VERSION ""

NS_ :

BS_:

BU_: FR_CMR FR_RDR

BO_ 452 L_FR_RDR_StationaryTrack4_50ms: 64 FR_RDR
 SG_ FLR_ST4_CrcVal : 0|16@1+ (1,0) [0|65535] ""  FR_CMR
 SG_ FLR_ST4_AlvCntVal : 16|8@1+ (1,0) [0|255] ""  FR_CMR
 SG_ FLR_ST4_Elevation : 24|3@1+ (1,0) [0|5] ""  FR_CMR
 SG_ FLR_ST4_ElevationConfidence : 27|2@1+ (1,0) [0|3] ""  FR_CMR
 SG_ FLR_ST4_Lifetime : 29|8@1+ (1,0) [0|255] "Cycles"  FR_CMR
 SG_ FLR_ST4_ObjectId : 37|16@1+ (1,0) [0|65535] ""  FR_CMR
 SG_ FLR_ST4_PositionX : 53|12@1+ (0.05,-3) [-3|200] "m"  FR_CMR
 SG_ FLR_ST4_PositionY : 65|12@1- (0.05,0) [-100|100] "m"  FR_CMR
 SG_ FLR_ST4_PredictionCounter : 77|8@1+ (1,0) [0|255] "Cycles"  FR_CMR
 SG_ FLR_ST4_PropertyBits : 85|3@1+ (1,0) [0|7] ""  FR_CMR
 SG_ FLR_ST4_Quality : 88|2@1+ (1,0) [0|3] ""  FR_CMR
 SG_ FLR_ST4_X_Velocity : 90|13@1- (0.05,0) [-120|120] "m/s"  FR_CMR
 SG_ FLR_ST4_Y_Velocity : 103|13@1- (0.05,0) [-120|120] "m/s"  FR_CMR

BO_ 453 L_FR_RDR_StationaryTrack5_50ms: 64 FR_RDR
 SG_ FLR_ST5_CrcVal : 0|16@1+ (1,0) [0|65535] ""  FR_CMR
 SG_ FLR_ST5_AlvCntVal : 16|8@1+ (1,0) [0|255] ""  FR_CMR
 SG_ FLR_ST5_Elevation : 24|3@1+ (1,0) [0|5] ""  FR_CMR
 SG_ FLR_ST5_ElevationConfidence : 27|2@1+ (1,0) [0|3] ""  FR_CMR
 SG_ FLR_ST5_Lifetime : 29|8@1+ (1,0) [0|255] "Cycles"  FR_CMR
 SG_ FLR_ST5_ObjectId : 37|16@1+ (1,0) [0|65535] ""  FR_CMR
 SG_ FLR_ST5_PositionX : 53|12@1+ (0.05,-3) [-3|200] "m"  FR_CMR
 SG_ FLR_ST5_PositionY : 65|12@1- (0.05,0) [-100|100] "m"  FR_CMR
 SG_ FLR_ST5_PredictionCounter : 77|8@1+ (1,0) [0|255] "Cycles"  FR_CMR
 SG_ FLR_ST5_PropertyBits : 85|3@1+ (1,0) [0|7] ""  FR_CMR
 SG_ FLR_ST5_Quality : 88|2@1+ (1,0) [0|3] ""  FR_CMR
 SG_ FLR_ST5_X_Velocity : 90|13@1- (0.05,0) [-120|120] "m/s"  FR_CMR
 SG_ FLR_ST5_Y_Velocity : 103|13@1- (0.05,0) [-120|120] "m/s"  FR_CMR

BO_ 454 L_FR_RDR_StationaryTrack6_50ms: 64 FR_RDR
 SG_ FLR_ST6_CrcVal : 0|16@1+ (1,0) [0|65535] ""  FR_CMR
 SG_ FLR_ST6_AlvCntVal : 16|8@1+ (1,0) [0|255] ""  FR_CMR
 SG_ FLR_ST6_Elevation : 24|3@1+ (1,0) [0|5] ""  FR_CMR
 SG_ FLR_ST6_ElevationConfidence : 27|2@1+ (1,0) [0|3] ""  FR_CMR
 SG_ FLR_ST6_Lifetime : 29|8@1+ (1,0) [0|255] "Cycles"  FR_CMR
 SG_ FLR_ST6_ObjectId : 37|16@1+ (1,0) [0|65535] ""  FR_CMR
 SG_ FLR_ST6_PositionX : 53|12@1+ (0.05,-3) [-3|200] "m"  FR_CMR
 SG_ FLR_ST6_PositionY : 65|12@1- (0.05,0) [-100|100] "m"  FR_CMR
 SG_ FLR_ST6_PredictionCounter : 77|8@1+ (1,0) [0|255] "Cycles"  FR_CMR
 SG_ FLR_ST6_PropertyBits : 85|3@1+ (1,0) [0|7] ""  FR_CMR
 SG_ FLR_ST6_Quality : 88|2@1+ (1,0) [0|3] ""  FR_CMR
 SG_ FLR_ST6_X_Velocity : 90|13@1- (0.05,0) [-120|120] "m/s"  FR_CMR
 SG_ FLR_ST6_Y_Velocity : 103|13@1- (0.05,0) [-120|120] "m/s"  FR_CMR

BO_ 455 L_FR_RDR_StationaryTrack7_50ms: 64 FR_RDR
 SG_ FLR_ST7_CrcVal : 0|16@1+ (1,0) [0|65535] ""  FR_CMR
 SG_ FLR_ST7_AlvCntVal : 16|8@1+ (1,0) [0|255] ""  FR_CMR
 SG_ FLR_ST7_Elevation : 24|3@1+ (1,0) [0|5] ""  FR_CMR
 SG_ FLR_ST7_ElevationConfidence : 27|2@1+ (1,0) [0|3] ""  FR_CMR
 SG_ FLR_ST7_Lifetime : 29|8@1+ (1,0) [0|255] "Cycles"  FR_CMR
 SG_ FLR_ST7_ObjectId : 37|16@1+ (1,0) [0|65535] ""  FR_CMR
 SG_ FLR_ST7_PositionX : 53|12@1+ (0.05,-3) [-3|200] "m"  FR_CMR
 SG_ FLR_ST7_PositionY : 65|12@1- (0.05,0) [-100|100] "m"  FR_CMR
 SG_ FLR_ST7_PredictionCounter : 77|8@1+ (1,0) [0|255] "Cycles"  FR_CMR
 SG_ FLR_ST7_PropertyBits : 85|3@1+ (1,0) [0|7] ""  FR_CMR
 SG_ FLR_ST7_Quality : 88|2@1+ (1,0) [0|3] ""  FR_CMR
 SG_ FLR_ST7_X_Velocity : 90|13@1- (0.05,0) [-120|120] "m/s"  FR_CMR
 SG_ FLR_ST7_Y_Velocity : 103|13@1- (0.05,0) [-120|120] "m/s"  FR_CMR

BO_ 456 L_FR_RDR_StationaryTrack8_50ms: 64 FR_RDR
 SG_ FLR_ST8_CrcVal : 0|16@1+ (1,0) [0|65535] ""  FR_CMR
 SG_ FLR_ST8_AlvCntVal : 16|8@1+ (1,0) [0|255] ""  FR_CMR
 SG_ FLR_ST8_Elevation : 24|3@1+ (1,0) [0|5] ""  FR_CMR
 SG_ FLR_ST8_ElevationConfidence : 27|2@1+ (1,0) [0|3] ""  FR_CMR
 SG_ FLR_ST8_Lifetime : 29|8@1+ (1,0) [0|255] "Cycles"  FR_CMR
 SG_ FLR_ST8_ObjectId : 37|16@1+ (1,0) [0|65535] ""  FR_CMR
 SG_ FLR_ST8_PositionX : 53|12@1+ (0.05,-3) [-3|200] "m"  FR_CMR
 SG_ FLR_ST8_PositionY : 65|12@1- (0.05,0) [-100|100] "m"  FR_CMR
 SG_ FLR_ST8_PredictionCounter : 77|8@1+ (1,0) [0|255] "Cycles"  FR_CMR
 SG_ FLR_ST8_PropertyBits : 85|3@1+ (1,0) [0|7] ""  FR_CMR
 SG_ FLR_ST8_Quality : 88|2@1+ (1,0) [0|3] ""  FR_CMR
 SG_ FLR_ST8_X_Velocity : 90|13@1- (0.05,0) [-120|120] "m/s"  FR_CMR
 SG_ FLR_ST8_Y_Velocity : 103|13@1- (0.05,0) [-120|120] "m/s"  FR_CMR

BO_ 457 L_FR_RDR_StationaryTrack9_50ms: 64 FR_RDR
 SG_ FLR_ST9_CrcVal : 0|16@1+ (1,0) [0|65535] ""  FR_CMR
 SG_ FLR_ST9_AlvCntVal : 16|8@1+ (1,0) [0|255] ""  FR_CMR
 SG_ FLR_ST9_Elevation : 24|3@1+ (1,0) [0|5] ""  FR_CMR
 SG_ FLR_ST9_ElevationConfidence : 27|2@1+ (1,0) [0|3] ""  FR_CMR
 SG_ FLR_ST9_Lifetime : 29|8@1+ (1,0) [0|255] "Cycles"  FR_CMR
 SG_ FLR_ST9_ObjectId : 37|16@1+ (1,0) [0|65535] ""  FR_CMR
 SG_ FLR_ST9_PositionX : 53|12@1+ (0.05,-3) [-3|200] "m"  FR_CMR
 SG_ FLR_ST9_PositionY : 65|12@1- (0.05,0) [-100|100] "m"  FR_CMR
 SG_ FLR_ST9_PredictionCounter : 77|8@1+ (1,0) [0|255] "Cycles"  FR_CMR
 SG_ FLR_ST9_PropertyBits : 85|3@1+ (1,0) [0|7] ""  FR_CMR
 SG_ FLR_ST9_Quality : 88|2@1+ (1,0) [0|3] ""  FR_CMR
 SG_ FLR_ST9_X_Velocity : 90|13@1- (0.05,0) [-120|120] "m/s"  FR_CMR
 SG_ FLR_ST9_Y_Velocity : 103|13@1- (0.05,0) [-120|120] "m/s"  FR_CMR

BO_ 458 L_FR_RDR_StationaryTrack10_50ms: 64 FR_RDR
 SG_ FLR_ST10_CrcVal : 0|16@1+ (1,0) [0|65535] ""  FR_CMR
 SG_ FLR_ST10_AlvCntVal : 16|8@1+ (1,0) [0|255] ""  FR_CMR
 SG_ FLR_ST10_Elevation : 24|3@1+ (1,0) [0|5] ""  FR_CMR
 SG_ FLR_ST10_ElevationConfidence : 27|2@1+ (1,0) [0|3] ""  FR_CMR
 SG_ FLR_ST10_Lifetime : 29|8@1+ (1,0) [0|255] "Cycles"  FR_CMR
 SG_ FLR_ST10_ObjectId : 37|16@1+ (1,0) [0|65535] ""  FR_CMR
 SG_ FLR_ST10_PositionX : 53|12@1+ (0.05,-3) [-3|200] "m"  FR_CMR
 SG_ FLR_ST10_PositionY : 65|12@1- (0.05,0) [-100|100] "m"  FR_CMR
 SG_ FLR_ST10_PredictionCounter : 77|8@1+ (1,0) [0|255] "Cycles"  FR_CMR
 SG_ FLR_ST10_PropertyBits : 85|3@1+ (1,0) [0|7] ""  FR_CMR
 SG_ FLR_ST10_Quality : 88|2@1+ (1,0) [0|3] ""  FR_CMR
 SG_ FLR_ST10_X_Velocity : 90|13@1- (0.05,0) [-120|120] "m/s"  FR_CMR
 SG_ FLR_ST10_Y_Velocity : 103|13@1- (0.05,0) [-120|120] "m/s"  FR_CMR

BO_ 459 L_FR_RDR_StationaryTrack11_50ms: 64 FR_RDR
 SG_ FLR_ST11_CrcVal : 0|16@1+ (1,0) [0|65535] ""  FR_CMR
 SG_ FLR_ST11_AlvCntVal : 16|8@1+ (1,0) [0|255] ""  FR_CMR
 SG_ FLR_ST11_Elevation : 24|3@1+ (1,0) [0|5] ""  FR_CMR
 SG_ FLR_ST11_ElevationConfidence : 27|2@1+ (1,0) [0|3] ""  FR_CMR
 SG_ FLR_ST11_Lifetime : 29|8@1+ (1,0) [0|255] "Cycles"  FR_CMR
 SG_ FLR_ST11_ObjectId : 37|16@1+ (1,0) [0|65535] ""  FR_CMR
 SG_ FLR_ST11_PositionX : 53|12@1+ (0.05,-3) [-3|200] "m"  FR_CMR
 SG_ FLR_ST11_PositionY : 65|12@1- (0.05,0) [-100|100] "m"  FR_CMR
 SG_ FLR_ST11_PredictionCounter : 77|8@1+ (1,0) [0|255] "Cycles"  FR_CMR
 SG_ FLR_ST11_PropertyBits : 85|3@1+ (1,0) [0|7] ""  FR_CMR
 SG_ FLR_ST11_Quality : 88|2@1+ (1,0) [0|3] ""  FR_CMR
 SG_ FLR_ST11_X_Velocity : 90|13@1- (0.05,0) [-120|120] "m/s"  FR_CMR
 SG_ FLR_ST11_Y_Velocity : 103|13@1- (0.05,0) [-120|120] "m/s"  FR_CMR

BO_ 460 L_FR_RDR_StationaryTrack12_50ms: 64 FR_RDR
 SG_ FLR_ST12_CrcVal : 0|16@1+ (1,0) [0|65535] ""  FR_CMR
 SG_ FLR_ST12_AlvCntVal : 16|8@1+ (1,0) [0|255] ""  FR_CMR
 SG_ FLR_ST12_Elevation : 24|3@1+ (1,0) [0|5] ""  FR_CMR
 SG_ FLR_ST12_ElevationConfidence : 27|2@1+ (1,0) [0|3] ""  FR_CMR
 SG_ FLR_ST12_Lifetime : 29|8@1+ (1,0) [0|255] "Cycles"  FR_CMR
 SG_ FLR_ST12_ObjectId : 37|16@1+ (1,0) [0|65535] ""  FR_CMR
 SG_ FLR_ST12_PositionX : 53|12@1+ (0.05,-3) [-3|200] "m"  FR_CMR
 SG_ FLR_ST12_PositionY : 65|12@1- (0.05,0) [-100|100] "m"  FR_CMR
 SG_ FLR_ST12_PredictionCounter : 77|8@1+ (1,0) [0|255] "Cycles"  FR_CMR
 SG_ FLR_ST12_PropertyBits : 85|3@1+ (1,0) [0|7] ""  FR_CMR
 SG_ FLR_ST12_Quality : 88|2@1+ (1,0) [0|3] ""  FR_CMR
 SG_ FLR_ST12_X_Velocity : 90|13@1- (0.05,0) [-120|120] "m/s"  FR_CMR
 SG_ FLR_ST12_Y_Velocity : 103|13@1- (0.05,0) [-120|120] "m/s"  FR_CMR

BO_ 461 L_FR_RDR_StationaryTrack13_50ms: 64 FR_RDR
 SG_ FLR_ST13_CrcVal : 0|16@1+ (1,0) [0|65535] ""  FR_CMR
 SG_ FLR_ST13_AlvCntVal : 16|8@1+ (1,0) [0|255] ""  FR_CMR
 SG_ FLR_ST13_Elevation : 24|3@1+ (1,0) [0|5] ""  FR_CMR
 SG_ FLR_ST13_ElevationConfidence : 27|2@1+ (1,0) [0|3] ""  FR_CMR
 SG_ FLR_ST13_Lifetime : 29|8@1+ (1,0) [0|255] "Cycles"  FR_CMR
 SG_ FLR_ST13_ObjectId : 37|16@1+ (1,0) [0|65535] ""  FR_CMR
 SG_ FLR_ST13_PositionX : 53|12@1+ (0.05,-3) [-3|200] "m"  FR_CMR
 SG_ FLR_ST13_PositionY : 65|12@1- (0.05,0) [-100|100] "m"  FR_CMR
 SG_ FLR_ST13_PredictionCounter : 77|8@1+ (1,0) [0|255] "Cycles"  FR_CMR
 SG_ FLR_ST13_PropertyBits : 85|3@1+ (1,0) [0|7] ""  FR_CMR
 SG_ FLR_ST13_Quality : 88|2@1+ (1,0) [0|3] ""  FR_CMR
 SG_ FLR_ST13_X_Velocity : 90|13@1- (0.05,0) [-120|120] "m/s"  FR_CMR
 SG_ FLR_ST13_Y_Velocity : 103|13@1- (0.05,0) [-120|120] "m/s"  FR_CMR

BO_ 462 L_FR_RDR_StationaryTrack14_50ms: 64 FR_RDR
 SG_ FLR_ST14_CrcVal : 0|16@1+ (1,0) [0|65535] ""  FR_CMR
 SG_ FLR_ST14_AlvCntVal : 16|8@1+ (1,0) [0|255] ""  FR_CMR
 SG_ FLR_ST14_Elevation : 24|3@1+ (1,0) [0|5] ""  FR_CMR
 SG_ FLR_ST14_ElevationConfidence : 27|2@1+ (1,0) [0|3] ""  FR_CMR
 SG_ FLR_ST14_Lifetime : 29|8@1+ (1,0) [0|255] "Cycles"  FR_CMR
 SG_ FLR_ST14_ObjectId : 37|16@1+ (1,0) [0|65535] ""  FR_CMR
 SG_ FLR_ST14_PositionX : 53|12@1+ (0.05,-3) [-3|200] "m"  FR_CMR
 SG_ FLR_ST14_PositionY : 65|12@1- (0.05,0) [-100|100] "m"  FR_CMR
 SG_ FLR_ST14_PredictionCounter : 77|8@1+ (1,0) [0|255] "Cycles"  FR_CMR
 SG_ FLR_ST14_PropertyBits : 85|3@1+ (1,0) [0|7] ""  FR_CMR
 SG_ FLR_ST14_Quality : 88|2@1+ (1,0) [0|3] ""  FR_CMR
 SG_ FLR_ST14_X_Velocity : 90|13@1- (0.05,0) [-120|120] "m/s"  FR_CMR
 SG_ FLR_ST14_Y_Velocity : 103|13@1- (0.05,0) [-120|120] "m/s"  FR_CMR

BO_ 463 L_FR_RDR_StationaryTrack15_50ms: 64 FR_RDR
 SG_ FLR_ST15_CrcVal : 0|16@1+ (1,0) [0|65535] ""  FR_CMR
 SG_ FLR_ST15_AlvCntVal : 16|8@1+ (1,0) [0|255] ""  FR_CMR
 SG_ FLR_ST15_Elevation : 24|3@1+ (1,0) [0|5] ""  FR_CMR
 SG_ FLR_ST15_ElevationConfidence : 27|2@1+ (1,0) [0|3] ""  FR_CMR
 SG_ FLR_ST15_Lifetime : 29|8@1+ (1,0) [0|255] "Cycles"  FR_CMR
 SG_ FLR_ST15_ObjectId : 37|16@1+ (1,0) [0|65535] ""  FR_CMR
 SG_ FLR_ST15_PositionX : 53|12@1+ (0.05,-3) [-3|200] "m"  FR_CMR
 SG_ FLR_ST15_PositionY : 65|12@1- (0.05,0) [-100|100] "m"  FR_CMR
 SG_ FLR_ST15_PredictionCounter : 77|8@1+ (1,0) [0|255] "Cycles"  FR_CMR
 SG_ FLR_ST15_PropertyBits : 85|3@1+ (1,0) [0|7] ""  FR_CMR
 SG_ FLR_ST15_Quality : 88|2@1+ (1,0) [0|3] ""  FR_CMR
 SG_ FLR_ST15_X_Velocity : 90|13@1- (0.05,0) [-120|120] "m/s"  FR_CMR
 SG_ FLR_ST15_Y_Velocity : 103|13@1- (0.05,0) [-120|120] "m/s"  FR_CMR

BO_ 464 L_FR_RDR_StationaryTrack16_50ms: 64 FR_RDR
 SG_ FLR_ST16_CrcVal : 0|16@1+ (1,0) [0|65535] ""  FR_CMR
 SG_ FLR_ST16_AlvCntVal : 16|8@1+ (1,0) [0|255] ""  FR_CMR
 SG_ FLR_ST16_Elevation : 24|3@1+ (1,0) [0|5] ""  FR_CMR
 SG_ FLR_ST16_ElevationConfidence : 27|2@1+ (1,0) [0|3] ""  FR_CMR
 SG_ FLR_ST16_Lifetime : 29|8@1+ (1,0) [0|255] "Cycles"  FR_CMR
 SG_ FLR_ST16_ObjectId : 37|16@1+ (1,0) [0|65535] ""  FR_CMR
 SG_ FLR_ST16_PositionX : 53|12@1+ (0.05,-3) [-3|200] "m"  FR_CMR
 SG_ FLR_ST16_PositionY : 65|12@1- (0.05,0) [-100|100] "m"  FR_CMR
 SG_ FLR_ST16_PredictionCounter : 77|8@1+ (1,0) [0|255] "Cycles"  FR_CMR
 SG_ FLR_ST16_PropertyBits : 85|3@1+ (1,0) [0|7] ""  FR_CMR
 SG_ FLR_ST16_Quality : 88|2@1+ (1,0) [0|3] ""  FR_CMR
 SG_ FLR_ST16_X_Velocity : 90|13@1- (0.05,0) [-120|120] "m/s"  FR_CMR
 SG_ FLR_ST16_Y_Velocity : 103|13@1- (0.05,0) [-120|120] "m/s"  FR_CMR

BO_ 465 L_FR_RDR_StationaryTrack17_50ms: 64 FR_RDR
 SG_ FLR_ST17_CrcVal : 0|16@1+ (1,0) [0|65535] ""  FR_CMR
 SG_ FLR_ST17_AlvCntVal : 16|8@1+ (1,0) [0|255] ""  FR_CMR
 SG_ FLR_ST17_Elevation : 24|3@1+ (1,0) [0|5] ""  FR_CMR
 SG_ FLR_ST17_ElevationConfidence : 27|2@1+ (1,0) [0|3] ""  FR_CMR
 SG_ FLR_ST17_Lifetime : 29|8@1+ (1,0) [0|255] "Cycles"  FR_CMR
 SG_ FLR_ST17_ObjectId : 37|16@1+ (1,0) [0|65535] ""  FR_CMR
 SG_ FLR_ST17_PositionX : 53|12@1+ (0.05,-3) [-3|200] "m"  FR_CMR
 SG_ FLR_ST17_PositionY : 65|12@1- (0.05,0) [-100|100] "m"  FR_CMR
 SG_ FLR_ST17_PredictionCounter : 77|8@1+ (1,0) [0|255] "Cycles"  FR_CMR
 SG_ FLR_ST17_PropertyBits : 85|3@1+ (1,0) [0|7] ""  FR_CMR
 SG_ FLR_ST17_Quality : 88|2@1+ (1,0) [0|3] ""  FR_CMR
 SG_ FLR_ST17_X_Velocity : 90|13@1- (0.05,0) [-120|120] "m/s"  FR_CMR
 SG_ FLR_ST17_Y_Velocity : 103|13@1- (0.05,0) [-120|120] "m/s"  FR_CMR

BO_ 466 L_FR_RDR_StationaryTrack18_50ms: 64 FR_RDR
 SG_ FLR_ST18_CrcVal : 0|16@1+ (1,0) [0|65535] ""  FR_CMR
 SG_ FLR_ST18_AlvCntVal : 16|8@1+ (1,0) [0|255] ""  FR_CMR
 SG_ FLR_ST18_Elevation : 24|3@1+ (1,0) [0|5] ""  FR_CMR
 SG_ FLR_ST18_ElevationConfidence : 27|2@1+ (1,0) [0|3] ""  FR_CMR
 SG_ FLR_ST18_Lifetime : 29|8@1+ (1,0) [0|255] "Cycles"  FR_CMR
 SG_ FLR_ST18_ObjectId : 37|16@1+ (1,0) [0|65535] ""  FR_CMR
 SG_ FLR_ST18_PositionX : 53|12@1+ (0.05,-3) [-3|200] "m"  FR_CMR
 SG_ FLR_ST18_PositionY : 65|12@1- (0.05,0) [-100|100] "m"  FR_CMR
 SG_ FLR_ST18_PredictionCounter : 77|8@1+ (1,0) [0|255] "Cycles"  FR_CMR
 SG_ FLR_ST18_PropertyBits : 85|3@1+ (1,0) [0|7] ""  FR_CMR
 SG_ FLR_ST18_Quality : 88|2@1+ (1,0) [0|3] ""  FR_CMR
 SG_ FLR_ST18_X_Velocity : 90|13@1- (0.05,0) [-120|120] "m/s"  FR_CMR
 SG_ FLR_ST18_Y_Velocity : 103|13@1- (0.05,0) [-120|120] "m/s"  FR_CMR

BO_ 467 L_FR_RDR_StationaryTrack19_50ms: 64 FR_RDR
 SG_ FLR_ST19_CrcVal : 0|16@1+ (1,0) [0|65535] ""  FR_CMR
 SG_ FLR_ST19_AlvCntVal : 16|8@1+ (1,0) [0|255] ""  FR_CMR
 SG_ FLR_ST19_Elevation : 24|3@1+ (1,0) [0|5] ""  FR_CMR
 SG_ FLR_ST19_ElevationConfidence : 27|2@1+ (1,0) [0|3] ""  FR_CMR
 SG_ FLR_ST19_Lifetime : 29|8@1+ (1,0) [0|255] "Cycles"  FR_CMR
 SG_ FLR_ST19_ObjectId : 37|16@1+ (1,0) [0|65535] ""  FR_CMR
 SG_ FLR_ST19_PositionX : 53|12@1+ (0.05,-3) [-3|200] "m"  FR_CMR
 SG_ FLR_ST19_PositionY : 65|12@1- (0.05,0) [-100|100] "m"  FR_CMR
 SG_ FLR_ST19_PredictionCounter : 77|8@1+ (1,0) [0|255] "Cycles"  FR_CMR
 SG_ FLR_ST19_PropertyBits : 85|3@1+ (1,0) [0|7] ""  FR_CMR
 SG_ FLR_ST19_Quality : 88|2@1+ (1,0) [0|3] ""  FR_CMR
 SG_ FLR_ST19_X_Velocity : 90|13@1- (0.05,0) [-120|120] "m/s"  FR_CMR
 SG_ FLR_ST19_Y_Velocity : 103|13@1- (0.05,0) [-120|120] "m/s"  FR_CMR

BO_ 468 L_FR_RDR_StationaryTrack20_50ms: 64 FR_RDR
 SG_ FLR_ST20_CrcVal : 0|16@1+ (1,0) [0|65535] ""  FR_CMR
 SG_ FLR_ST20_AlvCntVal : 16|8@1+ (1,0) [0|255] ""  FR_CMR
 SG_ FLR_ST20_Elevation : 24|3@1+ (1,0) [0|5] ""  FR_CMR
 SG_ FLR_ST20_ElevationConfidence : 27|2@1+ (1,0) [0|3] ""  FR_CMR
 SG_ FLR_ST20_Lifetime : 29|8@1+ (1,0) [0|255] "Cycles"  FR_CMR
 SG_ FLR_ST20_ObjectId : 37|16@1+ (1,0) [0|65535] ""  FR_CMR
 SG_ FLR_ST20_PositionX : 53|12@1+ (0.05,-3) [-3|200] "m"  FR_CMR
 SG_ FLR_ST20_PositionY : 65|12@1- (0.05,0) [-100|100] "m"  FR_CMR
 SG_ FLR_ST20_PredictionCounter : 77|8@1+ (1,0) [0|255] "Cycles"  FR_CMR
 SG_ FLR_ST20_PropertyBits : 85|3@1+ (1,0) [0|7] ""  FR_CMR
 SG_ FLR_ST20_Quality : 88|2@1+ (1,0) [0|3] ""  FR_CMR
 SG_ FLR_ST20_X_Velocity : 90|13@1- (0.05,0) [-120|120] "m/s"  FR_CMR
 SG_ FLR_ST20_Y_Velocity : 103|13@1- (0.05,0) [-120|120] "m/s"  FR_CMR

BO_ 469 L_FR_RDR_StationaryTrack21_50ms: 64 FR_RDR
 SG_ FLR_ST21_CrcVal : 0|16@1+ (1,0) [0|65535] ""  FR_CMR
 SG_ FLR_ST21_AlvCntVal : 16|8@1+ (1,0) [0|255] ""  FR_CMR
 SG_ FLR_ST21_Elevation : 24|3@1+ (1,0) [0|5] ""  FR_CMR
 SG_ FLR_ST21_ElevationConfidence : 27|2@1+ (1,0) [0|3] ""  FR_CMR
 SG_ FLR_ST21_Lifetime : 29|8@1+ (1,0) [0|255] "Cycles"  FR_CMR
 SG_ FLR_ST21_ObjectId : 37|16@1+ (1,0) [0|65535] ""  FR_CMR
 SG_ FLR_ST21_PositionX : 53|12@1+ (0.05,-3) [-3|200] "m"  FR_CMR
 SG_ FLR_ST21_PositionY : 65|12@1- (0.05,0) [-100|100] "m"  FR_CMR
 SG_ FLR_ST21_PredictionCounter : 77|8@1+ (1,0) [0|255] "Cycles"  FR_CMR
 SG_ FLR_ST21_PropertyBits : 85|3@1+ (1,0) [0|7] ""  FR_CMR
 SG_ FLR_ST21_Quality : 88|2@1+ (1,0) [0|3] ""  FR_CMR
 SG_ FLR_ST21_X_Velocity : 90|13@1- (0.05,0) [-120|120] "m/s"  FR_CMR
 SG_ FLR_ST21_Y_Velocity : 103|13@1- (0.05,0) [-120|120] "m/s"  FR_CMR

BO_ 470 L_FR_RDR_StationaryTrack22_50ms: 64 FR_RDR
 SG_ FLR_ST22_CrcVal : 0|16@1+ (1,0) [0|65535] ""  FR_CMR
 SG_ FLR_ST22_AlvCntVal : 16|8@1+ (1,0) [0|255] ""  FR_CMR
 SG_ FLR_ST22_Elevation : 24|3@1+ (1,0) [0|5] ""  FR_CMR
 SG_ FLR_ST22_ElevationConfidence : 27|2@1+ (1,0) [0|3] ""  FR_CMR
 SG_ FLR_ST22_Lifetime : 29|8@1+ (1,0) [0|255] "Cycles"  FR_CMR
 SG_ FLR_ST22_ObjectId : 37|16@1+ (1,0) [0|65535] ""  FR_CMR
 SG_ FLR_ST22_PositionX : 53|12@1+ (0.05,-3) [-3|200] "m"  FR_CMR
 SG_ FLR_ST22_PositionY : 65|12@1- (0.05,0) [-100|100] "m"  FR_CMR
 SG_ FLR_ST22_PredictionCounter : 77|8@1+ (1,0) [0|255] "Cycles"  FR_CMR
 SG_ FLR_ST22_PropertyBits : 85|3@1+ (1,0) [0|7] ""  FR_CMR
 SG_ FLR_ST22_Quality : 88|2@1+ (1,0) [0|3] ""  FR_CMR
 SG_ FLR_ST22_X_Velocity : 90|13@1- (0.05,0) [-120|120] "m/s"  FR_CMR
 SG_ FLR_ST22_Y_Velocity : 103|13@1- (0.05,0) [-120|120] "m/s"  FR_CMR

BO_ 471 L_FR_RDR_StationaryTrack23_50ms: 64 FR_RDR
 SG_ FLR_ST23_CrcVal : 0|16@1+ (1,0) [0|65535] ""  FR_CMR
 SG_ FLR_ST23_AlvCntVal : 16|8@1+ (1,0) [0|255] ""  FR_CMR
 SG_ FLR_ST23_Elevation : 24|3@1+ (1,0) [0|5] ""  FR_CMR
 SG_ FLR_ST23_ElevationConfidence : 27|2@1+ (1,0) [0|3] ""  FR_CMR
 SG_ FLR_ST23_Lifetime : 29|8@1+ (1,0) [0|255] "Cycles"  FR_CMR
 SG_ FLR_ST23_ObjectId : 37|16@1+ (1,0) [0|65535] ""  FR_CMR
 SG_ FLR_ST23_PositionX : 53|12@1+ (0.05,-3) [-3|200] "m"  FR_CMR
 SG_ FLR_ST23_PositionY : 65|12@1- (0.05,0) [-100|100] "m"  FR_CMR
 SG_ FLR_ST23_PredictionCounter : 77|8@1+ (1,0) [0|255] "Cycles"  FR_CMR
 SG_ FLR_ST23_PropertyBits : 85|3@1+ (1,0) [0|7] ""  FR_CMR
 SG_ FLR_ST23_Quality : 88|2@1+ (1,0) [0|3] ""  FR_CMR
 SG_ FLR_ST23_X_Velocity : 90|13@1- (0.05,0) [-120|120] "m/s"  FR_CMR
 SG_ FLR_ST23_Y_Velocity : 103|13@1- (0.05,0) [-120|120] "m/s"  FR_CMR

BO_ 472 L_FR_RDR_StationaryTrack24_50ms: 64 FR_RDR
 SG_ FLR_ST24_CrcVal : 0|16@1+ (1,0) [0|65535] ""  FR_CMR
 SG_ FLR_ST24_AlvCntVal : 16|8@1+ (1,0) [0|255] ""  FR_CMR
 SG_ FLR_ST24_Elevation : 24|3@1+ (1,0) [0|5] ""  FR_CMR
 SG_ FLR_ST24_ElevationConfidence : 27|2@1+ (1,0) [0|3] ""  FR_CMR
 SG_ FLR_ST24_Lifetime : 29|8@1+ (1,0) [0|255] "Cycles"  FR_CMR
 SG_ FLR_ST24_ObjectId : 37|16@1+ (1,0) [0|65535] ""  FR_CMR
 SG_ FLR_ST24_PositionX : 53|12@1+ (0.05,-3) [-3|200] "m"  FR_CMR
 SG_ FLR_ST24_PositionY : 65|12@1- (0.05,0) [-100|100] "m"  FR_CMR
 SG_ FLR_ST24_PredictionCounter : 77|8@1+ (1,0) [0|255] "Cycles"  FR_CMR
 SG_ FLR_ST24_PropertyBits : 85|3@1+ (1,0) [0|7] ""  FR_CMR
 SG_ FLR_ST24_Quality : 88|2@1+ (1,0) [0|3] ""  FR_CMR
 SG_ FLR_ST24_X_Velocity : 90|13@1- (0.05,0) [-120|120] "m/s"  FR_CMR
 SG_ FLR_ST24_Y_Velocity : 103|13@1- (0.05,0) [-120|120] "m/s"  FR_CMR

BO_ 473 L_FR_RDR_StationaryTrack25_50ms: 64 FR_RDR
 SG_ FLR_ST25_CrcVal : 0|16@1+ (1,0) [0|65535] ""  FR_CMR
 SG_ FLR_ST25_AlvCntVal : 16|8@1+ (1,0) [0|255] ""  FR_CMR
 SG_ FLR_ST25_Elevation : 24|3@1+ (1,0) [0|5] ""  FR_CMR
 SG_ FLR_ST25_ElevationConfidence : 27|2@1+ (1,0) [0|3] ""  FR_CMR
 SG_ FLR_ST25_Lifetime : 29|8@1+ (1,0) [0|255] "Cycles"  FR_CMR
 SG_ FLR_ST25_ObjectId : 37|16@1+ (1,0) [0|65535] ""  FR_CMR
 SG_ FLR_ST25_PositionX : 53|12@1+ (0.05,-3) [-3|200] "m"  FR_CMR
 SG_ FLR_ST25_PositionY : 65|12@1- (0.05,0) [-100|100] "m"  FR_CMR
 SG_ FLR_ST25_PredictionCounter : 77|8@1+ (1,0) [0|255] "Cycles"  FR_CMR
 SG_ FLR_ST25_PropertyBits : 85|3@1+ (1,0) [0|7] ""  FR_CMR
 SG_ FLR_ST25_Quality : 88|2@1+ (1,0) [0|3] ""  FR_CMR
 SG_ FLR_ST25_X_Velocity : 90|13@1- (0.05,0) [-120|120] "m/s"  FR_CMR
 SG_ FLR_ST25_Y_Velocity : 103|13@1- (0.05,0) [-120|120] "m/s"  FR_CMR

BO_ 474 L_FR_RDR_StationaryTrack26_50ms: 64 FR_RDR
 SG_ FLR_ST26_CrcVal : 0|16@1+ (1,0) [0|65535] ""  FR_CMR
 SG_ FLR_ST26_AlvCntVal : 16|8@1+ (1,0) [0|255] ""  FR_CMR
 SG_ FLR_ST26_Elevation : 24|3@1+ (1,0) [0|5] ""  FR_CMR
 SG_ FLR_ST26_ElevationConfidence : 27|2@1+ (1,0) [0|3] ""  FR_CMR
 SG_ FLR_ST26_Lifetime : 29|8@1+ (1,0) [0|255] "Cycles"  FR_CMR
 SG_ FLR_ST26_ObjectId : 37|16@1+ (1,0) [0|65535] ""  FR_CMR
 SG_ FLR_ST26_PositionX : 53|12@1+ (0.05,-3) [-3|200] "m"  FR_CMR
 SG_ FLR_ST26_PositionY : 65|12@1- (0.05,0) [-100|100] "m"  FR_CMR
 SG_ FLR_ST26_PredictionCounter : 77|8@1+ (1,0) [0|255] "Cycles"  FR_CMR
 SG_ FLR_ST26_PropertyBits : 85|3@1+ (1,0) [0|7] ""  FR_CMR
 SG_ FLR_ST26_Quality : 88|2@1+ (1,0) [0|3] ""  FR_CMR
 SG_ FLR_ST26_X_Velocity : 90|13@1- (0.05,0) [-120|120] "m/s"  FR_CMR
 SG_ FLR_ST26_Y_Velocity : 103|13@1- (0.05,0) [-120|120] "m/s"  FR_CMR

BO_ 475 L_FR_RDR_StationaryTrack27_50ms: 64 FR_RDR
 SG_ FLR_ST27_CrcVal : 0|16@1+ (1,0) [0|65535] ""  FR_CMR
 SG_ FLR_ST27_AlvCntVal : 16|8@1+ (1,0) [0|255] ""  FR_CMR
 SG_ FLR_ST27_Elevation : 24|3@1+ (1,0) [0|5] ""  FR_CMR
 SG_ FLR_ST27_ElevationConfidence : 27|2@1+ (1,0) [0|3] ""  FR_CMR
 SG_ FLR_ST27_Lifetime : 29|8@1+ (1,0) [0|255] "Cycles"  FR_CMR
 SG_ FLR_ST27_ObjectId : 37|16@1+ (1,0) [0|65535] ""  FR_CMR
 SG_ FLR_ST27_PositionX : 53|12@1+ (0.05,-3) [-3|200] "m"  FR_CMR
 SG_ FLR_ST27_PositionY : 65|12@1- (0.05,0) [-100|100] "m"  FR_CMR
 SG_ FLR_ST27_PredictionCounter : 77|8@1+ (1,0) [0|255] "Cycles"  FR_CMR
 SG_ FLR_ST27_PropertyBits : 85|3@1+ (1,0) [0|7] ""  FR_CMR
 SG_ FLR_ST27_Quality : 88|2@1+ (1,0) [0|3] ""  FR_CMR
 SG_ FLR_ST27_X_Velocity : 90|13@1- (0.05,0) [-120|120] "m/s"  FR_CMR
 SG_ FLR_ST27_Y_Velocity : 103|13@1- (0.05,0) [-120|120] "m/s"  FR_CMR

BO_ 476 L_FR_RDR_StationaryTrack28_50ms: 64 FR_RDR
 SG_ FLR_ST28_CrcVal : 0|16@1+ (1,0) [0|65535] ""  FR_CMR
 SG_ FLR_ST28_AlvCntVal : 16|8@1+ (1,0) [0|255] ""  FR_CMR
 SG_ FLR_ST28_Elevation : 24|3@1+ (1,0) [0|5] ""  FR_CMR
 SG_ FLR_ST28_ElevationConfidence : 27|2@1+ (1,0) [0|3] ""  FR_CMR
 SG_ FLR_ST28_Lifetime : 29|8@1+ (1,0) [0|255] "Cycles"  FR_CMR
 SG_ FLR_ST28_ObjectId : 37|16@1+ (1,0) [0|65535] ""  FR_CMR
 SG_ FLR_ST28_PositionX : 53|12@1+ (0.05,-3) [-3|200] "m"  FR_CMR
 SG_ FLR_ST28_PositionY : 65|12@1- (0.05,0) [-100|100] "m"  FR_CMR
 SG_ FLR_ST28_PredictionCounter : 77|8@1+ (1,0) [0|255] "Cycles"  FR_CMR
 SG_ FLR_ST28_PropertyBits : 85|3@1+ (1,0) [0|7] ""  FR_CMR
 SG_ FLR_ST28_Quality : 88|2@1+ (1,0) [0|3] ""  FR_CMR
 SG_ FLR_ST28_X_Velocity : 90|13@1- (0.05,0) [-120|120] "m/s"  FR_CMR
 SG_ FLR_ST28_Y_Velocity : 103|13@1- (0.05,0) [-120|120] "m/s"  FR_CMR

BO_ 477 L_FR_RDR_StationaryTrack29_50ms: 64 FR_RDR
 SG_ FLR_ST29_CrcVal : 0|16@1+ (1,0) [0|65535] ""  FR_CMR
 SG_ FLR_ST29_AlvCntVal : 16|8@1+ (1,0) [0|255] ""  FR_CMR
 SG_ FLR_ST29_Elevation : 24|3@1+ (1,0) [0|5] ""  FR_CMR
 SG_ FLR_ST29_ElevationConfidence : 27|2@1+ (1,0) [0|3] ""  FR_CMR
 SG_ FLR_ST29_Lifetime : 29|8@1+ (1,0) [0|255] "Cycles"  FR_CMR
 SG_ FLR_ST29_ObjectId : 37|16@1+ (1,0) [0|65535] ""  FR_CMR
 SG_ FLR_ST29_PositionX : 53|12@1+ (0.05,-3) [-3|200] "m"  FR_CMR
 SG_ FLR_ST29_PositionY : 65|12@1- (0.05,0) [-100|100] "m"  FR_CMR
 SG_ FLR_ST29_PredictionCounter : 77|8@1+ (1,0) [0|255] "Cycles"  FR_CMR
 SG_ FLR_ST29_PropertyBits : 85|3@1+ (1,0) [0|7] ""  FR_CMR
 SG_ FLR_ST29_Quality : 88|2@1+ (1,0) [0|3] ""  FR_CMR
 SG_ FLR_ST29_X_Velocity : 90|13@1- (0.05,0) [-120|120] "m/s"  FR_CMR
 SG_ FLR_ST29_Y_Velocity : 103|13@1- (0.05,0) [-120|120] "m/s"  FR_CMR

BO_ 478 L_FR_RDR_StationaryTrack30_50ms: 64 FR_RDR
 SG_ FLR_ST30_CrcVal : 0|16@1+ (1,0) [0|65535] ""  FR_CMR
 SG_ FLR_ST30_AlvCntVal : 16|8@1+ (1,0) [0|255] ""  FR_CMR
 SG_ FLR_ST30_Elevation : 24|3@1+ (1,0) [0|5] ""  FR_CMR
 SG_ FLR_ST30_ElevationConfidence : 27|2@1+ (1,0) [0|3] ""  FR_CMR
 SG_ FLR_ST30_Lifetime : 29|8@1+ (1,0) [0|255] "Cycles"  FR_CMR
 SG_ FLR_ST30_ObjectId : 37|16@1+ (1,0) [0|65535] ""  FR_CMR
 SG_ FLR_ST30_PositionX : 53|12@1+ (0.05,-3) [-3|200] "m"  FR_CMR
 SG_ FLR_ST30_PositionY : 65|12@1- (0.05,0) [-100|100] "m"  FR_CMR
 SG_ FLR_ST30_PredictionCounter : 77|8@1+ (1,0) [0|255] "Cycles"  FR_CMR
 SG_ FLR_ST30_PropertyBits : 85|3@1+ (1,0) [0|7] ""  FR_CMR
 SG_ FLR_ST30_Quality : 88|2@1+ (1,0) [0|3] ""  FR_CMR
 SG_ FLR_ST30_X_Velocity : 90|13@1- (0.05,0) [-120|120] "m/s"  FR_CMR
 SG_ FLR_ST30_Y_Velocity : 103|13@1- (0.05,0) [-120|120] "m/s"  FR_CMR

BO_ 479 L_FR_RDR_StationaryTrack31_50ms: 64 FR_RDR
 SG_ FLR_ST31_CrcVal : 0|16@1+ (1,0) [0|65535] ""  FR_CMR
 SG_ FLR_ST31_AlvCntVal : 16|8@1+ (1,0) [0|255] ""  FR_CMR
 SG_ FLR_ST31_Elevation : 24|3@1+ (1,0) [0|5] ""  FR_CMR
 SG_ FLR_ST31_ElevationConfidence : 27|2@1+ (1,0) [0|3] ""  FR_CMR
 SG_ FLR_ST31_Lifetime : 29|8@1+ (1,0) [0|255] "Cycles"  FR_CMR
 SG_ FLR_ST31_ObjectId : 37|16@1+ (1,0) [0|65535] ""  FR_CMR
 SG_ FLR_ST31_PositionX : 53|12@1+ (0.05,-3) [-3|200] "m"  FR_CMR
 SG_ FLR_ST31_PositionY : 65|12@1- (0.05,0) [-100|100] "m"  FR_CMR
 SG_ FLR_ST31_PredictionCounter : 77|8@1+ (1,0) [0|255] "Cycles"  FR_CMR
 SG_ FLR_ST31_PropertyBits : 85|3@1+ (1,0) [0|7] ""  FR_CMR
 SG_ FLR_ST31_Quality : 88|2@1+ (1,0) [0|3] ""  FR_CMR
 SG_ FLR_ST31_X_Velocity : 90|13@1- (0.05,0) [-120|120] "m/s"  FR_CMR
 SG_ FLR_ST31_Y_Velocity : 103|13@1- (0.05,0) [-120|120] "m/s"  FR_CMR

BO_ 480 L_FR_RDR_StationaryTrack32_50ms: 64 FR_RDR
 SG_ FLR_ST32_CrcVal : 0|16@1+ (1,0) [0|65535] ""  FR_CMR
 SG_ FLR_ST32_AlvCntVal : 16|8@1+ (1,0) [0|255] ""  FR_CMR
 SG_ FLR_ST32_Elevation : 24|3@1+ (1,0) [0|5] ""  FR_CMR
 SG_ FLR_ST32_ElevationConfidence : 27|2@1+ (1,0) [0|3] ""  FR_CMR
 SG_ FLR_ST32_Lifetime : 29|8@1+ (1,0) [0|255] "Cycles"  FR_CMR
 SG_ FLR_ST32_ObjectId : 37|16@1+ (1,0) [0|65535] ""  FR_CMR
 SG_ FLR_ST32_PositionX : 53|12@1+ (0.05,-3) [-3|200] "m"  FR_CMR
 SG_ FLR_ST32_PositionY : 65|12@1- (0.05,0) [-100|100] "m"  FR_CMR
 SG_ FLR_ST32_PredictionCounter : 77|8@1+ (1,0) [0|255] "Cycles"  FR_CMR
 SG_ FLR_ST32_PropertyBits : 85|3@1+ (1,0) [0|7] ""  FR_CMR
 SG_ FLR_ST32_Quality : 88|2@1+ (1,0) [0|3] ""  FR_CMR
 SG_ FLR_ST32_X_Velocity : 90|13@1- (0.05,0) [-120|120] "m/s"  FR_CMR
 SG_ FLR_ST32_Y_Velocity : 103|13@1- (0.05,0) [-120|120] "m/s"  FR_CMR

BO_ 481 L_FR_RDR_StationaryTrack33_50ms: 64 FR_RDR
 SG_ FLR_ST33_CrcVal : 0|16@1+ (1,0) [0|65535] ""  FR_CMR
 SG_ FLR_ST33_AlvCntVal : 16|8@1+ (1,0) [0|255] ""  FR_CMR
 SG_ FLR_ST33_Elevation : 24|3@1+ (1,0) [0|5] ""  FR_CMR
 SG_ FLR_ST33_ElevationConfidence : 27|2@1+ (1,0) [0|3] ""  FR_CMR
 SG_ FLR_ST33_Lifetime : 29|8@1+ (1,0) [0|255] "Cycles"  FR_CMR
 SG_ FLR_ST33_ObjectId : 37|16@1+ (1,0) [0|65535] ""  FR_CMR
 SG_ FLR_ST33_PositionX : 53|12@1+ (0.05,-3) [-3|200] "m"  FR_CMR
 SG_ FLR_ST33_PositionY : 65|12@1- (0.05,0) [-100|100] "m"  FR_CMR
 SG_ FLR_ST33_PredictionCounter : 77|8@1+ (1,0) [0|255] "Cycles"  FR_CMR
 SG_ FLR_ST33_PropertyBits : 85|3@1+ (1,0) [0|7] ""  FR_CMR
 SG_ FLR_ST33_Quality : 88|2@1+ (1,0) [0|3] ""  FR_CMR
 SG_ FLR_ST33_X_Velocity : 90|13@1- (0.05,0) [-120|120] "m/s"  FR_CMR
 SG_ FLR_ST33_Y_Velocity : 103|13@1- (0.05,0) [-120|120] "m/s"  FR_CMR

BO_ 482 L_FR_RDR_StationaryTrack34_50ms: 64 FR_RDR
 SG_ FLR_ST34_CrcVal : 0|16@1+ (1,0) [0|65535] ""  FR_CMR
 SG_ FLR_ST34_AlvCntVal : 16|8@1+ (1,0) [0|255] ""  FR_CMR
 SG_ FLR_ST34_Elevation : 24|3@1+ (1,0) [0|5] ""  FR_CMR
 SG_ FLR_ST34_ElevationConfidence : 27|2@1+ (1,0) [0|3] ""  FR_CMR
 SG_ FLR_ST34_Lifetime : 29|8@1+ (1,0) [0|255] "Cycles"  FR_CMR
 SG_ FLR_ST34_ObjectId : 37|16@1+ (1,0) [0|65535] ""  FR_CMR
 SG_ FLR_ST34_PositionX : 53|12@1+ (0.05,-3) [-3|200] "m"  FR_CMR
 SG_ FLR_ST34_PositionY : 65|12@1- (0.05,0) [-100|100] "m"  FR_CMR
 SG_ FLR_ST34_PredictionCounter : 77|8@1+ (1,0) [0|255] "Cycles"  FR_CMR
 SG_ FLR_ST34_PropertyBits : 85|3@1+ (1,0) [0|7] ""  FR_CMR
 SG_ FLR_ST34_Quality : 88|2@1+ (1,0) [0|3] ""  FR_CMR
 SG_ FLR_ST34_X_Velocity : 90|13@1- (0.05,0) [-120|120] "m/s"  FR_CMR
 SG_ FLR_ST34_Y_Velocity : 103|13@1- (0.05,0) [-120|120] "m/s"  FR_CMR

BO_ 483 L_FR_RDR_StationaryTrack35_50ms: 64 FR_RDR
 SG_ FLR_ST35_CrcVal : 0|16@1+ (1,0) [0|65535] ""  FR_CMR
 SG_ FLR_ST35_AlvCntVal : 16|8@1+ (1,0) [0|255] ""  FR_CMR
 SG_ FLR_ST35_Elevation : 24|3@1+ (1,0) [0|5] ""  FR_CMR
 SG_ FLR_ST35_ElevationConfidence : 27|2@1+ (1,0) [0|3] ""  FR_CMR
 SG_ FLR_ST35_Lifetime : 29|8@1+ (1,0) [0|255] "Cycles"  FR_CMR
 SG_ FLR_ST35_ObjectId : 37|16@1+ (1,0) [0|65535] ""  FR_CMR
 SG_ FLR_ST35_PositionX : 53|12@1+ (0.05,-3) [-3|200] "m"  FR_CMR
 SG_ FLR_ST35_PositionY : 65|12@1- (0.05,0) [-100|100] "m"  FR_CMR
 SG_ FLR_ST35_PredictionCounter : 77|8@1+ (1,0) [0|255] "Cycles"  FR_CMR
 SG_ FLR_ST35_PropertyBits : 85|3@1+ (1,0) [0|7] ""  FR_CMR
 SG_ FLR_ST35_Quality : 88|2@1+ (1,0) [0|3] ""  FR_CMR
 SG_ FLR_ST35_X_Velocity : 90|13@1- (0.05,0) [-120|120] "m/s"  FR_CMR
 SG_ FLR_ST35_Y_Velocity : 103|13@1- (0.05,0) [-120|120] "m/s"  FR_CMR

BO_ 484 L_FR_RDR_StationaryTrack36_50ms: 64 FR_RDR
 SG_ FLR_ST36_CrcVal : 0|16@1+ (1,0) [0|65535] ""  FR_CMR
 SG_ FLR_ST36_AlvCntVal : 16|8@1+ (1,0) [0|255] ""  FR_CMR
 SG_ FLR_ST36_Elevation : 24|3@1+ (1,0) [0|5] ""  FR_CMR
 SG_ FLR_ST36_ElevationConfidence : 27|2@1+ (1,0) [0|3] ""  FR_CMR
 SG_ FLR_ST36_Lifetime : 29|8@1+ (1,0) [0|255] "Cycles"  FR_CMR
 SG_ FLR_ST36_ObjectId : 37|16@1+ (1,0) [0|65535] ""  FR_CMR
 SG_ FLR_ST36_PositionX : 53|12@1+ (0.05,-3) [-3|200] "m"  FR_CMR
 SG_ FLR_ST36_PositionY : 65|12@1- (0.05,0) [-100|100] "m"  FR_CMR
 SG_ FLR_ST36_PredictionCounter : 77|8@1+ (1,0) [0|255] "Cycles"  FR_CMR
 SG_ FLR_ST36_PropertyBits : 85|3@1+ (1,0) [0|7] ""  FR_CMR
 SG_ FLR_ST36_Quality : 88|2@1+ (1,0) [0|3] ""  FR_CMR
 SG_ FLR_ST36_X_Velocity : 90|13@1- (0.05,0) [-120|120] "m/s"  FR_CMR
 SG_ FLR_ST36_Y_Velocity : 103|13@1- (0.05,0) [-120|120] "m/s"  FR_CMR

BO_ 485 L_FR_RDR_StationaryTrack37_50ms: 64 FR_RDR
 SG_ FLR_ST37_CrcVal : 0|16@1+ (1,0) [0|65535] ""  FR_CMR
 SG_ FLR_ST37_AlvCntVal : 16|8@1+ (1,0) [0|255] ""  FR_CMR
 SG_ FLR_ST37_Elevation : 24|3@1+ (1,0) [0|5] ""  FR_CMR
 SG_ FLR_ST37_ElevationConfidence : 27|2@1+ (1,0) [0|3] ""  FR_CMR
 SG_ FLR_ST37_Lifetime : 29|8@1+ (1,0) [0|255] "Cycles"  FR_CMR
 SG_ FLR_ST37_ObjectId : 37|16@1+ (1,0) [0|65535] ""  FR_CMR
 SG_ FLR_ST37_PositionX : 53|12@1+ (0.05,-3) [-3|200] "m"  FR_CMR
 SG_ FLR_ST37_PositionY : 65|12@1- (0.05,0) [-100|100] "m"  FR_CMR
 SG_ FLR_ST37_PredictionCounter : 77|8@1+ (1,0) [0|255] "Cycles"  FR_CMR
 SG_ FLR_ST37_PropertyBits : 85|3@1+ (1,0) [0|7] ""  FR_CMR
 SG_ FLR_ST37_Quality : 88|2@1+ (1,0) [0|3] ""  FR_CMR
 SG_ FLR_ST37_X_Velocity : 90|13@1- (0.05,0) [-120|120] "m/s"  FR_CMR
 SG_ FLR_ST37_Y_Velocity : 103|13@1- (0.05,0) [-120|120] "m/s"  FR_CMR

BO_ 486 L_FR_RDR_StationaryTrack38_50ms: 64 FR_RDR
 SG_ FLR_ST38_CrcVal : 0|16@1+ (1,0) [0|65535] ""  FR_CMR
 SG_ FLR_ST38_AlvCntVal : 16|8@1+ (1,0) [0|255] ""  FR_CMR
 SG_ FLR_ST38_Elevation : 24|3@1+ (1,0) [0|5] ""  FR_CMR
 SG_ FLR_ST38_ElevationConfidence : 27|2@1+ (1,0) [0|3] ""  FR_CMR
 SG_ FLR_ST38_Lifetime : 29|8@1+ (1,0) [0|255] "Cycles"  FR_CMR
 SG_ FLR_ST38_ObjectId : 37|16@1+ (1,0) [0|65535] ""  FR_CMR
 SG_ FLR_ST38_PositionX : 53|12@1+ (0.05,-3) [-3|200] "m"  FR_CMR
 SG_ FLR_ST38_PositionY : 65|12@1- (0.05,0) [-100|100] "m"  FR_CMR
 SG_ FLR_ST38_PredictionCounter : 77|8@1+ (1,0) [0|255] "Cycles"  FR_CMR
 SG_ FLR_ST38_PropertyBits : 85|3@1+ (1,0) [0|7] ""  FR_CMR
 SG_ FLR_ST38_Quality : 88|2@1+ (1,0) [0|3] ""  FR_CMR
 SG_ FLR_ST38_X_Velocity : 90|13@1- (0.05,0) [-120|120] "m/s"  FR_CMR
 SG_ FLR_ST38_Y_Velocity : 103|13@1- (0.05,0) [-120|120] "m/s"  FR_CMR

BO_ 487 L_FR_RDR_StationaryTrack39_50ms: 64 FR_RDR
 SG_ FLR_ST39_CrcVal : 0|16@1+ (1,0) [0|65535] ""  FR_CMR
 SG_ FLR_ST39_AlvCntVal : 16|8@1+ (1,0) [0|255] ""  FR_CMR
 SG_ FLR_ST39_Elevation : 24|3@1+ (1,0) [0|5] ""  FR_CMR
 SG_ FLR_ST39_ElevationConfidence : 27|2@1+ (1,0) [0|3] ""  FR_CMR
 SG_ FLR_ST39_Lifetime : 29|8@1+ (1,0) [0|255] "Cycles"  FR_CMR
 SG_ FLR_ST39_ObjectId : 37|16@1+ (1,0) [0|65535] ""  FR_CMR
 SG_ FLR_ST39_PositionX : 53|12@1+ (0.05,-3) [-3|200] "m"  FR_CMR
 SG_ FLR_ST39_PositionY : 65|12@1- (0.05,0) [-100|100] "m"  FR_CMR
 SG_ FLR_ST39_PredictionCounter : 77|8@1+ (1,0) [0|255] "Cycles"  FR_CMR
 SG_ FLR_ST39_PropertyBits : 85|3@1+ (1,0) [0|7] ""  FR_CMR
 SG_ FLR_ST39_Quality : 88|2@1+ (1,0) [0|3] ""  FR_CMR
 SG_ FLR_ST39_X_Velocity : 90|13@1- (0.05,0) [-120|120] "m/s"  FR_CMR
 SG_ FLR_ST39_Y_Velocity : 103|13@1- (0.05,0) [-120|120] "m/s"  FR_CMR

BO_ 1752 XCP_Tester_to_FLR: 8 FR_CMR
 SG_ XCP_Tester_to_FLR_Sig : 0|64@1+ (1,0) [0|1.84467440737096E+019] ""  FR_RDR

BO_ 1753 XCP_FLR_to_Tester: 8 FR_RDR
 SG_ XCP_FLR_to_Tester_Sig : 0|64@1+ (1,0) [0|1.84467440737096E+019] ""  FR_CMR

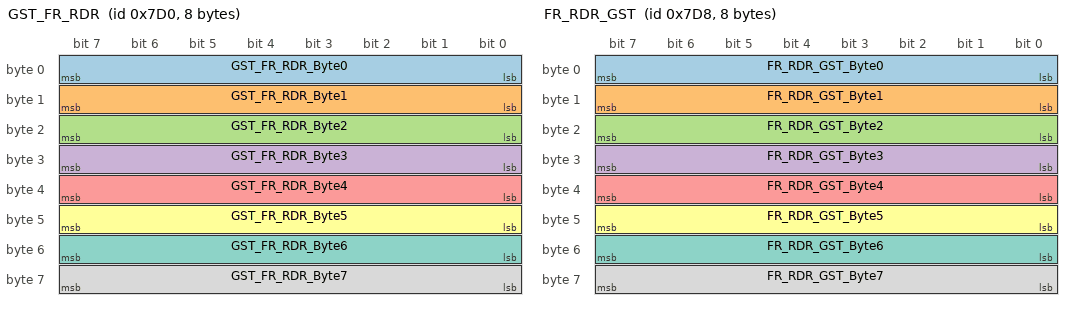
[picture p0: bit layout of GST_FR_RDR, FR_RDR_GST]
BO_ 2000 GST_FR_RDR: 8 FR_CMR
 SG_ GST_FR_RDR_Byte0 : 0|8@1+ (1,0) [0|255] ""  FR_RDR
 SG_ GST_FR_RDR_Byte1 : 8|8@1+ (1,0) [0|255] ""  FR_RDR
 SG_ GST_FR_RDR_Byte2 : 16|8@1+ (1,0) [0|255] ""  FR_RDR
 SG_ GST_FR_RDR_Byte3 : 24|8@1+ (1,0) [0|255] ""  FR_RDR
 SG_ GST_FR_RDR_Byte4 : 32|8@1+ (1,0) [0|255] ""  FR_RDR
 SG_ GST_FR_RDR_Byte5 : 40|8@1+ (1,0) [0|255] ""  FR_RDR
 SG_ GST_FR_RDR_Byte6 : 48|8@1+ (1,0) [0|255] ""  FR_RDR
 SG_ GST_FR_RDR_Byte7 : 56|8@1+ (1,0) [0|255] ""  FR_RDR

BO_ 2008 FR_RDR_GST: 8 FR_RDR
 SG_ FR_RDR_GST_Byte0 : 0|8@1+ (1,0) [0|255] ""  FR_CMR
 SG_ FR_RDR_GST_Byte1 : 8|8@1+ (1,0) [0|255] ""  FR_CMR
 SG_ FR_RDR_GST_Byte2 : 16|8@1+ (1,0) [0|255] ""  FR_CMR
 SG_ FR_RDR_GST_Byte3 : 24|8@1+ (1,0) [0|255] ""  FR_CMR
 SG_ FR_RDR_GST_Byte4 : 32|8@1+ (1,0) [0|255] ""  FR_CMR
 SG_ FR_RDR_GST_Byte5 : 40|8@1+ (1,0) [0|255] ""  FR_CMR
 SG_ FR_RDR_GST_Byte6 : 48|8@1+ (1,0) [0|255] ""  FR_CMR
 SG_ FR_RDR_GST_Byte7 : 56|8@1+ (1,0) [0|255] ""  FR_CMR

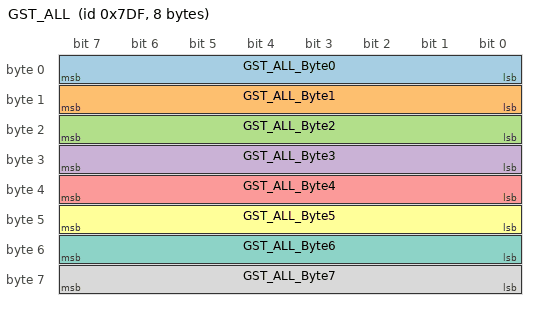
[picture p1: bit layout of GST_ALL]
BO_ 2015 GST_ALL: 8 FR_CMR
 SG_ GST_ALL_Byte0 : 0|8@1+ (1,0) [0|255] ""  FR_RDR
 SG_ GST_ALL_Byte1 : 8|8@1+ (1,0) [0|255] ""  FR_RDR
 SG_ GST_ALL_Byte2 : 16|8@1+ (1,0) [0|255] ""  FR_RDR
 SG_ GST_ALL_Byte3 : 24|8@1+ (1,0) [0|255] ""  FR_RDR
 SG_ GST_ALL_Byte4 : 32|8@1+ (1,0) [0|255] ""  FR_RDR
 SG_ GST_ALL_Byte5 : 40|8@1+ (1,0) [0|255] ""  FR_RDR
 SG_ GST_ALL_Byte6 : 48|8@1+ (1,0) [0|255] ""  FR_RDR
 SG_ GST_ALL_Byte7 : 56|8@1+ (1,0) [0|255] ""  FR_RDR

CM_ BO_ 452 "[P] Periodic";
CM_ SG_ 452 FLR_ST4_CrcVal "CyclicRedundancyCheckValue";
CM_ SG_ 452 FLR_ST4_AlvCntVal "AliveCounter";
CM_ SG_ 452 FLR_ST4_Elevation "Elevation";
CM_ SG_ 452 FLR_ST4_ElevationConfidence "ElevationConfidence";
CM_ SG_ 452 FLR_ST4_Lifetime "Lifetime";
CM_ SG_ 452 FLR_ST4_ObjectId "ObjectId";
CM_ SG_ 452 FLR_ST4_PositionX "PositionX";
CM_ SG_ 452 FLR_ST4_PositionY "PositionY";
CM_ SG_ 452 FLR_ST4_PredictionCounter "PredictionCounter";
CM_ SG_ 452 FLR_ST4_PropertyBits "PropertyBits";
CM_ SG_ 452 FLR_ST4_Quality "Quality";
CM_ SG_ 452 FLR_ST4_X_Velocity "X_Velocity";
CM_ SG_ 452 FLR_ST4_Y_Velocity "Y_Velocity";
CM_ BO_ 453 "[P] Periodic";
CM_ SG_ 453 FLR_ST5_CrcVal "CyclicRedundancyCheckValue";
CM_ SG_ 453 FLR_ST5_AlvCntVal "AliveCounter";
CM_ SG_ 453 FLR_ST5_Elevation "Elevation";
CM_ SG_ 453 FLR_ST5_ElevationConfidence "ElevationConfidence";
CM_ SG_ 453 FLR_ST5_Lifetime "Lifetime";
CM_ SG_ 453 FLR_ST5_ObjectId "ObjectId";
CM_ SG_ 453 FLR_ST5_PositionX "PositionX";
CM_ SG_ 453 FLR_ST5_PositionY "PositionY";
CM_ SG_ 453 FLR_ST5_PredictionCounter "PredictionCounter";
CM_ SG_ 453 FLR_ST5_PropertyBits "PropertyBits";
CM_ SG_ 453 FLR_ST5_Quality "Quality";
CM_ SG_ 453 FLR_ST5_X_Velocity "X_Velocity";
CM_ SG_ 453 FLR_ST5_Y_Velocity "Y_Velocity";
CM_ BO_ 454 "[P] Periodic";
CM_ SG_ 454 FLR_ST6_CrcVal "CyclicRedundancyCheckValue";
CM_ SG_ 454 FLR_ST6_AlvCntVal "AliveCounter";
CM_ SG_ 454 FLR_ST6_Elevation "Elevation";
CM_ SG_ 454 FLR_ST6_ElevationConfidence "ElevationConfidence";
CM_ SG_ 454 FLR_ST6_Lifetime "Lifetime";
CM_ SG_ 454 FLR_ST6_ObjectId "ObjectId";
CM_ SG_ 454 FLR_ST6_PositionX "PositionX";
CM_ SG_ 454 FLR_ST6_PositionY "PositionY";
CM_ SG_ 454 FLR_ST6_PredictionCounter "PredictionCounter";
CM_ SG_ 454 FLR_ST6_PropertyBits "PropertyBits";
CM_ SG_ 454 FLR_ST6_Quality "Quality";
CM_ SG_ 454 FLR_ST6_X_Velocity "X_Velocity";
CM_ SG_ 454 FLR_ST6_Y_Velocity "Y_Velocity";
CM_ BO_ 455 "[P] Periodic";
CM_ SG_ 455 FLR_ST7_CrcVal "CyclicRedundancyCheckValue";
CM_ SG_ 455 FLR_ST7_AlvCntVal "AliveCounter";
CM_ SG_ 455 FLR_ST7_Elevation "Elevation";
CM_ SG_ 455 FLR_ST7_ElevationConfidence "ElevationConfidence";
CM_ SG_ 455 FLR_ST7_Lifetime "Lifetime";
CM_ SG_ 455 FLR_ST7_ObjectId "ObjectId";
CM_ SG_ 455 FLR_ST7_PositionX "PositionX";
CM_ SG_ 455 FLR_ST7_PositionY "PositionY";
CM_ SG_ 455 FLR_ST7_PredictionCounter "PredictionCounter";
CM_ SG_ 455 FLR_ST7_PropertyBits "PropertyBits";
CM_ SG_ 455 FLR_ST7_Quality "Quality";
CM_ SG_ 455 FLR_ST7_X_Velocity "X_Velocity";
CM_ SG_ 455 FLR_ST7_Y_Velocity "Y_Velocity";
CM_ BO_ 456 "[P] Periodic";
CM_ SG_ 456 FLR_ST8_CrcVal "CyclicRedundancyCheckValue";
CM_ SG_ 456 FLR_ST8_AlvCntVal "AliveCounter";
CM_ SG_ 456 FLR_ST8_Elevation "Elevation";
CM_ SG_ 456 FLR_ST8_ElevationConfidence "ElevationConfidence";
CM_ SG_ 456 FLR_ST8_Lifetime "Lifetime";
CM_ SG_ 456 FLR_ST8_ObjectId "ObjectId";
CM_ SG_ 456 FLR_ST8_PositionX "PositionX";
CM_ SG_ 456 FLR_ST8_PositionY "PositionY";
CM_ SG_ 456 FLR_ST8_PredictionCounter "PredictionCounter";
CM_ SG_ 456 FLR_ST8_PropertyBits "PropertyBits";
CM_ SG_ 456 FLR_ST8_Quality "Quality";
CM_ SG_ 456 FLR_ST8_X_Velocity "X_Velocity";
CM_ SG_ 456 FLR_ST8_Y_Velocity "Y_Velocity";
CM_ BO_ 457 "[P] Periodic";
CM_ SG_ 457 FLR_ST9_CrcVal "CyclicRedundancyCheckValue";
CM_ SG_ 457 FLR_ST9_AlvCntVal "AliveCounter";
CM_ SG_ 457 FLR_ST9_Elevation "Elevation";
CM_ SG_ 457 FLR_ST9_ElevationConfidence "ElevationConfidence";
CM_ SG_ 457 FLR_ST9_Lifetime "Lifetime";
CM_ SG_ 457 FLR_ST9_ObjectId "ObjectId";
CM_ SG_ 457 FLR_ST9_PositionX "PositionX";
CM_ SG_ 457 FLR_ST9_PositionY "PositionY";
CM_ SG_ 457 FLR_ST9_PredictionCounter "PredictionCounter";
CM_ SG_ 457 FLR_ST9_PropertyBits "PropertyBits";
CM_ SG_ 457 FLR_ST9_Quality "Quality";
CM_ SG_ 457 FLR_ST9_X_Velocity "X_Velocity";
CM_ SG_ 457 FLR_ST9_Y_Velocity "Y_Velocity";
CM_ BO_ 458 "[P] Periodic";
CM_ SG_ 458 FLR_ST10_CrcVal "CyclicRedundancyCheckValue";
CM_ SG_ 458 FLR_ST10_AlvCntVal "AliveCounter";
CM_ SG_ 458 FLR_ST10_Elevation "Elevation";
CM_ SG_ 458 FLR_ST10_ElevationConfidence "ElevationConfidence";
CM_ SG_ 458 FLR_ST10_Lifetime "Lifetime";
CM_ SG_ 458 FLR_ST10_ObjectId "ObjectId";
CM_ SG_ 458 FLR_ST10_PositionX "PositionX";
CM_ SG_ 458 FLR_ST10_PositionY "PositionY";
CM_ SG_ 458 FLR_ST10_PredictionCounter "PredictionCounter";
CM_ SG_ 458 FLR_ST10_PropertyBits "PropertyBits";
CM_ SG_ 458 FLR_ST10_Quality "Quality";
CM_ SG_ 458 FLR_ST10_X_Velocity "X_Velocity";
CM_ SG_ 458 FLR_ST10_Y_Velocity "Y_Velocity";
CM_ BO_ 459 "[P] Periodic";
CM_ SG_ 459 FLR_ST11_CrcVal "CyclicRedundancyCheckValue";
CM_ SG_ 459 FLR_ST11_AlvCntVal "AliveCounter";
CM_ SG_ 459 FLR_ST11_Elevation "Elevation";
CM_ SG_ 459 FLR_ST11_ElevationConfidence "ElevationConfidence";
CM_ SG_ 459 FLR_ST11_Lifetime "Lifetime";
CM_ SG_ 459 FLR_ST11_ObjectId "ObjectId";
CM_ SG_ 459 FLR_ST11_PositionX "PositionX";
CM_ SG_ 459 FLR_ST11_PositionY "PositionY";
CM_ SG_ 459 FLR_ST11_PredictionCounter "PredictionCounter";
CM_ SG_ 459 FLR_ST11_PropertyBits "PropertyBits";
CM_ SG_ 459 FLR_ST11_Quality "Quality";
CM_ SG_ 459 FLR_ST11_X_Velocity "X_Velocity";
CM_ SG_ 459 FLR_ST11_Y_Velocity "Y_Velocity";
CM_ BO_ 460 "[P] Periodic";
CM_ SG_ 460 FLR_ST12_CrcVal "CyclicRedundancyCheckValue";
CM_ SG_ 460 FLR_ST12_AlvCntVal "AliveCounter";
CM_ SG_ 460 FLR_ST12_Elevation "Elevation";
CM_ SG_ 460 FLR_ST12_ElevationConfidence "ElevationConfidence";
CM_ SG_ 460 FLR_ST12_Lifetime "Lifetime";
CM_ SG_ 460 FLR_ST12_ObjectId "ObjectId";
CM_ SG_ 460 FLR_ST12_PositionX "PositionX";
CM_ SG_ 460 FLR_ST12_PositionY "PositionY";
CM_ SG_ 460 FLR_ST12_PredictionCounter "PredictionCounter";
CM_ SG_ 460 FLR_ST12_PropertyBits "PropertyBits";
CM_ SG_ 460 FLR_ST12_Quality "Quality";
CM_ SG_ 460 FLR_ST12_X_Velocity "X_Velocity";
CM_ SG_ 460 FLR_ST12_Y_Velocity "Y_Velocity";
CM_ BO_ 461 "[P] Periodic";
CM_ SG_ 461 FLR_ST13_CrcVal "CyclicRedundancyCheckValue";
CM_ SG_ 461 FLR_ST13_AlvCntVal "AliveCounter";
CM_ SG_ 461 FLR_ST13_Elevation "Elevation";
CM_ SG_ 461 FLR_ST13_ElevationConfidence "ElevationConfidence";
CM_ SG_ 461 FLR_ST13_Lifetime "Lifetime";
CM_ SG_ 461 FLR_ST13_ObjectId "ObjectId";
CM_ SG_ 461 FLR_ST13_PositionX "PositionX";
CM_ SG_ 461 FLR_ST13_PositionY "PositionY";
CM_ SG_ 461 FLR_ST13_PredictionCounter "PredictionCounter";
CM_ SG_ 461 FLR_ST13_PropertyBits "PropertyBits";
CM_ SG_ 461 FLR_ST13_Quality "Quality";
CM_ SG_ 461 FLR_ST13_X_Velocity "X_Velocity";
CM_ SG_ 461 FLR_ST13_Y_Velocity "Y_Velocity";
CM_ BO_ 462 "[P] Periodic";
CM_ SG_ 462 FLR_ST14_CrcVal "CyclicRedundancyCheckValue";
CM_ SG_ 462 FLR_ST14_AlvCntVal "AliveCounter";
CM_ SG_ 462 FLR_ST14_Elevation "Elevation";
CM_ SG_ 462 FLR_ST14_ElevationConfidence "ElevationConfidence";
CM_ SG_ 462 FLR_ST14_Lifetime "Lifetime";
CM_ SG_ 462 FLR_ST14_ObjectId "ObjectId";
CM_ SG_ 462 FLR_ST14_PositionX "PositionX";
CM_ SG_ 462 FLR_ST14_PositionY "PositionY";
CM_ SG_ 462 FLR_ST14_PredictionCounter "PredictionCounter";
CM_ SG_ 462 FLR_ST14_PropertyBits "PropertyBits";
CM_ SG_ 462 FLR_ST14_Quality "Quality";
CM_ SG_ 462 FLR_ST14_X_Velocity "X_Velocity";
CM_ SG_ 462 FLR_ST14_Y_Velocity "Y_Velocity";
CM_ BO_ 463 "[P] Periodic";
CM_ SG_ 463 FLR_ST15_CrcVal "CyclicRedundancyCheckValue";
CM_ SG_ 463 FLR_ST15_AlvCntVal "AliveCounter";
CM_ SG_ 463 FLR_ST15_Elevation "Elevation";
CM_ SG_ 463 FLR_ST15_ElevationConfidence "ElevationConfidence";
CM_ SG_ 463 FLR_ST15_Lifetime "Lifetime";
CM_ SG_ 463 FLR_ST15_ObjectId "ObjectId";
CM_ SG_ 463 FLR_ST15_PositionX "PositionX";
CM_ SG_ 463 FLR_ST15_PositionY "PositionY";
CM_ SG_ 463 FLR_ST15_PredictionCounter "PredictionCounter";
CM_ SG_ 463 FLR_ST15_PropertyBits "PropertyBits";
CM_ SG_ 463 FLR_ST15_Quality "Quality";
CM_ SG_ 463 FLR_ST15_X_Velocity "X_Velocity";
CM_ SG_ 463 FLR_ST15_Y_Velocity "Y_Velocity";
CM_ BO_ 464 "[P] Periodic";
CM_ SG_ 464 FLR_ST16_CrcVal "CyclicRedundancyCheckValue";
CM_ SG_ 464 FLR_ST16_AlvCntVal "AliveCounter";
CM_ SG_ 464 FLR_ST16_Elevation "Elevation";
CM_ SG_ 464 FLR_ST16_ElevationConfidence "ElevationConfidence";
CM_ SG_ 464 FLR_ST16_Lifetime "Lifetime";
CM_ SG_ 464 FLR_ST16_ObjectId "ObjectId";
CM_ SG_ 464 FLR_ST16_PositionX "PositionX";
CM_ SG_ 464 FLR_ST16_PositionY "PositionY";
CM_ SG_ 464 FLR_ST16_PredictionCounter "PredictionCounter";
CM_ SG_ 464 FLR_ST16_PropertyBits "PropertyBits";
CM_ SG_ 464 FLR_ST16_Quality "Quality";
CM_ SG_ 464 FLR_ST16_X_Velocity "X_Velocity";
CM_ SG_ 464 FLR_ST16_Y_Velocity "Y_Velocity";
CM_ BO_ 465 "[P] Periodic";
CM_ SG_ 465 FLR_ST17_CrcVal "CyclicRedundancyCheckValue";
CM_ SG_ 465 FLR_ST17_AlvCntVal "AliveCounter";
CM_ SG_ 465 FLR_ST17_Elevation "Elevation";
CM_ SG_ 465 FLR_ST17_ElevationConfidence "ElevationConfidence";
CM_ SG_ 465 FLR_ST17_Lifetime "Lifetime";
CM_ SG_ 465 FLR_ST17_ObjectId "ObjectId";
CM_ SG_ 465 FLR_ST17_PositionX "PositionX";
CM_ SG_ 465 FLR_ST17_PositionY "PositionY";
CM_ SG_ 465 FLR_ST17_PredictionCounter "PredictionCounter";
CM_ SG_ 465 FLR_ST17_PropertyBits "PropertyBits";
CM_ SG_ 465 FLR_ST17_Quality "Quality";
CM_ SG_ 465 FLR_ST17_X_Velocity "X_Velocity";
CM_ SG_ 465 FLR_ST17_Y_Velocity "Y_Velocity";
CM_ BO_ 466 "[P] Periodic";
CM_ SG_ 466 FLR_ST18_CrcVal "CyclicRedundancyCheckValue";
CM_ SG_ 466 FLR_ST18_AlvCntVal "AliveCounter";
CM_ SG_ 466 FLR_ST18_Elevation "Elevation";
CM_ SG_ 466 FLR_ST18_ElevationConfidence "ElevationConfidence";
CM_ SG_ 466 FLR_ST18_Lifetime "Lifetime";
CM_ SG_ 466 FLR_ST18_ObjectId "ObjectId";
CM_ SG_ 466 FLR_ST18_PositionX "PositionX";
CM_ SG_ 466 FLR_ST18_PositionY "PositionY";
CM_ SG_ 466 FLR_ST18_PredictionCounter "PredictionCounter";
CM_ SG_ 466 FLR_ST18_PropertyBits "PropertyBits";
CM_ SG_ 466 FLR_ST18_Quality "Quality";
CM_ SG_ 466 FLR_ST18_X_Velocity "X_Velocity";
CM_ SG_ 466 FLR_ST18_Y_Velocity "Y_Velocity";
CM_ BO_ 467 "[P] Periodic";
CM_ SG_ 467 FLR_ST19_CrcVal "CyclicRedundancyCheckValue";
CM_ SG_ 467 FLR_ST19_AlvCntVal "AliveCounter";
CM_ SG_ 467 FLR_ST19_Elevation "Elevation";
CM_ SG_ 467 FLR_ST19_ElevationConfidence "ElevationConfidence";
CM_ SG_ 467 FLR_ST19_Lifetime "Lifetime";
CM_ SG_ 467 FLR_ST19_ObjectId "ObjectId";
CM_ SG_ 467 FLR_ST19_PositionX "PositionX";
CM_ SG_ 467 FLR_ST19_PositionY "PositionY";
CM_ SG_ 467 FLR_ST19_PredictionCounter "PredictionCounter";
CM_ SG_ 467 FLR_ST19_PropertyBits "PropertyBits";
CM_ SG_ 467 FLR_ST19_Quality "Quality";
CM_ SG_ 467 FLR_ST19_X_Velocity "X_Velocity";
CM_ SG_ 467 FLR_ST19_Y_Velocity "Y_Velocity";
CM_ BO_ 468 "[P] Periodic";
CM_ SG_ 468 FLR_ST20_CrcVal "CyclicRedundancyCheckValue";
CM_ SG_ 468 FLR_ST20_AlvCntVal "AliveCounter";
CM_ SG_ 468 FLR_ST20_Elevation "Elevation";
CM_ SG_ 468 FLR_ST20_ElevationConfidence "ElevationConfidence";
CM_ SG_ 468 FLR_ST20_Lifetime "Lifetime";
CM_ SG_ 468 FLR_ST20_ObjectId "ObjectId";
CM_ SG_ 468 FLR_ST20_PositionX "PositionX";
CM_ SG_ 468 FLR_ST20_PositionY "PositionY";
CM_ SG_ 468 FLR_ST20_PredictionCounter "PredictionCounter";
CM_ SG_ 468 FLR_ST20_PropertyBits "PropertyBits";
CM_ SG_ 468 FLR_ST20_Quality "Quality";
CM_ SG_ 468 FLR_ST20_X_Velocity "X_Velocity";
CM_ SG_ 468 FLR_ST20_Y_Velocity "Y_Velocity";
CM_ BO_ 469 "[P] Periodic";
CM_ SG_ 469 FLR_ST21_CrcVal "CyclicRedundancyCheckValue";
CM_ SG_ 469 FLR_ST21_AlvCntVal "AliveCounter";
CM_ SG_ 469 FLR_ST21_Elevation "Elevation";
CM_ SG_ 469 FLR_ST21_ElevationConfidence "ElevationConfidence";
CM_ SG_ 469 FLR_ST21_Lifetime "Lifetime";
CM_ SG_ 469 FLR_ST21_ObjectId "ObjectId";
CM_ SG_ 469 FLR_ST21_PositionX "PositionX";
CM_ SG_ 469 FLR_ST21_PositionY "PositionY";
CM_ SG_ 469 FLR_ST21_PredictionCounter "PredictionCounter";
CM_ SG_ 469 FLR_ST21_PropertyBits "PropertyBits";
CM_ SG_ 469 FLR_ST21_Quality "Quality";
CM_ SG_ 469 FLR_ST21_X_Velocity "X_Velocity";
CM_ SG_ 469 FLR_ST21_Y_Velocity "Y_Velocity";
CM_ BO_ 470 "[P] Periodic";
CM_ SG_ 470 FLR_ST22_CrcVal "CyclicRedundancyCheckValue";
CM_ SG_ 470 FLR_ST22_AlvCntVal "AliveCounter";
CM_ SG_ 470 FLR_ST22_Elevation "Elevation";
CM_ SG_ 470 FLR_ST22_ElevationConfidence "ElevationConfidence";
CM_ SG_ 470 FLR_ST22_Lifetime "Lifetime";
CM_ SG_ 470 FLR_ST22_ObjectId "ObjectId";
CM_ SG_ 470 FLR_ST22_PositionX "PositionX";
CM_ SG_ 470 FLR_ST22_PositionY "PositionY";
CM_ SG_ 470 FLR_ST22_PredictionCounter "PredictionCounter";
CM_ SG_ 470 FLR_ST22_PropertyBits "PropertyBits";
CM_ SG_ 470 FLR_ST22_Quality "Quality";
CM_ SG_ 470 FLR_ST22_X_Velocity "X_Velocity";
CM_ SG_ 470 FLR_ST22_Y_Velocity "Y_Velocity";
CM_ BO_ 471 "[P] Periodic";
CM_ SG_ 471 FLR_ST23_CrcVal "CyclicRedundancyCheckValue";
CM_ SG_ 471 FLR_ST23_AlvCntVal "AliveCounter";
CM_ SG_ 471 FLR_ST23_Elevation "Elevation";
CM_ SG_ 471 FLR_ST23_ElevationConfidence "ElevationConfidence";
CM_ SG_ 471 FLR_ST23_Lifetime "Lifetime";
CM_ SG_ 471 FLR_ST23_ObjectId "ObjectId";
CM_ SG_ 471 FLR_ST23_PositionX "PositionX";
CM_ SG_ 471 FLR_ST23_PositionY "PositionY";
CM_ SG_ 471 FLR_ST23_PredictionCounter "PredictionCounter";
CM_ SG_ 471 FLR_ST23_PropertyBits "PropertyBits";
CM_ SG_ 471 FLR_ST23_Quality "Quality";
CM_ SG_ 471 FLR_ST23_X_Velocity "X_Velocity";
CM_ SG_ 471 FLR_ST23_Y_Velocity "Y_Velocity";
CM_ BO_ 472 "[P] Periodic";
CM_ SG_ 472 FLR_ST24_CrcVal "CyclicRedundancyCheckValue";
CM_ SG_ 472 FLR_ST24_AlvCntVal "AliveCounter";
CM_ SG_ 472 FLR_ST24_Elevation "Elevation";
CM_ SG_ 472 FLR_ST24_ElevationConfidence "ElevationConfidence";
CM_ SG_ 472 FLR_ST24_Lifetime "Lifetime";
CM_ SG_ 472 FLR_ST24_ObjectId "ObjectId";
CM_ SG_ 472 FLR_ST24_PositionX "PositionX";
CM_ SG_ 472 FLR_ST24_PositionY "PositionY";
CM_ SG_ 472 FLR_ST24_PredictionCounter "PredictionCounter";
CM_ SG_ 472 FLR_ST24_PropertyBits "PropertyBits";
CM_ SG_ 472 FLR_ST24_Quality "Quality";
CM_ SG_ 472 FLR_ST24_X_Velocity "X_Velocity";
CM_ SG_ 472 FLR_ST24_Y_Velocity "Y_Velocity";
CM_ BO_ 473 "[P] Periodic";
CM_ SG_ 473 FLR_ST25_CrcVal "CyclicRedundancyCheckValue";
CM_ SG_ 473 FLR_ST25_AlvCntVal "AliveCounter";
CM_ SG_ 473 FLR_ST25_Elevation "Elevation";
CM_ SG_ 473 FLR_ST25_ElevationConfidence "ElevationConfidence";
CM_ SG_ 473 FLR_ST25_Lifetime "Lifetime";
CM_ SG_ 473 FLR_ST25_ObjectId "ObjectId";
CM_ SG_ 473 FLR_ST25_PositionX "PositionX";
CM_ SG_ 473 FLR_ST25_PositionY "PositionY";
CM_ SG_ 473 FLR_ST25_PredictionCounter "PredictionCounter";
CM_ SG_ 473 FLR_ST25_PropertyBits "PropertyBits";
CM_ SG_ 473 FLR_ST25_Quality "Quality";
CM_ SG_ 473 FLR_ST25_X_Velocity "X_Velocity";
CM_ SG_ 473 FLR_ST25_Y_Velocity "Y_Velocity";
CM_ BO_ 474 "[P] Periodic";
CM_ SG_ 474 FLR_ST26_CrcVal "CyclicRedundancyCheckValue";
CM_ SG_ 474 FLR_ST26_AlvCntVal "AliveCounter";
CM_ SG_ 474 FLR_ST26_Elevation "Elevation";
CM_ SG_ 474 FLR_ST26_ElevationConfidence "ElevationConfidence";
CM_ SG_ 474 FLR_ST26_Lifetime "Lifetime";
CM_ SG_ 474 FLR_ST26_ObjectId "ObjectId";
CM_ SG_ 474 FLR_ST26_PositionX "PositionX";
CM_ SG_ 474 FLR_ST26_PositionY "PositionY";
CM_ SG_ 474 FLR_ST26_PredictionCounter "PredictionCounter";
CM_ SG_ 474 FLR_ST26_PropertyBits "PropertyBits";
CM_ SG_ 474 FLR_ST26_Quality "Quality";
CM_ SG_ 474 FLR_ST26_X_Velocity "X_Velocity";
CM_ SG_ 474 FLR_ST26_Y_Velocity "Y_Velocity";
CM_ BO_ 475 "[P] Periodic";
CM_ SG_ 475 FLR_ST27_CrcVal "CyclicRedundancyCheckValue";
CM_ SG_ 475 FLR_ST27_AlvCntVal "AliveCounter";
CM_ SG_ 475 FLR_ST27_Elevation "Elevation";
CM_ SG_ 475 FLR_ST27_ElevationConfidence "ElevationConfidence";
CM_ SG_ 475 FLR_ST27_Lifetime "Lifetime";
CM_ SG_ 475 FLR_ST27_ObjectId "ObjectId";
CM_ SG_ 475 FLR_ST27_PositionX "PositionX";
CM_ SG_ 475 FLR_ST27_PositionY "PositionY";
CM_ SG_ 475 FLR_ST27_PredictionCounter "PredictionCounter";
CM_ SG_ 475 FLR_ST27_PropertyBits "PropertyBits";
CM_ SG_ 475 FLR_ST27_Quality "Quality";
CM_ SG_ 475 FLR_ST27_X_Velocity "X_Velocity";
CM_ SG_ 475 FLR_ST27_Y_Velocity "Y_Velocity";
CM_ BO_ 476 "[P] Periodic";
CM_ SG_ 476 FLR_ST28_CrcVal "CyclicRedundancyCheckValue";
CM_ SG_ 476 FLR_ST28_AlvCntVal "AliveCounter";
CM_ SG_ 476 FLR_ST28_Elevation "Elevation";
CM_ SG_ 476 FLR_ST28_ElevationConfidence "ElevationConfidence";
CM_ SG_ 476 FLR_ST28_Lifetime "Lifetime";
CM_ SG_ 476 FLR_ST28_ObjectId "ObjectId";
CM_ SG_ 476 FLR_ST28_PositionX "PositionX";
CM_ SG_ 476 FLR_ST28_PositionY "PositionY";
CM_ SG_ 476 FLR_ST28_PredictionCounter "PredictionCounter";
CM_ SG_ 476 FLR_ST28_PropertyBits "PropertyBits";
CM_ SG_ 476 FLR_ST28_Quality "Quality";
CM_ SG_ 476 FLR_ST28_X_Velocity "X_Velocity";
CM_ SG_ 476 FLR_ST28_Y_Velocity "Y_Velocity";
CM_ BO_ 477 "[P] Periodic";
CM_ SG_ 477 FLR_ST29_CrcVal "CyclicRedundancyCheckValue";
CM_ SG_ 477 FLR_ST29_AlvCntVal "AliveCounter";
CM_ SG_ 477 FLR_ST29_Elevation "Elevation";
CM_ SG_ 477 FLR_ST29_ElevationConfidence "ElevationConfidence";
CM_ SG_ 477 FLR_ST29_Lifetime "Lifetime";
CM_ SG_ 477 FLR_ST29_ObjectId "ObjectId";
CM_ SG_ 477 FLR_ST29_PositionX "PositionX";
CM_ SG_ 477 FLR_ST29_PositionY "PositionY";
CM_ SG_ 477 FLR_ST29_PredictionCounter "PredictionCounter";
CM_ SG_ 477 FLR_ST29_PropertyBits "PropertyBits";
CM_ SG_ 477 FLR_ST29_Quality "Quality";
CM_ SG_ 477 FLR_ST29_X_Velocity "X_Velocity";
CM_ SG_ 477 FLR_ST29_Y_Velocity "Y_Velocity";
CM_ BO_ 478 "[P] Periodic";
CM_ SG_ 478 FLR_ST30_CrcVal "CyclicRedundancyCheckValue";
CM_ SG_ 478 FLR_ST30_AlvCntVal "AliveCounter";
CM_ SG_ 478 FLR_ST30_Elevation "Elevation";
CM_ SG_ 478 FLR_ST30_ElevationConfidence "ElevationConfidence";
CM_ SG_ 478 FLR_ST30_Lifetime "Lifetime";
CM_ SG_ 478 FLR_ST30_ObjectId "ObjectId";
CM_ SG_ 478 FLR_ST30_PositionX "PositionX";
CM_ SG_ 478 FLR_ST30_PositionY "PositionY";
CM_ SG_ 478 FLR_ST30_PredictionCounter "PredictionCounter";
CM_ SG_ 478 FLR_ST30_PropertyBits "PropertyBits";
CM_ SG_ 478 FLR_ST30_Quality "Quality";
CM_ SG_ 478 FLR_ST30_X_Velocity "X_Velocity";
CM_ SG_ 478 FLR_ST30_Y_Velocity "Y_Velocity";
CM_ BO_ 479 "[P] Periodic";
CM_ SG_ 479 FLR_ST31_CrcVal "CyclicRedundancyCheckValue";
CM_ SG_ 479 FLR_ST31_AlvCntVal "AliveCounter";
CM_ SG_ 479 FLR_ST31_Elevation "Elevation";
CM_ SG_ 479 FLR_ST31_ElevationConfidence "ElevationConfidence";
CM_ SG_ 479 FLR_ST31_Lifetime "Lifetime";
CM_ SG_ 479 FLR_ST31_ObjectId "ObjectId";
CM_ SG_ 479 FLR_ST31_PositionX "PositionX";
CM_ SG_ 479 FLR_ST31_PositionY "PositionY";
CM_ SG_ 479 FLR_ST31_PredictionCounter "PredictionCounter";
CM_ SG_ 479 FLR_ST31_PropertyBits "PropertyBits";
CM_ SG_ 479 FLR_ST31_Quality "Quality";
CM_ SG_ 479 FLR_ST31_X_Velocity "X_Velocity";
CM_ SG_ 479 FLR_ST31_Y_Velocity "Y_Velocity";
CM_ BO_ 480 "[P] Periodic";
CM_ SG_ 480 FLR_ST32_CrcVal "CyclicRedundancyCheckValue";
CM_ SG_ 480 FLR_ST32_AlvCntVal "AliveCounter";
CM_ SG_ 480 FLR_ST32_Elevation "Elevation";
CM_ SG_ 480 FLR_ST32_ElevationConfidence "ElevationConfidence";
CM_ SG_ 480 FLR_ST32_Lifetime "Lifetime";
CM_ SG_ 480 FLR_ST32_ObjectId "ObjectId";
CM_ SG_ 480 FLR_ST32_PositionX "PositionX";
CM_ SG_ 480 FLR_ST32_PositionY "PositionY";
CM_ SG_ 480 FLR_ST32_PredictionCounter "PredictionCounter";
CM_ SG_ 480 FLR_ST32_PropertyBits "PropertyBits";
CM_ SG_ 480 FLR_ST32_Quality "Quality";
CM_ SG_ 480 FLR_ST32_X_Velocity "X_Velocity";
CM_ SG_ 480 FLR_ST32_Y_Velocity "Y_Velocity";
CM_ BO_ 481 "[P] Periodic";
CM_ SG_ 481 FLR_ST33_CrcVal "CyclicRedundancyCheckValue";
CM_ SG_ 481 FLR_ST33_AlvCntVal "AliveCounter";
CM_ SG_ 481 FLR_ST33_Elevation "Elevation";
CM_ SG_ 481 FLR_ST33_ElevationConfidence "ElevationConfidence";
CM_ SG_ 481 FLR_ST33_Lifetime "Lifetime";
CM_ SG_ 481 FLR_ST33_ObjectId "ObjectId";
CM_ SG_ 481 FLR_ST33_PositionX "PositionX";
CM_ SG_ 481 FLR_ST33_PositionY "PositionY";
CM_ SG_ 481 FLR_ST33_PredictionCounter "PredictionCounter";
CM_ SG_ 481 FLR_ST33_PropertyBits "PropertyBits";
CM_ SG_ 481 FLR_ST33_Quality "Quality";
CM_ SG_ 481 FLR_ST33_X_Velocity "X_Velocity";
CM_ SG_ 481 FLR_ST33_Y_Velocity "Y_Velocity";
CM_ BO_ 482 "[P] Periodic";
CM_ SG_ 482 FLR_ST34_CrcVal "CyclicRedundancyCheckValue";
CM_ SG_ 482 FLR_ST34_AlvCntVal "AliveCounter";
CM_ SG_ 482 FLR_ST34_Elevation "Elevation";
CM_ SG_ 482 FLR_ST34_ElevationConfidence "ElevationConfidence";
CM_ SG_ 482 FLR_ST34_Lifetime "Lifetime";
CM_ SG_ 482 FLR_ST34_ObjectId "ObjectId";
CM_ SG_ 482 FLR_ST34_PositionX "PositionX";
CM_ SG_ 482 FLR_ST34_PositionY "PositionY";
CM_ SG_ 482 FLR_ST34_PredictionCounter "PredictionCounter";
CM_ SG_ 482 FLR_ST34_PropertyBits "PropertyBits";
CM_ SG_ 482 FLR_ST34_Quality "Quality";
CM_ SG_ 482 FLR_ST34_X_Velocity "X_Velocity";
CM_ SG_ 482 FLR_ST34_Y_Velocity "Y_Velocity";
CM_ BO_ 483 "[P] Periodic";
CM_ SG_ 483 FLR_ST35_CrcVal "CyclicRedundancyCheckValue";
CM_ SG_ 483 FLR_ST35_AlvCntVal "AliveCounter";
CM_ SG_ 483 FLR_ST35_Elevation "Elevation";
CM_ SG_ 483 FLR_ST35_ElevationConfidence "ElevationConfidence";
CM_ SG_ 483 FLR_ST35_Lifetime "Lifetime";
CM_ SG_ 483 FLR_ST35_ObjectId "ObjectId";
CM_ SG_ 483 FLR_ST35_PositionX "PositionX";
CM_ SG_ 483 FLR_ST35_PositionY "PositionY";
CM_ SG_ 483 FLR_ST35_PredictionCounter "PredictionCounter";
CM_ SG_ 483 FLR_ST35_PropertyBits "PropertyBits";
CM_ SG_ 483 FLR_ST35_Quality "Quality";
CM_ SG_ 483 FLR_ST35_X_Velocity "X_Velocity";
CM_ SG_ 483 FLR_ST35_Y_Velocity "Y_Velocity";
CM_ BO_ 484 "[P] Periodic";
CM_ SG_ 484 FLR_ST36_CrcVal "CyclicRedundancyCheckValue";
CM_ SG_ 484 FLR_ST36_AlvCntVal "AliveCounter";
CM_ SG_ 484 FLR_ST36_Elevation "Elevation";
CM_ SG_ 484 FLR_ST36_ElevationConfidence "ElevationConfidence";
CM_ SG_ 484 FLR_ST36_Lifetime "Lifetime";
CM_ SG_ 484 FLR_ST36_ObjectId "ObjectId";
CM_ SG_ 484 FLR_ST36_PositionX "PositionX";
CM_ SG_ 484 FLR_ST36_PositionY "PositionY";
CM_ SG_ 484 FLR_ST36_PredictionCounter "PredictionCounter";
CM_ SG_ 484 FLR_ST36_PropertyBits "PropertyBits";
CM_ SG_ 484 FLR_ST36_Quality "Quality";
CM_ SG_ 484 FLR_ST36_X_Velocity "X_Velocity";
CM_ SG_ 484 FLR_ST36_Y_Velocity "Y_Velocity";
CM_ BO_ 485 "[P] Periodic";
CM_ SG_ 485 FLR_ST37_CrcVal "CyclicRedundancyCheckValue";
CM_ SG_ 485 FLR_ST37_AlvCntVal "AliveCounter";
CM_ SG_ 485 FLR_ST37_Elevation "Elevation";
CM_ SG_ 485 FLR_ST37_ElevationConfidence "ElevationConfidence";
CM_ SG_ 485 FLR_ST37_Lifetime "Lifetime";
CM_ SG_ 485 FLR_ST37_ObjectId "ObjectId";
CM_ SG_ 485 FLR_ST37_PositionX "PositionX";
CM_ SG_ 485 FLR_ST37_PositionY "PositionY";
CM_ SG_ 485 FLR_ST37_PredictionCounter "PredictionCounter";
CM_ SG_ 485 FLR_ST37_PropertyBits "PropertyBits";
CM_ SG_ 485 FLR_ST37_Quality "Quality";
CM_ SG_ 485 FLR_ST37_X_Velocity "X_Velocity";
CM_ SG_ 485 FLR_ST37_Y_Velocity "Y_Velocity";
CM_ BO_ 486 "[P] Periodic";
CM_ SG_ 486 FLR_ST38_CrcVal "CyclicRedundancyCheckValue";
CM_ SG_ 486 FLR_ST38_AlvCntVal "AliveCounter";
CM_ SG_ 486 FLR_ST38_Elevation "Elevation";
CM_ SG_ 486 FLR_ST38_ElevationConfidence "ElevationConfidence";
CM_ SG_ 486 FLR_ST38_Lifetime "Lifetime";
CM_ SG_ 486 FLR_ST38_ObjectId "ObjectId";
CM_ SG_ 486 FLR_ST38_PositionX "PositionX";
CM_ SG_ 486 FLR_ST38_PositionY "PositionY";
CM_ SG_ 486 FLR_ST38_PredictionCounter "PredictionCounter";
CM_ SG_ 486 FLR_ST38_PropertyBits "PropertyBits";
CM_ SG_ 486 FLR_ST38_Quality "Quality";
CM_ SG_ 486 FLR_ST38_X_Velocity "X_Velocity";
CM_ SG_ 486 FLR_ST38_Y_Velocity "Y_Velocity";
CM_ BO_ 487 "[P] Periodic";
CM_ SG_ 487 FLR_ST39_CrcVal "CyclicRedundancyCheckValue";
CM_ SG_ 487 FLR_ST39_AlvCntVal "AliveCounter";
CM_ SG_ 487 FLR_ST39_Elevation "Elevation";
CM_ SG_ 487 FLR_ST39_ElevationConfidence "ElevationConfidence";
CM_ SG_ 487 FLR_ST39_Lifetime "Lifetime";
CM_ SG_ 487 FLR_ST39_ObjectId "ObjectId";
CM_ SG_ 487 FLR_ST39_PositionX "PositionX";
CM_ SG_ 487 FLR_ST39_PositionY "PositionY";
CM_ SG_ 487 FLR_ST39_PredictionCounter "PredictionCounter";
CM_ SG_ 487 FLR_ST39_PropertyBits "PropertyBits";
CM_ SG_ 487 FLR_ST39_Quality "Quality";
CM_ SG_ 487 FLR_ST39_X_Velocity "X_Velocity";
CM_ SG_ 487 FLR_ST39_Y_Velocity "Y_Velocity";
CM_ BO_ 1752 "[EW] On Event and On Write";
CM_ BO_ 1753 "[EW] On Event and On Write";
CM_ BO_ 2000 "[EW] On Event and On Write";
CM_ BO_ 2008 "[EW] On Event and On Write";
CM_ BO_ 2015 "[EW] On Event and On Write";
BA_DEF_ BO_  "GenMsgILSupport" ENUM  "No","Yes","vector_leerstring";
BA_DEF_ BO_  "DiagState" ENUM  "No","Yes","vector_leerstring";
BA_DEF_ BO_  "DiagRequest" ENUM  "No","Yes","vector_leerstring";
BA_DEF_ BO_  "VFrameFormat" ENUM  "StandardCAN","ExtendedCAN","reserved","reserved","reserved","reserved","reserved","reserved","reserved","reserved","reserved","reserved","reserved","reserved","StandardCAN_FD","ExtendedCAN_FD";
BA_DEF_ BO_  "GenMsgSendType" ENUM  "Cyclic","NoMsgSendType";
BA_DEF_ SG_  "UserSigValidity" ENUM  "B+","ACC","IG","IG1","IG2","IG3","IG1 or IG2","IG1 or IG3","Undef";
BA_DEF_ SG_  "RoutingFactor" INT 1 1215752192;
BA_DEF_ SG_  "Description" STRING ;
BA_DEF_ SG_  "Version" STRING ;
BA_DEF_ BO_  "GenMsgCycleTime" INT 0 2000;
BA_DEF_ BO_  "GenMsgStartDelayTime" INT 0 2000;
BA_DEF_ SG_  "UsrSigPurpose" ENUM  "Undef","FN","DIAG","DEV","NM";
BA_DEF_ SG_  "GenSigStartValue" INT 0 0;
BA_DEF_DEF_  "GenMsgILSupport" "Yes";
BA_DEF_DEF_  "DiagState" "No";
BA_DEF_DEF_  "DiagRequest" "No";
BA_DEF_DEF_  "VFrameFormat" "";
BA_DEF_DEF_  "GenMsgSendType" "NoMsgSendType";
BA_DEF_DEF_  "UserSigValidity" "IG";
BA_DEF_DEF_  "RoutingFactor" 1;
BA_DEF_DEF_  "Description" "";
BA_DEF_DEF_  "Version" "";
BA_DEF_DEF_  "GenMsgCycleTime" 0;
BA_DEF_DEF_  "GenMsgStartDelayTime" 0;
BA_DEF_DEF_  "UsrSigPurpose" "FN";
BA_DEF_DEF_  "GenSigStartValue" 0;
BA_ "GenMsgSendType" BO_ 452 0;
BA_ "GenMsgCycleTime" BO_ 452 50;
BA_ "VFrameFormat" BO_ 452 14;
BA_ "GenMsgSendType" BO_ 453 0;
BA_ "GenMsgCycleTime" BO_ 453 50;
BA_ "VFrameFormat" BO_ 453 14;
BA_ "GenMsgSendType" BO_ 454 0;
BA_ "GenMsgCycleTime" BO_ 454 50;
BA_ "VFrameFormat" BO_ 454 14;
BA_ "GenMsgSendType" BO_ 455 0;
BA_ "GenMsgCycleTime" BO_ 455 50;
BA_ "VFrameFormat" BO_ 455 14;
BA_ "GenMsgSendType" BO_ 456 0;
BA_ "GenMsgCycleTime" BO_ 456 50;
BA_ "VFrameFormat" BO_ 456 14;
BA_ "GenMsgSendType" BO_ 457 0;
BA_ "GenMsgCycleTime" BO_ 457 50;
BA_ "VFrameFormat" BO_ 457 14;
BA_ "GenMsgSendType" BO_ 458 0;
BA_ "GenMsgCycleTime" BO_ 458 50;
BA_ "VFrameFormat" BO_ 458 14;
BA_ "GenMsgSendType" BO_ 459 0;
BA_ "GenMsgCycleTime" BO_ 459 50;
BA_ "VFrameFormat" BO_ 459 14;
BA_ "GenMsgSendType" BO_ 460 0;
BA_ "GenMsgCycleTime" BO_ 460 50;
BA_ "VFrameFormat" BO_ 460 14;
BA_ "GenMsgSendType" BO_ 461 0;
BA_ "GenMsgCycleTime" BO_ 461 50;
BA_ "VFrameFormat" BO_ 461 14;
BA_ "GenMsgSendType" BO_ 462 0;
BA_ "GenMsgCycleTime" BO_ 462 50;
BA_ "VFrameFormat" BO_ 462 14;
BA_ "GenMsgSendType" BO_ 463 0;
BA_ "GenMsgCycleTime" BO_ 463 50;
BA_ "VFrameFormat" BO_ 463 14;
BA_ "GenMsgSendType" BO_ 464 0;
BA_ "GenMsgCycleTime" BO_ 464 50;
BA_ "VFrameFormat" BO_ 464 14;
BA_ "GenMsgSendType" BO_ 465 0;
BA_ "GenMsgCycleTime" BO_ 465 50;
BA_ "VFrameFormat" BO_ 465 14;
BA_ "GenMsgSendType" BO_ 466 0;
BA_ "GenMsgCycleTime" BO_ 466 50;
BA_ "VFrameFormat" BO_ 466 14;
BA_ "GenMsgSendType" BO_ 467 0;
BA_ "GenMsgCycleTime" BO_ 467 50;
BA_ "VFrameFormat" BO_ 467 14;
BA_ "GenMsgSendType" BO_ 468 0;
BA_ "GenMsgCycleTime" BO_ 468 50;
BA_ "VFrameFormat" BO_ 468 14;
BA_ "GenMsgSendType" BO_ 469 0;
BA_ "GenMsgCycleTime" BO_ 469 50;
BA_ "VFrameFormat" BO_ 469 14;
BA_ "GenMsgSendType" BO_ 470 0;
BA_ "GenMsgCycleTime" BO_ 470 50;
BA_ "VFrameFormat" BO_ 470 14;
BA_ "GenMsgSendType" BO_ 471 0;
BA_ "GenMsgCycleTime" BO_ 471 50;
BA_ "VFrameFormat" BO_ 471 14;
BA_ "GenMsgSendType" BO_ 472 0;
BA_ "GenMsgCycleTime" BO_ 472 50;
BA_ "VFrameFormat" BO_ 472 14;
BA_ "GenMsgSendType" BO_ 473 0;
BA_ "GenMsgCycleTime" BO_ 473 50;
BA_ "VFrameFormat" BO_ 473 14;
BA_ "GenMsgSendType" BO_ 474 0;
BA_ "GenMsgCycleTime" BO_ 474 50;
BA_ "VFrameFormat" BO_ 474 14;
BA_ "GenMsgSendType" BO_ 475 0;
BA_ "GenMsgCycleTime" BO_ 475 50;
BA_ "VFrameFormat" BO_ 475 14;
BA_ "GenMsgSendType" BO_ 476 0;
BA_ "GenMsgCycleTime" BO_ 476 50;
BA_ "VFrameFormat" BO_ 476 14;
BA_ "GenMsgSendType" BO_ 477 0;
BA_ "GenMsgCycleTime" BO_ 477 50;
BA_ "VFrameFormat" BO_ 477 14;
BA_ "GenMsgSendType" BO_ 478 0;
BA_ "GenMsgCycleTime" BO_ 478 50;
BA_ "VFrameFormat" BO_ 478 14;
BA_ "GenMsgSendType" BO_ 479 0;
BA_ "GenMsgCycleTime" BO_ 479 50;
BA_ "VFrameFormat" BO_ 479 14;
BA_ "GenMsgSendType" BO_ 480 0;
BA_ "GenMsgCycleTime" BO_ 480 50;
BA_ "VFrameFormat" BO_ 480 14;
BA_ "GenMsgSendType" BO_ 481 0;
BA_ "GenMsgCycleTime" BO_ 481 50;
BA_ "VFrameFormat" BO_ 481 14;
BA_ "GenMsgSendType" BO_ 482 0;
BA_ "GenMsgCycleTime" BO_ 482 50;
BA_ "VFrameFormat" BO_ 482 14;
BA_ "GenMsgSendType" BO_ 483 0;
BA_ "GenMsgCycleTime" BO_ 483 50;
BA_ "VFrameFormat" BO_ 483 14;
BA_ "GenMsgSendType" BO_ 484 0;
BA_ "GenMsgCycleTime" BO_ 484 50;
BA_ "VFrameFormat" BO_ 484 14;
BA_ "GenMsgSendType" BO_ 485 0;
BA_ "GenMsgCycleTime" BO_ 485 50;
BA_ "VFrameFormat" BO_ 485 14;
BA_ "GenMsgSendType" BO_ 486 0;
BA_ "GenMsgCycleTime" BO_ 486 50;
BA_ "VFrameFormat" BO_ 486 14;
BA_ "GenMsgSendType" BO_ 487 0;
BA_ "GenMsgCycleTime" BO_ 487 50;
BA_ "VFrameFormat" BO_ 487 14;
BA_ "VFrameFormat" BO_ 1752 14;
BA_ "VFrameFormat" BO_ 1753 14;
BA_ "GenMsgILSupport" BO_ 2000 0;
BA_ "VFrameFormat" BO_ 2000 14;
BA_ "GenMsgILSupport" BO_ 2008 0;
BA_ "VFrameFormat" BO_ 2008 14;
BA_ "GenMsgILSupport" BO_ 2015 0;
BA_ "DiagState" BO_ 2015 1;
BA_ "DiagRequest" BO_ 2015 1;
BA_ "VFrameFormat" BO_ 2015 14;
BA_ "Description" SG_ 452 FLR_ST4_CrcVal "The CRC checking process calculates the CRC over the entire data block, including the CRC result.

- CRC Polynomial (0x1021) , Initial Value : 0xFFFF, XOR value : 0x0000

- The mathematical expression to 16 bit CRC polynomial is given here. G(x) = x16 + ";
BA_ "GenSigStartValue" SG_ 452 FLR_ST4_CrcVal 65535;
BA_ "UserSigValidity" SG_ 452 FLR_ST4_CrcVal 3;
BA_ "Description" SG_ 452 FLR_ST4_AlvCntVal "[Alive counter] For the first transmission request for a data element the counter shall be initialized with 0 and shall be incremented by 1

for every subsequent send request. When the counter reaches the maximum value(0xFF), then it shall restart with â";
BA_ "UserSigValidity" SG_ 452 FLR_ST4_AlvCntVal 3;
BA_ "Description" SG_ 452 FLR_ST4_Elevation "Elevation Classification from Core Elevation Library";
BA_ "UserSigValidity" SG_ 452 FLR_ST4_Elevation 3;
BA_ "Description" SG_ 452 FLR_ST4_ElevationConfidence "	Elevation Classification Confidence Level from Core Elevation Library";
BA_ "UserSigValidity" SG_ 452 FLR_ST4_ElevationConfidence 3;
BA_ "Description" SG_ 452 FLR_ST4_Lifetime "Number of cycles the target has been alive. Unknown 0";
BA_ "UserSigValidity" SG_ 452 FLR_ST4_Lifetime 3;
BA_ "Description" SG_ 452 FLR_ST4_ObjectId "A global ID, which is constant as long as the object is tracked. Note! A value of 0 indicates 'no object'";
BA_ "UserSigValidity" SG_ 452 FLR_ST4_ObjectId 3;
BA_ "Description" SG_ 452 FLR_ST4_PositionX "Filtered X position";
BA_ "UserSigValidity" SG_ 452 FLR_ST4_PositionX 3;
BA_ "Description" SG_ 452 FLR_ST4_PositionY "Filtered Y position";
BA_ "UserSigValidity" SG_ 452 FLR_ST4_PositionY 3;
BA_ "Description" SG_ 452 FLR_ST4_PredictionCounter "Number of cycles the target has been predicted";
BA_ "UserSigValidity" SG_ 452 FLR_ST4_PredictionCounter 3;
BA_ "Description" SG_ 452 FLR_ST4_PropertyBits "Bitmask for property values described by StationaryTrackPropertyBits";
BA_ "UserSigValidity" SG_ 452 FLR_ST4_PropertyBits 3;
BA_ "Description" SG_ 452 FLR_ST4_Quality "Track quality";
BA_ "UserSigValidity" SG_ 452 FLR_ST4_Quality 3;
BA_ "Description" SG_ 452 FLR_ST4_X_Velocity "Filtered absolute longitudinal velocity";
BA_ "UserSigValidity" SG_ 452 FLR_ST4_X_Velocity 3;
BA_ "Description" SG_ 452 FLR_ST4_Y_Velocity "Filtered absolute lateral velocity";
BA_ "UserSigValidity" SG_ 452 FLR_ST4_Y_Velocity 3;
BA_ "Description" SG_ 453 FLR_ST5_CrcVal "The CRC checking process calculates the CRC over the entire data block, including the CRC result.

- CRC Polynomial (0x1021) , Initial Value : 0xFFFF, XOR value : 0x0000

- The mathematical expression to 16 bit CRC polynomial is given here. G(x) = x16 + ";
BA_ "GenSigStartValue" SG_ 453 FLR_ST5_CrcVal 65535;
BA_ "UserSigValidity" SG_ 453 FLR_ST5_CrcVal 3;
BA_ "Description" SG_ 453 FLR_ST5_AlvCntVal "[Alive counter] For the first transmission request for a data element the counter shall be initialized with 0 and shall be incremented by 1

for every subsequent send request. When the counter reaches the maximum value(0xFF), then it shall restart with â";
BA_ "UserSigValidity" SG_ 453 FLR_ST5_AlvCntVal 3;
BA_ "Description" SG_ 453 FLR_ST5_Elevation "Elevation Classification from Core Elevation Library";
BA_ "UserSigValidity" SG_ 453 FLR_ST5_Elevation 3;
BA_ "Description" SG_ 453 FLR_ST5_ElevationConfidence "	Elevation Classification Confidence Level from Core Elevation Library";
BA_ "UserSigValidity" SG_ 453 FLR_ST5_ElevationConfidence 3;
BA_ "Description" SG_ 453 FLR_ST5_Lifetime "Number of cycles the target has been alive. Unknown 0";
BA_ "UserSigValidity" SG_ 453 FLR_ST5_Lifetime 3;
BA_ "Description" SG_ 453 FLR_ST5_ObjectId "A global ID, which is constant as long as the object is tracked. Note! A value of 0 indicates 'no object'";
BA_ "UserSigValidity" SG_ 453 FLR_ST5_ObjectId 3;
BA_ "Description" SG_ 453 FLR_ST5_PositionX "Filtered X position";
BA_ "UserSigValidity" SG_ 453 FLR_ST5_PositionX 3;
BA_ "Description" SG_ 453 FLR_ST5_PositionY "Filtered Y position";
BA_ "UserSigValidity" SG_ 453 FLR_ST5_PositionY 3;
BA_ "Description" SG_ 453 FLR_ST5_PredictionCounter "Number of cycles the target has been predicted";
BA_ "UserSigValidity" SG_ 453 FLR_ST5_PredictionCounter 3;
BA_ "Description" SG_ 453 FLR_ST5_PropertyBits "Bitmask for property values described by StationaryTrackPropertyBits";
BA_ "UserSigValidity" SG_ 453 FLR_ST5_PropertyBits 3;
BA_ "Description" SG_ 453 FLR_ST5_Quality "Track quality";
BA_ "UserSigValidity" SG_ 453 FLR_ST5_Quality 3;
BA_ "Description" SG_ 453 FLR_ST5_X_Velocity "Filtered absolute longitudinal velocity";
BA_ "UserSigValidity" SG_ 453 FLR_ST5_X_Velocity 3;
BA_ "Description" SG_ 453 FLR_ST5_Y_Velocity "Filtered absolute lateral velocity";
BA_ "UserSigValidity" SG_ 453 FLR_ST5_Y_Velocity 3;
BA_ "Description" SG_ 454 FLR_ST6_CrcVal "The CRC checking process calculates the CRC over the entire data block, including the CRC result.

- CRC Polynomial (0x1021) , Initial Value : 0xFFFF, XOR value : 0x0000

- The mathematical expression to 16 bit CRC polynomial is given here. G(x) = x16 + ";
BA_ "GenSigStartValue" SG_ 454 FLR_ST6_CrcVal 65535;
BA_ "UserSigValidity" SG_ 454 FLR_ST6_CrcVal 3;
BA_ "Description" SG_ 454 FLR_ST6_AlvCntVal "[Alive counter] For the first transmission request for a data element the counter shall be initialized with 0 and shall be incremented by 1

for every subsequent send request. When the counter reaches the maximum value(0xFF), then it shall restart with â";
BA_ "UserSigValidity" SG_ 454 FLR_ST6_AlvCntVal 3;
BA_ "Description" SG_ 454 FLR_ST6_Elevation "Elevation Classification from Core Elevation Library";
BA_ "UserSigValidity" SG_ 454 FLR_ST6_Elevation 3;
BA_ "Description" SG_ 454 FLR_ST6_ElevationConfidence "	Elevation Classification Confidence Level from Core Elevation Library";
BA_ "UserSigValidity" SG_ 454 FLR_ST6_ElevationConfidence 3;
BA_ "Description" SG_ 454 FLR_ST6_Lifetime "Number of cycles the target has been alive. Unknown 0";
BA_ "UserSigValidity" SG_ 454 FLR_ST6_Lifetime 3;
BA_ "Description" SG_ 454 FLR_ST6_ObjectId "A global ID, which is constant as long as the object is tracked. Note! A value of 0 indicates 'no object'";
BA_ "UserSigValidity" SG_ 454 FLR_ST6_ObjectId 3;
BA_ "Description" SG_ 454 FLR_ST6_PositionX "Filtered X position";
BA_ "UserSigValidity" SG_ 454 FLR_ST6_PositionX 3;
BA_ "Description" SG_ 454 FLR_ST6_PositionY "Filtered Y position";
BA_ "UserSigValidity" SG_ 454 FLR_ST6_PositionY 3;
BA_ "Description" SG_ 454 FLR_ST6_PredictionCounter "Number of cycles the target has been predicted";
BA_ "UserSigValidity" SG_ 454 FLR_ST6_PredictionCounter 3;
BA_ "Description" SG_ 454 FLR_ST6_PropertyBits "Bitmask for property values described by StationaryTrackPropertyBits";
BA_ "UserSigValidity" SG_ 454 FLR_ST6_PropertyBits 3;
BA_ "Description" SG_ 454 FLR_ST6_Quality "Track quality";
BA_ "UserSigValidity" SG_ 454 FLR_ST6_Quality 3;
BA_ "Description" SG_ 454 FLR_ST6_X_Velocity "Filtered absolute longitudinal velocity";
BA_ "UserSigValidity" SG_ 454 FLR_ST6_X_Velocity 3;
BA_ "Description" SG_ 454 FLR_ST6_Y_Velocity "Filtered absolute lateral velocity";
BA_ "UserSigValidity" SG_ 454 FLR_ST6_Y_Velocity 3;
BA_ "Description" SG_ 455 FLR_ST7_CrcVal "The CRC checking process calculates the CRC over the entire data block, including the CRC result.

- CRC Polynomial (0x1021) , Initial Value : 0xFFFF, XOR value : 0x0000

- The mathematical expression to 16 bit CRC polynomial is given here. G(x) = x16 + ";
BA_ "GenSigStartValue" SG_ 455 FLR_ST7_CrcVal 65535;
BA_ "UserSigValidity" SG_ 455 FLR_ST7_CrcVal 3;
BA_ "Description" SG_ 455 FLR_ST7_AlvCntVal "[Alive counter] For the first transmission request for a data element the counter shall be initialized with 0 and shall be incremented by 1

for every subsequent send request. When the counter reaches the maximum value(0xFF), then it shall restart with â";
BA_ "UserSigValidity" SG_ 455 FLR_ST7_AlvCntVal 3;
BA_ "Description" SG_ 455 FLR_ST7_Elevation "Elevation Classification from Core Elevation Library";
BA_ "UserSigValidity" SG_ 455 FLR_ST7_Elevation 3;
BA_ "Description" SG_ 455 FLR_ST7_ElevationConfidence "	Elevation Classification Confidence Level from Core Elevation Library";
BA_ "UserSigValidity" SG_ 455 FLR_ST7_ElevationConfidence 3;
BA_ "Description" SG_ 455 FLR_ST7_Lifetime "Number of cycles the target has been alive. Unknown 0";
BA_ "UserSigValidity" SG_ 455 FLR_ST7_Lifetime 3;
BA_ "Description" SG_ 455 FLR_ST7_ObjectId "A global ID, which is constant as long as the object is tracked. Note! A value of 0 indicates 'no object'";
BA_ "UserSigValidity" SG_ 455 FLR_ST7_ObjectId 3;
BA_ "Description" SG_ 455 FLR_ST7_PositionX "Filtered X position";
BA_ "UserSigValidity" SG_ 455 FLR_ST7_PositionX 3;
BA_ "Description" SG_ 455 FLR_ST7_PositionY "Filtered Y position";
BA_ "UserSigValidity" SG_ 455 FLR_ST7_PositionY 3;
BA_ "Description" SG_ 455 FLR_ST7_PredictionCounter "Number of cycles the target has been predicted";
BA_ "UserSigValidity" SG_ 455 FLR_ST7_PredictionCounter 3;
BA_ "Description" SG_ 455 FLR_ST7_PropertyBits "Bitmask for property values described by StationaryTrackPropertyBits";
BA_ "UserSigValidity" SG_ 455 FLR_ST7_PropertyBits 3;
BA_ "Description" SG_ 455 FLR_ST7_Quality "Track quality";
BA_ "UserSigValidity" SG_ 455 FLR_ST7_Quality 3;
BA_ "Description" SG_ 455 FLR_ST7_X_Velocity "Filtered absolute longitudinal velocity";
BA_ "UserSigValidity" SG_ 455 FLR_ST7_X_Velocity 3;
BA_ "Description" SG_ 455 FLR_ST7_Y_Velocity "Filtered absolute lateral velocity";
BA_ "UserSigValidity" SG_ 455 FLR_ST7_Y_Velocity 3;
BA_ "Description" SG_ 456 FLR_ST8_CrcVal "The CRC checking process calculates the CRC over the entire data block, including the CRC result.

- CRC Polynomial (0x1021) , Initial Value : 0xFFFF, XOR value : 0x0000

- The mathematical expression to 16 bit CRC polynomial is given here. G(x) = x16 + ";
BA_ "GenSigStartValue" SG_ 456 FLR_ST8_CrcVal 65535;
BA_ "UserSigValidity" SG_ 456 FLR_ST8_CrcVal 3;
BA_ "Description" SG_ 456 FLR_ST8_AlvCntVal "[Alive counter] For the first transmission request for a data element the counter shall be initialized with 0 and shall be incremented by 1

for every subsequent send request. When the counter reaches the maximum value(0xFF), then it shall restart with â";
BA_ "UserSigValidity" SG_ 456 FLR_ST8_AlvCntVal 3;
BA_ "Description" SG_ 456 FLR_ST8_Elevation "Elevation Classification from Core Elevation Library";
BA_ "UserSigValidity" SG_ 456 FLR_ST8_Elevation 3;
BA_ "Description" SG_ 456 FLR_ST8_ElevationConfidence "	Elevation Classification Confidence Level from Core Elevation Library";
BA_ "UserSigValidity" SG_ 456 FLR_ST8_ElevationConfidence 3;
BA_ "Description" SG_ 456 FLR_ST8_Lifetime "Number of cycles the target has been alive. Unknown 0";
BA_ "UserSigValidity" SG_ 456 FLR_ST8_Lifetime 3;
BA_ "Description" SG_ 456 FLR_ST8_ObjectId "A global ID, which is constant as long as the object is tracked. Note! A value of 0 indicates 'no object'";
BA_ "UserSigValidity" SG_ 456 FLR_ST8_ObjectId 3;
BA_ "Description" SG_ 456 FLR_ST8_PositionX "Filtered X position";
BA_ "UserSigValidity" SG_ 456 FLR_ST8_PositionX 3;
BA_ "Description" SG_ 456 FLR_ST8_PositionY "Filtered Y position";
BA_ "UserSigValidity" SG_ 456 FLR_ST8_PositionY 3;
BA_ "Description" SG_ 456 FLR_ST8_PredictionCounter "Number of cycles the target has been predicted";
BA_ "UserSigValidity" SG_ 456 FLR_ST8_PredictionCounter 3;
BA_ "Description" SG_ 456 FLR_ST8_PropertyBits "Bitmask for property values described by StationaryTrackPropertyBits";
BA_ "UserSigValidity" SG_ 456 FLR_ST8_PropertyBits 3;
BA_ "Description" SG_ 456 FLR_ST8_Quality "Track quality";
BA_ "UserSigValidity" SG_ 456 FLR_ST8_Quality 3;
BA_ "Description" SG_ 456 FLR_ST8_X_Velocity "Filtered absolute longitudinal velocity";
BA_ "UserSigValidity" SG_ 456 FLR_ST8_X_Velocity 3;
BA_ "Description" SG_ 456 FLR_ST8_Y_Velocity "Filtered absolute lateral velocity";
BA_ "UserSigValidity" SG_ 456 FLR_ST8_Y_Velocity 3;
BA_ "Description" SG_ 457 FLR_ST9_CrcVal "The CRC checking process calculates the CRC over the entire data block, including the CRC result.

- CRC Polynomial (0x1021) , Initial Value : 0xFFFF, XOR value : 0x0000

- The mathematical expression to 16 bit CRC polynomial is given here. G(x) = x16 + ";
BA_ "GenSigStartValue" SG_ 457 FLR_ST9_CrcVal 65535;
BA_ "UserSigValidity" SG_ 457 FLR_ST9_CrcVal 3;
BA_ "Description" SG_ 457 FLR_ST9_AlvCntVal "[Alive counter] For the first transmission request for a data element the counter shall be initialized with 0 and shall be incremented by 1

for every subsequent send request. When the counter reaches the maximum value(0xFF), then it shall restart with â";
BA_ "UserSigValidity" SG_ 457 FLR_ST9_AlvCntVal 3;
BA_ "Description" SG_ 457 FLR_ST9_Elevation "Elevation Classification from Core Elevation Library";
BA_ "UserSigValidity" SG_ 457 FLR_ST9_Elevation 3;
BA_ "Description" SG_ 457 FLR_ST9_ElevationConfidence "	Elevation Classification Confidence Level from Core Elevation Library";
BA_ "UserSigValidity" SG_ 457 FLR_ST9_ElevationConfidence 3;
BA_ "Description" SG_ 457 FLR_ST9_Lifetime "Number of cycles the target has been alive. Unknown 0";
BA_ "UserSigValidity" SG_ 457 FLR_ST9_Lifetime 3;
BA_ "Description" SG_ 457 FLR_ST9_ObjectId "A global ID, which is constant as long as the object is tracked. Note! A value of 0 indicates 'no object'";
BA_ "UserSigValidity" SG_ 457 FLR_ST9_ObjectId 3;
BA_ "Description" SG_ 457 FLR_ST9_PositionX "Filtered X position";
BA_ "UserSigValidity" SG_ 457 FLR_ST9_PositionX 3;
BA_ "Description" SG_ 457 FLR_ST9_PositionY "Filtered Y position";
BA_ "UserSigValidity" SG_ 457 FLR_ST9_PositionY 3;
BA_ "Description" SG_ 457 FLR_ST9_PredictionCounter "Number of cycles the target has been predicted";
BA_ "UserSigValidity" SG_ 457 FLR_ST9_PredictionCounter 3;
BA_ "Description" SG_ 457 FLR_ST9_PropertyBits "Bitmask for property values described by StationaryTrackPropertyBits";
BA_ "UserSigValidity" SG_ 457 FLR_ST9_PropertyBits 3;
BA_ "Description" SG_ 457 FLR_ST9_Quality "Track quality";
BA_ "UserSigValidity" SG_ 457 FLR_ST9_Quality 3;
BA_ "Description" SG_ 457 FLR_ST9_X_Velocity "Filtered absolute longitudinal velocity";
BA_ "UserSigValidity" SG_ 457 FLR_ST9_X_Velocity 3;
BA_ "Description" SG_ 457 FLR_ST9_Y_Velocity "Filtered absolute lateral velocity";
BA_ "UserSigValidity" SG_ 457 FLR_ST9_Y_Velocity 3;
BA_ "Description" SG_ 458 FLR_ST10_CrcVal "The CRC checking process calculates the CRC over the entire data block, including the CRC result.

- CRC Polynomial (0x1021) , Initial Value : 0xFFFF, XOR value : 0x0000

- The mathematical expression to 16 bit CRC polynomial is given here. G(x) = x16 + ";
BA_ "GenSigStartValue" SG_ 458 FLR_ST10_CrcVal 65535;
BA_ "UserSigValidity" SG_ 458 FLR_ST10_CrcVal 3;
BA_ "Description" SG_ 458 FLR_ST10_AlvCntVal "[Alive counter] For the first transmission request for a data element the counter shall be initialized with 0 and shall be incremented by 1

for every subsequent send request. When the counter reaches the maximum value(0xFF), then it shall restart with â";
BA_ "UserSigValidity" SG_ 458 FLR_ST10_AlvCntVal 3;
BA_ "Description" SG_ 458 FLR_ST10_Elevation "Elevation Classification from Core Elevation Library";
BA_ "UserSigValidity" SG_ 458 FLR_ST10_Elevation 3;
BA_ "Description" SG_ 458 FLR_ST10_ElevationConfidence "	Elevation Classification Confidence Level from Core Elevation Library";
BA_ "UserSigValidity" SG_ 458 FLR_ST10_ElevationConfidence 3;
BA_ "Description" SG_ 458 FLR_ST10_Lifetime "Number of cycles the target has been alive. Unknown 0";
BA_ "UserSigValidity" SG_ 458 FLR_ST10_Lifetime 3;
BA_ "Description" SG_ 458 FLR_ST10_ObjectId "A global ID, which is constant as long as the object is tracked. Note! A value of 0 indicates 'no object'";
BA_ "UserSigValidity" SG_ 458 FLR_ST10_ObjectId 3;
BA_ "Description" SG_ 458 FLR_ST10_PositionX "Filtered X position";
BA_ "UserSigValidity" SG_ 458 FLR_ST10_PositionX 3;
BA_ "Description" SG_ 458 FLR_ST10_PositionY "Filtered Y position";
BA_ "UserSigValidity" SG_ 458 FLR_ST10_PositionY 3;
BA_ "Description" SG_ 458 FLR_ST10_PredictionCounter "Number of cycles the target has been predicted";
BA_ "UserSigValidity" SG_ 458 FLR_ST10_PredictionCounter 3;
BA_ "Description" SG_ 458 FLR_ST10_PropertyBits "Bitmask for property values described by StationaryTrackPropertyBits";
BA_ "UserSigValidity" SG_ 458 FLR_ST10_PropertyBits 3;
BA_ "Description" SG_ 458 FLR_ST10_Quality "Track quality";
BA_ "UserSigValidity" SG_ 458 FLR_ST10_Quality 3;
BA_ "Description" SG_ 458 FLR_ST10_X_Velocity "Filtered absolute longitudinal velocity";
BA_ "UserSigValidity" SG_ 458 FLR_ST10_X_Velocity 3;
BA_ "Description" SG_ 458 FLR_ST10_Y_Velocity "Filtered absolute lateral velocity";
BA_ "UserSigValidity" SG_ 458 FLR_ST10_Y_Velocity 3;
BA_ "Description" SG_ 459 FLR_ST11_CrcVal "The CRC checking process calculates the CRC over the entire data block, including the CRC result.

- CRC Polynomial (0x1021) , Initial Value : 0xFFFF, XOR value : 0x0000

- The mathematical expression to 16 bit CRC polynomial is given here. G(x) = x16 + ";
BA_ "GenSigStartValue" SG_ 459 FLR_ST11_CrcVal 65535;
BA_ "UserSigValidity" SG_ 459 FLR_ST11_CrcVal 3;
BA_ "Description" SG_ 459 FLR_ST11_AlvCntVal "[Alive counter] For the first transmission request for a data element the counter shall be initialized with 0 and shall be incremented by 1

for every subsequent send request. When the counter reaches the maximum value(0xFF), then it shall restart with â";
BA_ "UserSigValidity" SG_ 459 FLR_ST11_AlvCntVal 3;
BA_ "Description" SG_ 459 FLR_ST11_Elevation "Elevation Classification from Core Elevation Library";
BA_ "UserSigValidity" SG_ 459 FLR_ST11_Elevation 3;
BA_ "Description" SG_ 459 FLR_ST11_ElevationConfidence "	Elevation Classification Confidence Level from Core Elevation Library";
BA_ "UserSigValidity" SG_ 459 FLR_ST11_ElevationConfidence 3;
BA_ "Description" SG_ 459 FLR_ST11_Lifetime "Number of cycles the target has been alive. Unknown 0";
BA_ "UserSigValidity" SG_ 459 FLR_ST11_Lifetime 3;
BA_ "Description" SG_ 459 FLR_ST11_ObjectId "A global ID, which is constant as long as the object is tracked. Note! A value of 0 indicates 'no object'";
BA_ "UserSigValidity" SG_ 459 FLR_ST11_ObjectId 3;
BA_ "Description" SG_ 459 FLR_ST11_PositionX "Filtered X position";
BA_ "UserSigValidity" SG_ 459 FLR_ST11_PositionX 3;
BA_ "Description" SG_ 459 FLR_ST11_PositionY "Filtered Y position";
BA_ "UserSigValidity" SG_ 459 FLR_ST11_PositionY 3;
BA_ "Description" SG_ 459 FLR_ST11_PredictionCounter "Number of cycles the target has been predicted";
BA_ "UserSigValidity" SG_ 459 FLR_ST11_PredictionCounter 3;
BA_ "Description" SG_ 459 FLR_ST11_PropertyBits "Bitmask for property values described by StationaryTrackPropertyBits";
BA_ "UserSigValidity" SG_ 459 FLR_ST11_PropertyBits 3;
BA_ "Description" SG_ 459 FLR_ST11_Quality "Track quality";
BA_ "UserSigValidity" SG_ 459 FLR_ST11_Quality 3;
BA_ "Description" SG_ 459 FLR_ST11_X_Velocity "Filtered absolute longitudinal velocity";
BA_ "UserSigValidity" SG_ 459 FLR_ST11_X_Velocity 3;
BA_ "Description" SG_ 459 FLR_ST11_Y_Velocity "Filtered absolute lateral velocity";
BA_ "UserSigValidity" SG_ 459 FLR_ST11_Y_Velocity 3;
BA_ "Description" SG_ 460 FLR_ST12_CrcVal "The CRC checking process calculates the CRC over the entire data block, including the CRC result.

- CRC Polynomial (0x1021) , Initial Value : 0xFFFF, XOR value : 0x0000

- The mathematical expression to 16 bit CRC polynomial is given here. G(x) = x16 + ";
BA_ "GenSigStartValue" SG_ 460 FLR_ST12_CrcVal 65535;
BA_ "UserSigValidity" SG_ 460 FLR_ST12_CrcVal 3;
BA_ "Description" SG_ 460 FLR_ST12_AlvCntVal "[Alive counter] For the first transmission request for a data element the counter shall be initialized with 0 and shall be incremented by 1

for every subsequent send request. When the counter reaches the maximum value(0xFF), then it shall restart with â";
BA_ "UserSigValidity" SG_ 460 FLR_ST12_AlvCntVal 3;
BA_ "Description" SG_ 460 FLR_ST12_Elevation "Elevation Classification from Core Elevation Library";
BA_ "UserSigValidity" SG_ 460 FLR_ST12_Elevation 3;
BA_ "Description" SG_ 460 FLR_ST12_ElevationConfidence "	Elevation Classification Confidence Level from Core Elevation Library";
BA_ "UserSigValidity" SG_ 460 FLR_ST12_ElevationConfidence 3;
BA_ "Description" SG_ 460 FLR_ST12_Lifetime "Number of cycles the target has been alive. Unknown 0";
BA_ "UserSigValidity" SG_ 460 FLR_ST12_Lifetime 3;
BA_ "Description" SG_ 460 FLR_ST12_ObjectId "A global ID, which is constant as long as the object is tracked. Note! A value of 0 indicates 'no object'";
BA_ "UserSigValidity" SG_ 460 FLR_ST12_ObjectId 3;
BA_ "Description" SG_ 460 FLR_ST12_PositionX "Filtered X position";
BA_ "UserSigValidity" SG_ 460 FLR_ST12_PositionX 3;
BA_ "Description" SG_ 460 FLR_ST12_PositionY "Filtered Y position";
BA_ "UserSigValidity" SG_ 460 FLR_ST12_PositionY 3;
BA_ "Description" SG_ 460 FLR_ST12_PredictionCounter "Number of cycles the target has been predicted";
BA_ "UserSigValidity" SG_ 460 FLR_ST12_PredictionCounter 3;
BA_ "Description" SG_ 460 FLR_ST12_PropertyBits "Bitmask for property values described by StationaryTrackPropertyBits";
BA_ "UserSigValidity" SG_ 460 FLR_ST12_PropertyBits 3;
BA_ "Description" SG_ 460 FLR_ST12_Quality "Track quality";
BA_ "UserSigValidity" SG_ 460 FLR_ST12_Quality 3;
BA_ "Description" SG_ 460 FLR_ST12_X_Velocity "Filtered absolute longitudinal velocity";
BA_ "UserSigValidity" SG_ 460 FLR_ST12_X_Velocity 3;
BA_ "Description" SG_ 460 FLR_ST12_Y_Velocity "Filtered absolute lateral velocity";
BA_ "UserSigValidity" SG_ 460 FLR_ST12_Y_Velocity 3;
BA_ "Description" SG_ 461 FLR_ST13_CrcVal "The CRC checking process calculates the CRC over the entire data block, including the CRC result.

- CRC Polynomial (0x1021) , Initial Value : 0xFFFF, XOR value : 0x0000

- The mathematical expression to 16 bit CRC polynomial is given here. G(x) = x16 + ";
BA_ "GenSigStartValue" SG_ 461 FLR_ST13_CrcVal 65535;
BA_ "UserSigValidity" SG_ 461 FLR_ST13_CrcVal 3;
BA_ "Description" SG_ 461 FLR_ST13_AlvCntVal "[Alive counter] For the first transmission request for a data element the counter shall be initialized with 0 and shall be incremented by 1

for every subsequent send request. When the counter reaches the maximum value(0xFF), then it shall restart with â";
BA_ "UserSigValidity" SG_ 461 FLR_ST13_AlvCntVal 3;
BA_ "Description" SG_ 461 FLR_ST13_Elevation "Elevation Classification from Core Elevation Library";
BA_ "UserSigValidity" SG_ 461 FLR_ST13_Elevation 3;
BA_ "Description" SG_ 461 FLR_ST13_ElevationConfidence "	Elevation Classification Confidence Level from Core Elevation Library";
BA_ "UserSigValidity" SG_ 461 FLR_ST13_ElevationConfidence 3;
BA_ "Description" SG_ 461 FLR_ST13_Lifetime "Number of cycles the target has been alive. Unknown 0";
BA_ "UserSigValidity" SG_ 461 FLR_ST13_Lifetime 3;
BA_ "Description" SG_ 461 FLR_ST13_ObjectId "A global ID, which is constant as long as the object is tracked. Note! A value of 0 indicates 'no object'";
BA_ "UserSigValidity" SG_ 461 FLR_ST13_ObjectId 3;
BA_ "Description" SG_ 461 FLR_ST13_PositionX "Filtered X position";
BA_ "UserSigValidity" SG_ 461 FLR_ST13_PositionX 3;
BA_ "Description" SG_ 461 FLR_ST13_PositionY "Filtered Y position";
BA_ "UserSigValidity" SG_ 461 FLR_ST13_PositionY 3;
BA_ "Description" SG_ 461 FLR_ST13_PredictionCounter "Number of cycles the target has been predicted";
BA_ "UserSigValidity" SG_ 461 FLR_ST13_PredictionCounter 3;
BA_ "Description" SG_ 461 FLR_ST13_PropertyBits "Bitmask for property values described by StationaryTrackPropertyBits";
BA_ "UserSigValidity" SG_ 461 FLR_ST13_PropertyBits 3;
BA_ "Description" SG_ 461 FLR_ST13_Quality "Track quality";
BA_ "UserSigValidity" SG_ 461 FLR_ST13_Quality 3;
BA_ "Description" SG_ 461 FLR_ST13_X_Velocity "Filtered absolute longitudinal velocity";
BA_ "UserSigValidity" SG_ 461 FLR_ST13_X_Velocity 3;
BA_ "Description" SG_ 461 FLR_ST13_Y_Velocity "Filtered absolute lateral velocity";
BA_ "UserSigValidity" SG_ 461 FLR_ST13_Y_Velocity 3;
BA_ "Description" SG_ 462 FLR_ST14_CrcVal "The CRC checking process calculates the CRC over the entire data block, including the CRC result.

- CRC Polynomial (0x1021) , Initial Value : 0xFFFF, XOR value : 0x0000

- The mathematical expression to 16 bit CRC polynomial is given here. G(x) = x16 + ";
BA_ "GenSigStartValue" SG_ 462 FLR_ST14_CrcVal 65535;
BA_ "UserSigValidity" SG_ 462 FLR_ST14_CrcVal 3;
BA_ "Description" SG_ 462 FLR_ST14_AlvCntVal "[Alive counter] For the first transmission request for a data element the counter shall be initialized with 0 and shall be incremented by 1

for every subsequent send request. When the counter reaches the maximum value(0xFF), then it shall restart with â";
BA_ "UserSigValidity" SG_ 462 FLR_ST14_AlvCntVal 3;
BA_ "Description" SG_ 462 FLR_ST14_Elevation "Elevation Classification from Core Elevation Library";
BA_ "UserSigValidity" SG_ 462 FLR_ST14_Elevation 3;
BA_ "Description" SG_ 462 FLR_ST14_ElevationConfidence "	Elevation Classification Confidence Level from Core Elevation Library";
BA_ "UserSigValidity" SG_ 462 FLR_ST14_ElevationConfidence 3;
BA_ "Description" SG_ 462 FLR_ST14_Lifetime "Number of cycles the target has been alive. Unknown 0";
BA_ "UserSigValidity" SG_ 462 FLR_ST14_Lifetime 3;
BA_ "Description" SG_ 462 FLR_ST14_ObjectId "A global ID, which is constant as long as the object is tracked. Note! A value of 0 indicates 'no object'";
BA_ "UserSigValidity" SG_ 462 FLR_ST14_ObjectId 3;
BA_ "Description" SG_ 462 FLR_ST14_PositionX "Filtered X position";
BA_ "UserSigValidity" SG_ 462 FLR_ST14_PositionX 3;
BA_ "Description" SG_ 462 FLR_ST14_PositionY "Filtered Y position";
BA_ "UserSigValidity" SG_ 462 FLR_ST14_PositionY 3;
BA_ "Description" SG_ 462 FLR_ST14_PredictionCounter "Number of cycles the target has been predicted";
BA_ "UserSigValidity" SG_ 462 FLR_ST14_PredictionCounter 3;
BA_ "Description" SG_ 462 FLR_ST14_PropertyBits "Bitmask for property values described by StationaryTrackPropertyBits";
BA_ "UserSigValidity" SG_ 462 FLR_ST14_PropertyBits 3;
BA_ "Description" SG_ 462 FLR_ST14_Quality "Track quality";
BA_ "UserSigValidity" SG_ 462 FLR_ST14_Quality 3;
BA_ "Description" SG_ 462 FLR_ST14_X_Velocity "Filtered absolute longitudinal velocity";
BA_ "UserSigValidity" SG_ 462 FLR_ST14_X_Velocity 3;
BA_ "Description" SG_ 462 FLR_ST14_Y_Velocity "Filtered absolute lateral velocity";
BA_ "UserSigValidity" SG_ 462 FLR_ST14_Y_Velocity 3;
BA_ "Description" SG_ 463 FLR_ST15_CrcVal "The CRC checking process calculates the CRC over the entire data block, including the CRC result.

- CRC Polynomial (0x1021) , Initial Value : 0xFFFF, XOR value : 0x0000

- The mathematical expression to 16 bit CRC polynomial is given here. G(x) = x16 + ";
BA_ "GenSigStartValue" SG_ 463 FLR_ST15_CrcVal 65535;
BA_ "UserSigValidity" SG_ 463 FLR_ST15_CrcVal 3;
BA_ "Description" SG_ 463 FLR_ST15_AlvCntVal "[Alive counter] For the first transmission request for a data element the counter shall be initialized with 0 and shall be incremented by 1

for every subsequent send request. When the counter reaches the maximum value(0xFF), then it shall restart with â";
BA_ "UserSigValidity" SG_ 463 FLR_ST15_AlvCntVal 3;
BA_ "Description" SG_ 463 FLR_ST15_Elevation "Elevation Classification from Core Elevation Library";
BA_ "UserSigValidity" SG_ 463 FLR_ST15_Elevation 3;
BA_ "Description" SG_ 463 FLR_ST15_ElevationConfidence "	Elevation Classification Confidence Level from Core Elevation Library";
BA_ "UserSigValidity" SG_ 463 FLR_ST15_ElevationConfidence 3;
BA_ "Description" SG_ 463 FLR_ST15_Lifetime "Number of cycles the target has been alive. Unknown 0";
BA_ "UserSigValidity" SG_ 463 FLR_ST15_Lifetime 3;
BA_ "Description" SG_ 463 FLR_ST15_ObjectId "A global ID, which is constant as long as the object is tracked. Note! A value of 0 indicates 'no object'";
BA_ "UserSigValidity" SG_ 463 FLR_ST15_ObjectId 3;
BA_ "Description" SG_ 463 FLR_ST15_PositionX "Filtered X position";
BA_ "UserSigValidity" SG_ 463 FLR_ST15_PositionX 3;
BA_ "Description" SG_ 463 FLR_ST15_PositionY "Filtered Y position";
BA_ "UserSigValidity" SG_ 463 FLR_ST15_PositionY 3;
BA_ "Description" SG_ 463 FLR_ST15_PredictionCounter "Number of cycles the target has been predicted";
BA_ "UserSigValidity" SG_ 463 FLR_ST15_PredictionCounter 3;
BA_ "Description" SG_ 463 FLR_ST15_PropertyBits "Bitmask for property values described by StationaryTrackPropertyBits";
BA_ "UserSigValidity" SG_ 463 FLR_ST15_PropertyBits 3;
BA_ "Description" SG_ 463 FLR_ST15_Quality "Track quality";
BA_ "UserSigValidity" SG_ 463 FLR_ST15_Quality 3;
BA_ "Description" SG_ 463 FLR_ST15_X_Velocity "Filtered absolute longitudinal velocity";
BA_ "UserSigValidity" SG_ 463 FLR_ST15_X_Velocity 3;
BA_ "Description" SG_ 463 FLR_ST15_Y_Velocity "Filtered absolute lateral velocity";
BA_ "UserSigValidity" SG_ 463 FLR_ST15_Y_Velocity 3;
BA_ "Description" SG_ 464 FLR_ST16_CrcVal "The CRC checking process calculates the CRC over the entire data block, including the CRC result.

- CRC Polynomial (0x1021) , Initial Value : 0xFFFF, XOR value : 0x0000

- The mathematical expression to 16 bit CRC polynomial is given here. G(x) = x16 + ";
BA_ "GenSigStartValue" SG_ 464 FLR_ST16_CrcVal 65535;
BA_ "UserSigValidity" SG_ 464 FLR_ST16_CrcVal 3;
BA_ "Description" SG_ 464 FLR_ST16_AlvCntVal "[Alive counter] For the first transmission request for a data element the counter shall be initialized with 0 and shall be incremented by 1

for every subsequent send request. When the counter reaches the maximum value(0xFF), then it shall restart with â";
BA_ "UserSigValidity" SG_ 464 FLR_ST16_AlvCntVal 3;
BA_ "Description" SG_ 464 FLR_ST16_Elevation "Elevation Classification from Core Elevation Library";
BA_ "UserSigValidity" SG_ 464 FLR_ST16_Elevation 3;
BA_ "Description" SG_ 464 FLR_ST16_ElevationConfidence "	Elevation Classification Confidence Level from Core Elevation Library";
BA_ "UserSigValidity" SG_ 464 FLR_ST16_ElevationConfidence 3;
BA_ "Description" SG_ 464 FLR_ST16_Lifetime "Number of cycles the target has been alive. Unknown 0";
BA_ "UserSigValidity" SG_ 464 FLR_ST16_Lifetime 3;
BA_ "Description" SG_ 464 FLR_ST16_ObjectId "A global ID, which is constant as long as the object is tracked. Note! A value of 0 indicates 'no object'";
BA_ "UserSigValidity" SG_ 464 FLR_ST16_ObjectId 3;
BA_ "Description" SG_ 464 FLR_ST16_PositionX "Filtered X position";
BA_ "UserSigValidity" SG_ 464 FLR_ST16_PositionX 3;
BA_ "Description" SG_ 464 FLR_ST16_PositionY "Filtered Y position";
BA_ "UserSigValidity" SG_ 464 FLR_ST16_PositionY 3;
BA_ "Description" SG_ 464 FLR_ST16_PredictionCounter "Number of cycles the target has been predicted";
BA_ "UserSigValidity" SG_ 464 FLR_ST16_PredictionCounter 3;
BA_ "Description" SG_ 464 FLR_ST16_PropertyBits "Bitmask for property values described by StationaryTrackPropertyBits";
BA_ "UserSigValidity" SG_ 464 FLR_ST16_PropertyBits 3;
BA_ "Description" SG_ 464 FLR_ST16_Quality "Track quality";
BA_ "UserSigValidity" SG_ 464 FLR_ST16_Quality 3;
BA_ "Description" SG_ 464 FLR_ST16_X_Velocity "Filtered absolute longitudinal velocity";
BA_ "UserSigValidity" SG_ 464 FLR_ST16_X_Velocity 3;
BA_ "Description" SG_ 464 FLR_ST16_Y_Velocity "Filtered absolute lateral velocity";
BA_ "UserSigValidity" SG_ 464 FLR_ST16_Y_Velocity 3;
BA_ "Description" SG_ 465 FLR_ST17_CrcVal "The CRC checking process calculates the CRC over the entire data block, including the CRC result.

- CRC Polynomial (0x1021) , Initial Value : 0xFFFF, XOR value : 0x0000

- The mathematical expression to 16 bit CRC polynomial is given here. G(x) = x16 + ";
BA_ "GenSigStartValue" SG_ 465 FLR_ST17_CrcVal 65535;
BA_ "UserSigValidity" SG_ 465 FLR_ST17_CrcVal 3;
BA_ "Description" SG_ 465 FLR_ST17_AlvCntVal "[Alive counter] For the first transmission request for a data element the counter shall be initialized with 0 and shall be incremented by 1

for every subsequent send request. When the counter reaches the maximum value(0xFF), then it shall restart with â";
BA_ "UserSigValidity" SG_ 465 FLR_ST17_AlvCntVal 3;
BA_ "Description" SG_ 465 FLR_ST17_Elevation "Elevation Classification from Core Elevation Library";
BA_ "UserSigValidity" SG_ 465 FLR_ST17_Elevation 3;
BA_ "Description" SG_ 465 FLR_ST17_ElevationConfidence "	Elevation Classification Confidence Level from Core Elevation Library";
BA_ "UserSigValidity" SG_ 465 FLR_ST17_ElevationConfidence 3;
BA_ "Description" SG_ 465 FLR_ST17_Lifetime "Number of cycles the target has been alive. Unknown 0";
BA_ "UserSigValidity" SG_ 465 FLR_ST17_Lifetime 3;
BA_ "Description" SG_ 465 FLR_ST17_ObjectId "A global ID, which is constant as long as the object is tracked. Note! A value of 0 indicates 'no object'";
BA_ "UserSigValidity" SG_ 465 FLR_ST17_ObjectId 3;
BA_ "Description" SG_ 465 FLR_ST17_PositionX "Filtered X position";
BA_ "UserSigValidity" SG_ 465 FLR_ST17_PositionX 3;
BA_ "Description" SG_ 465 FLR_ST17_PositionY "Filtered Y position";
BA_ "UserSigValidity" SG_ 465 FLR_ST17_PositionY 3;
BA_ "Description" SG_ 465 FLR_ST17_PredictionCounter "Number of cycles the target has been predicted";
BA_ "UserSigValidity" SG_ 465 FLR_ST17_PredictionCounter 3;
BA_ "Description" SG_ 465 FLR_ST17_PropertyBits "Bitmask for property values described by StationaryTrackPropertyBits";
BA_ "UserSigValidity" SG_ 465 FLR_ST17_PropertyBits 3;
BA_ "Description" SG_ 465 FLR_ST17_Quality "Track quality";
BA_ "UserSigValidity" SG_ 465 FLR_ST17_Quality 3;
BA_ "Description" SG_ 465 FLR_ST17_X_Velocity "Filtered absolute longitudinal velocity";
BA_ "UserSigValidity" SG_ 465 FLR_ST17_X_Velocity 3;
BA_ "Description" SG_ 465 FLR_ST17_Y_Velocity "Filtered absolute lateral velocity";
BA_ "UserSigValidity" SG_ 465 FLR_ST17_Y_Velocity 3;
BA_ "Description" SG_ 466 FLR_ST18_CrcVal "The CRC checking process calculates the CRC over the entire data block, including the CRC result.

- CRC Polynomial (0x1021) , Initial Value : 0xFFFF, XOR value : 0x0000

- The mathematical expression to 16 bit CRC polynomial is given here. G(x) = x16 + ";
BA_ "GenSigStartValue" SG_ 466 FLR_ST18_CrcVal 65535;
BA_ "UserSigValidity" SG_ 466 FLR_ST18_CrcVal 3;
BA_ "Description" SG_ 466 FLR_ST18_AlvCntVal "[Alive counter] For the first transmission request for a data element the counter shall be initialized with 0 and shall be incremented by 1

for every subsequent send request. When the counter reaches the maximum value(0xFF), then it shall restart with â";
BA_ "UserSigValidity" SG_ 466 FLR_ST18_AlvCntVal 3;
BA_ "Description" SG_ 466 FLR_ST18_Elevation "Elevation Classification from Core Elevation Library";
BA_ "UserSigValidity" SG_ 466 FLR_ST18_Elevation 3;
BA_ "Description" SG_ 466 FLR_ST18_ElevationConfidence "	Elevation Classification Confidence Level from Core Elevation Library";
BA_ "UserSigValidity" SG_ 466 FLR_ST18_ElevationConfidence 3;
BA_ "Description" SG_ 466 FLR_ST18_Lifetime "Number of cycles the target has been alive. Unknown 0";
BA_ "UserSigValidity" SG_ 466 FLR_ST18_Lifetime 3;
BA_ "Description" SG_ 466 FLR_ST18_ObjectId "A global ID, which is constant as long as the object is tracked. Note! A value of 0 indicates 'no object'";
BA_ "UserSigValidity" SG_ 466 FLR_ST18_ObjectId 3;
BA_ "Description" SG_ 466 FLR_ST18_PositionX "Filtered X position";
BA_ "UserSigValidity" SG_ 466 FLR_ST18_PositionX 3;
BA_ "Description" SG_ 466 FLR_ST18_PositionY "Filtered Y position";
BA_ "UserSigValidity" SG_ 466 FLR_ST18_PositionY 3;
BA_ "Description" SG_ 466 FLR_ST18_PredictionCounter "Number of cycles the target has been predicted";
BA_ "UserSigValidity" SG_ 466 FLR_ST18_PredictionCounter 3;
BA_ "Description" SG_ 466 FLR_ST18_PropertyBits "Bitmask for property values described by StationaryTrackPropertyBits";
BA_ "UserSigValidity" SG_ 466 FLR_ST18_PropertyBits 3;
BA_ "Description" SG_ 466 FLR_ST18_Quality "Track quality";
BA_ "UserSigValidity" SG_ 466 FLR_ST18_Quality 3;
BA_ "Description" SG_ 466 FLR_ST18_X_Velocity "Filtered absolute longitudinal velocity";
BA_ "UserSigValidity" SG_ 466 FLR_ST18_X_Velocity 3;
BA_ "Description" SG_ 466 FLR_ST18_Y_Velocity "Filtered absolute lateral velocity";
BA_ "UserSigValidity" SG_ 466 FLR_ST18_Y_Velocity 3;
BA_ "Description" SG_ 467 FLR_ST19_CrcVal "The CRC checking process calculates the CRC over the entire data block, including the CRC result.

- CRC Polynomial (0x1021) , Initial Value : 0xFFFF, XOR value : 0x0000

- The mathematical expression to 16 bit CRC polynomial is given here. G(x) = x16 + ";
BA_ "GenSigStartValue" SG_ 467 FLR_ST19_CrcVal 65535;
BA_ "UserSigValidity" SG_ 467 FLR_ST19_CrcVal 3;
BA_ "Description" SG_ 467 FLR_ST19_AlvCntVal "[Alive counter] For the first transmission request for a data element the counter shall be initialized with 0 and shall be incremented by 1

for every subsequent send request. When the counter reaches the maximum value(0xFF), then it shall restart with â";
BA_ "UserSigValidity" SG_ 467 FLR_ST19_AlvCntVal 3;
BA_ "Description" SG_ 467 FLR_ST19_Elevation "Elevation Classification from Core Elevation Library";
BA_ "UserSigValidity" SG_ 467 FLR_ST19_Elevation 3;
BA_ "Description" SG_ 467 FLR_ST19_ElevationConfidence "	Elevation Classification Confidence Level from Core Elevation Library";
BA_ "UserSigValidity" SG_ 467 FLR_ST19_ElevationConfidence 3;
BA_ "Description" SG_ 467 FLR_ST19_Lifetime "Number of cycles the target has been alive. Unknown 0";
BA_ "UserSigValidity" SG_ 467 FLR_ST19_Lifetime 3;
BA_ "Description" SG_ 467 FLR_ST19_ObjectId "A global ID, which is constant as long as the object is tracked. Note! A value of 0 indicates 'no object'";
BA_ "UserSigValidity" SG_ 467 FLR_ST19_ObjectId 3;
BA_ "Description" SG_ 467 FLR_ST19_PositionX "Filtered X position";
BA_ "UserSigValidity" SG_ 467 FLR_ST19_PositionX 3;
BA_ "Description" SG_ 467 FLR_ST19_PositionY "Filtered Y position";
BA_ "UserSigValidity" SG_ 467 FLR_ST19_PositionY 3;
BA_ "Description" SG_ 467 FLR_ST19_PredictionCounter "Number of cycles the target has been predicted";
BA_ "UserSigValidity" SG_ 467 FLR_ST19_PredictionCounter 3;
BA_ "Description" SG_ 467 FLR_ST19_PropertyBits "Bitmask for property values described by StationaryTrackPropertyBits";
BA_ "UserSigValidity" SG_ 467 FLR_ST19_PropertyBits 3;
BA_ "Description" SG_ 467 FLR_ST19_Quality "Track quality";
BA_ "UserSigValidity" SG_ 467 FLR_ST19_Quality 3;
BA_ "Description" SG_ 467 FLR_ST19_X_Velocity "Filtered absolute longitudinal velocity";
BA_ "UserSigValidity" SG_ 467 FLR_ST19_X_Velocity 3;
BA_ "Description" SG_ 467 FLR_ST19_Y_Velocity "Filtered absolute lateral velocity";
BA_ "UserSigValidity" SG_ 467 FLR_ST19_Y_Velocity 3;
BA_ "Description" SG_ 468 FLR_ST20_CrcVal "The CRC checking process calculates the CRC over the entire data block, including the CRC result.

- CRC Polynomial (0x1021) , Initial Value : 0xFFFF, XOR value : 0x0000

- The mathematical expression to 16 bit CRC polynomial is given here. G(x) = x16 + ";
BA_ "GenSigStartValue" SG_ 468 FLR_ST20_CrcVal 65535;
BA_ "UserSigValidity" SG_ 468 FLR_ST20_CrcVal 3;
BA_ "Description" SG_ 468 FLR_ST20_AlvCntVal "[Alive counter] For the first transmission request for a data element the counter shall be initialized with 0 and shall be incremented by 1

for every subsequent send request. When the counter reaches the maximum value(0xFF), then it shall restart with â";
BA_ "UserSigValidity" SG_ 468 FLR_ST20_AlvCntVal 3;
BA_ "Description" SG_ 468 FLR_ST20_Elevation "Elevation Classification from Core Elevation Library";
BA_ "UserSigValidity" SG_ 468 FLR_ST20_Elevation 3;
BA_ "Description" SG_ 468 FLR_ST20_ElevationConfidence "	Elevation Classification Confidence Level from Core Elevation Library";
BA_ "UserSigValidity" SG_ 468 FLR_ST20_ElevationConfidence 3;
BA_ "Description" SG_ 468 FLR_ST20_Lifetime "Number of cycles the target has been alive. Unknown 0";
BA_ "UserSigValidity" SG_ 468 FLR_ST20_Lifetime 3;
BA_ "Description" SG_ 468 FLR_ST20_ObjectId "A global ID, which is constant as long as the object is tracked. Note! A value of 0 indicates 'no object'";
BA_ "UserSigValidity" SG_ 468 FLR_ST20_ObjectId 3;
BA_ "Description" SG_ 468 FLR_ST20_PositionX "Filtered X position";
BA_ "UserSigValidity" SG_ 468 FLR_ST20_PositionX 3;
BA_ "Description" SG_ 468 FLR_ST20_PositionY "Filtered Y position";
BA_ "UserSigValidity" SG_ 468 FLR_ST20_PositionY 3;
BA_ "Description" SG_ 468 FLR_ST20_PredictionCounter "Number of cycles the target has been predicted";
BA_ "UserSigValidity" SG_ 468 FLR_ST20_PredictionCounter 3;
BA_ "Description" SG_ 468 FLR_ST20_PropertyBits "Bitmask for property values described by StationaryTrackPropertyBits";
BA_ "UserSigValidity" SG_ 468 FLR_ST20_PropertyBits 3;
BA_ "Description" SG_ 468 FLR_ST20_Quality "Track quality";
BA_ "UserSigValidity" SG_ 468 FLR_ST20_Quality 3;
BA_ "Description" SG_ 468 FLR_ST20_X_Velocity "Filtered absolute longitudinal velocity";
BA_ "UserSigValidity" SG_ 468 FLR_ST20_X_Velocity 3;
BA_ "Description" SG_ 468 FLR_ST20_Y_Velocity "Filtered absolute lateral velocity";
BA_ "UserSigValidity" SG_ 468 FLR_ST20_Y_Velocity 3;
BA_ "Description" SG_ 469 FLR_ST21_CrcVal "The CRC checking process calculates the CRC over the entire data block, including the CRC result.

- CRC Polynomial (0x1021) , Initial Value : 0xFFFF, XOR value : 0x0000

- The mathematical expression to 16 bit CRC polynomial is given here. G(x) = x16 + ";
BA_ "GenSigStartValue" SG_ 469 FLR_ST21_CrcVal 65535;
BA_ "UserSigValidity" SG_ 469 FLR_ST21_CrcVal 3;
BA_ "Description" SG_ 469 FLR_ST21_AlvCntVal "[Alive counter] For the first transmission request for a data element the counter shall be initialized with 0 and shall be incremented by 1

for every subsequent send request. When the counter reaches the maximum value(0xFF), then it shall restart with â";
BA_ "UserSigValidity" SG_ 469 FLR_ST21_AlvCntVal 3;
BA_ "Description" SG_ 469 FLR_ST21_Elevation "Elevation Classification from Core Elevation Library";
BA_ "UserSigValidity" SG_ 469 FLR_ST21_Elevation 3;
BA_ "Description" SG_ 469 FLR_ST21_ElevationConfidence "	Elevation Classification Confidence Level from Core Elevation Library";
BA_ "UserSigValidity" SG_ 469 FLR_ST21_ElevationConfidence 3;
BA_ "Description" SG_ 469 FLR_ST21_Lifetime "Number of cycles the target has been alive. Unknown 0";
BA_ "UserSigValidity" SG_ 469 FLR_ST21_Lifetime 3;
BA_ "Description" SG_ 469 FLR_ST21_ObjectId "A global ID, which is constant as long as the object is tracked. Note! A value of 0 indicates 'no object'";
BA_ "UserSigValidity" SG_ 469 FLR_ST21_ObjectId 3;
BA_ "Description" SG_ 469 FLR_ST21_PositionX "Filtered X position";
BA_ "UserSigValidity" SG_ 469 FLR_ST21_PositionX 3;
BA_ "Description" SG_ 469 FLR_ST21_PositionY "Filtered Y position";
BA_ "UserSigValidity" SG_ 469 FLR_ST21_PositionY 3;
BA_ "Description" SG_ 469 FLR_ST21_PredictionCounter "Number of cycles the target has been predicted";
BA_ "UserSigValidity" SG_ 469 FLR_ST21_PredictionCounter 3;
BA_ "Description" SG_ 469 FLR_ST21_PropertyBits "Bitmask for property values described by StationaryTrackPropertyBits";
BA_ "UserSigValidity" SG_ 469 FLR_ST21_PropertyBits 3;
BA_ "Description" SG_ 469 FLR_ST21_Quality "Track quality";
BA_ "UserSigValidity" SG_ 469 FLR_ST21_Quality 3;
BA_ "Description" SG_ 469 FLR_ST21_X_Velocity "Filtered absolute longitudinal velocity";
BA_ "UserSigValidity" SG_ 469 FLR_ST21_X_Velocity 3;
BA_ "Description" SG_ 469 FLR_ST21_Y_Velocity "Filtered absolute lateral velocity";
BA_ "UserSigValidity" SG_ 469 FLR_ST21_Y_Velocity 3;
BA_ "Description" SG_ 470 FLR_ST22_CrcVal "The CRC checking process calculates the CRC over the entire data block, including the CRC result.

- CRC Polynomial (0x1021) , Initial Value : 0xFFFF, XOR value : 0x0000

- The mathematical expression to 16 bit CRC polynomial is given here. G(x) = x16 + ";
BA_ "GenSigStartValue" SG_ 470 FLR_ST22_CrcVal 65535;
BA_ "UserSigValidity" SG_ 470 FLR_ST22_CrcVal 3;
BA_ "Description" SG_ 470 FLR_ST22_AlvCntVal "[Alive counter] For the first transmission request for a data element the counter shall be initialized with 0 and shall be incremented by 1

for every subsequent send request. When the counter reaches the maximum value(0xFF), then it shall restart with â";
BA_ "UserSigValidity" SG_ 470 FLR_ST22_AlvCntVal 3;
BA_ "Description" SG_ 470 FLR_ST22_Elevation "Elevation Classification from Core Elevation Library";
BA_ "UserSigValidity" SG_ 470 FLR_ST22_Elevation 3;
BA_ "Description" SG_ 470 FLR_ST22_ElevationConfidence "	Elevation Classification Confidence Level from Core Elevation Library";
BA_ "UserSigValidity" SG_ 470 FLR_ST22_ElevationConfidence 3;
BA_ "Description" SG_ 470 FLR_ST22_Lifetime "Number of cycles the target has been alive. Unknown 0";
BA_ "UserSigValidity" SG_ 470 FLR_ST22_Lifetime 3;
BA_ "Description" SG_ 470 FLR_ST22_ObjectId "A global ID, which is constant as long as the object is tracked. Note! A value of 0 indicates 'no object'";
BA_ "UserSigValidity" SG_ 470 FLR_ST22_ObjectId 3;
BA_ "Description" SG_ 470 FLR_ST22_PositionX "Filtered X position";
BA_ "UserSigValidity" SG_ 470 FLR_ST22_PositionX 3;
BA_ "Description" SG_ 470 FLR_ST22_PositionY "Filtered Y position";
BA_ "UserSigValidity" SG_ 470 FLR_ST22_PositionY 3;
BA_ "Description" SG_ 470 FLR_ST22_PredictionCounter "Number of cycles the target has been predicted";
BA_ "UserSigValidity" SG_ 470 FLR_ST22_PredictionCounter 3;
BA_ "Description" SG_ 470 FLR_ST22_PropertyBits "Bitmask for property values described by StationaryTrackPropertyBits";
BA_ "UserSigValidity" SG_ 470 FLR_ST22_PropertyBits 3;
BA_ "Description" SG_ 470 FLR_ST22_Quality "Track quality";
BA_ "UserSigValidity" SG_ 470 FLR_ST22_Quality 3;
BA_ "Description" SG_ 470 FLR_ST22_X_Velocity "Filtered absolute longitudinal velocity";
BA_ "UserSigValidity" SG_ 470 FLR_ST22_X_Velocity 3;
BA_ "Description" SG_ 470 FLR_ST22_Y_Velocity "Filtered absolute lateral velocity";
BA_ "UserSigValidity" SG_ 470 FLR_ST22_Y_Velocity 3;
BA_ "Description" SG_ 471 FLR_ST23_CrcVal "The CRC checking process calculates the CRC over the entire data block, including the CRC result.

- CRC Polynomial (0x1021) , Initial Value : 0xFFFF, XOR value : 0x0000

- The mathematical expression to 16 bit CRC polynomial is given here. G(x) = x16 + ";
BA_ "GenSigStartValue" SG_ 471 FLR_ST23_CrcVal 65535;
BA_ "UserSigValidity" SG_ 471 FLR_ST23_CrcVal 3;
BA_ "Description" SG_ 471 FLR_ST23_AlvCntVal "[Alive counter] For the first transmission request for a data element the counter shall be initialized with 0 and shall be incremented by 1

for every subsequent send request. When the counter reaches the maximum value(0xFF), then it shall restart with â";
BA_ "UserSigValidity" SG_ 471 FLR_ST23_AlvCntVal 3;
BA_ "Description" SG_ 471 FLR_ST23_Elevation "Elevation Classification from Core Elevation Library";
BA_ "UserSigValidity" SG_ 471 FLR_ST23_Elevation 3;
BA_ "Description" SG_ 471 FLR_ST23_ElevationConfidence "	Elevation Classification Confidence Level from Core Elevation Library";
BA_ "UserSigValidity" SG_ 471 FLR_ST23_ElevationConfidence 3;
BA_ "Description" SG_ 471 FLR_ST23_Lifetime "Number of cycles the target has been alive. Unknown 0";
BA_ "UserSigValidity" SG_ 471 FLR_ST23_Lifetime 3;
BA_ "Description" SG_ 471 FLR_ST23_ObjectId "A global ID, which is constant as long as the object is tracked. Note! A value of 0 indicates 'no object'";
BA_ "UserSigValidity" SG_ 471 FLR_ST23_ObjectId 3;
BA_ "Description" SG_ 471 FLR_ST23_PositionX "Filtered X position";
BA_ "UserSigValidity" SG_ 471 FLR_ST23_PositionX 3;
BA_ "Description" SG_ 471 FLR_ST23_PositionY "Filtered Y position";
BA_ "UserSigValidity" SG_ 471 FLR_ST23_PositionY 3;
BA_ "Description" SG_ 471 FLR_ST23_PredictionCounter "Number of cycles the target has been predicted";
BA_ "UserSigValidity" SG_ 471 FLR_ST23_PredictionCounter 3;
BA_ "Description" SG_ 471 FLR_ST23_PropertyBits "Bitmask for property values described by StationaryTrackPropertyBits";
BA_ "UserSigValidity" SG_ 471 FLR_ST23_PropertyBits 3;
BA_ "Description" SG_ 471 FLR_ST23_Quality "Track quality";
BA_ "UserSigValidity" SG_ 471 FLR_ST23_Quality 3;
BA_ "Description" SG_ 471 FLR_ST23_X_Velocity "Filtered absolute longitudinal velocity";
BA_ "UserSigValidity" SG_ 471 FLR_ST23_X_Velocity 3;
BA_ "Description" SG_ 471 FLR_ST23_Y_Velocity "Filtered absolute lateral velocity";
BA_ "UserSigValidity" SG_ 471 FLR_ST23_Y_Velocity 3;
BA_ "Description" SG_ 472 FLR_ST24_CrcVal "The CRC checking process calculates the CRC over the entire data block, including the CRC result.

- CRC Polynomial (0x1021) , Initial Value : 0xFFFF, XOR value : 0x0000

- The mathematical expression to 16 bit CRC polynomial is given here. G(x) = x16 + ";
BA_ "GenSigStartValue" SG_ 472 FLR_ST24_CrcVal 65535;
BA_ "UserSigValidity" SG_ 472 FLR_ST24_CrcVal 3;
BA_ "Description" SG_ 472 FLR_ST24_AlvCntVal "[Alive counter] For the first transmission request for a data element the counter shall be initialized with 0 and shall be incremented by 1

for every subsequent send request. When the counter reaches the maximum value(0xFF), then it shall restart with â";
BA_ "UserSigValidity" SG_ 472 FLR_ST24_AlvCntVal 3;
BA_ "Description" SG_ 472 FLR_ST24_Elevation "Elevation Classification from Core Elevation Library";
BA_ "UserSigValidity" SG_ 472 FLR_ST24_Elevation 3;
BA_ "Description" SG_ 472 FLR_ST24_ElevationConfidence "	Elevation Classification Confidence Level from Core Elevation Library";
BA_ "UserSigValidity" SG_ 472 FLR_ST24_ElevationConfidence 3;
BA_ "Description" SG_ 472 FLR_ST24_Lifetime "Number of cycles the target has been alive. Unknown 0";
BA_ "UserSigValidity" SG_ 472 FLR_ST24_Lifetime 3;
BA_ "Description" SG_ 472 FLR_ST24_ObjectId "A global ID, which is constant as long as the object is tracked. Note! A value of 0 indicates 'no object'";
BA_ "UserSigValidity" SG_ 472 FLR_ST24_ObjectId 3;
BA_ "Description" SG_ 472 FLR_ST24_PositionX "Filtered X position";
BA_ "UserSigValidity" SG_ 472 FLR_ST24_PositionX 3;
BA_ "Description" SG_ 472 FLR_ST24_PositionY "Filtered Y position";
BA_ "UserSigValidity" SG_ 472 FLR_ST24_PositionY 3;
BA_ "Description" SG_ 472 FLR_ST24_PredictionCounter "Number of cycles the target has been predicted";
BA_ "UserSigValidity" SG_ 472 FLR_ST24_PredictionCounter 3;
BA_ "Description" SG_ 472 FLR_ST24_PropertyBits "Bitmask for property values described by StationaryTrackPropertyBits";
BA_ "UserSigValidity" SG_ 472 FLR_ST24_PropertyBits 3;
BA_ "Description" SG_ 472 FLR_ST24_Quality "Track quality";
BA_ "UserSigValidity" SG_ 472 FLR_ST24_Quality 3;
BA_ "Description" SG_ 472 FLR_ST24_X_Velocity "Filtered absolute longitudinal velocity";
BA_ "UserSigValidity" SG_ 472 FLR_ST24_X_Velocity 3;
BA_ "Description" SG_ 472 FLR_ST24_Y_Velocity "Filtered absolute lateral velocity";
BA_ "UserSigValidity" SG_ 472 FLR_ST24_Y_Velocity 3;
BA_ "Description" SG_ 473 FLR_ST25_CrcVal "The CRC checking process calculates the CRC over the entire data block, including the CRC result.

- CRC Polynomial (0x1021) , Initial Value : 0xFFFF, XOR value : 0x0000

- The mathematical expression to 16 bit CRC polynomial is given here. G(x) = x16 + ";
BA_ "GenSigStartValue" SG_ 473 FLR_ST25_CrcVal 65535;
BA_ "UserSigValidity" SG_ 473 FLR_ST25_CrcVal 3;
BA_ "Description" SG_ 473 FLR_ST25_AlvCntVal "[Alive counter] For the first transmission request for a data element the counter shall be initialized with 0 and shall be incremented by 1

for every subsequent send request. When the counter reaches the maximum value(0xFF), then it shall restart with â";
BA_ "UserSigValidity" SG_ 473 FLR_ST25_AlvCntVal 3;
BA_ "Description" SG_ 473 FLR_ST25_Elevation "Elevation Classification from Core Elevation Library";
BA_ "UserSigValidity" SG_ 473 FLR_ST25_Elevation 3;
BA_ "Description" SG_ 473 FLR_ST25_ElevationConfidence "	Elevation Classification Confidence Level from Core Elevation Library";
BA_ "UserSigValidity" SG_ 473 FLR_ST25_ElevationConfidence 3;
BA_ "Description" SG_ 473 FLR_ST25_Lifetime "Number of cycles the target has been alive. Unknown 0";
BA_ "UserSigValidity" SG_ 473 FLR_ST25_Lifetime 3;
BA_ "Description" SG_ 473 FLR_ST25_ObjectId "A global ID, which is constant as long as the object is tracked. Note! A value of 0 indicates 'no object'";
BA_ "UserSigValidity" SG_ 473 FLR_ST25_ObjectId 3;
BA_ "Description" SG_ 473 FLR_ST25_PositionX "Filtered X position";
BA_ "UserSigValidity" SG_ 473 FLR_ST25_PositionX 3;
BA_ "Description" SG_ 473 FLR_ST25_PositionY "Filtered Y position";
BA_ "UserSigValidity" SG_ 473 FLR_ST25_PositionY 3;
BA_ "Description" SG_ 473 FLR_ST25_PredictionCounter "Number of cycles the target has been predicted";
BA_ "UserSigValidity" SG_ 473 FLR_ST25_PredictionCounter 3;
BA_ "Description" SG_ 473 FLR_ST25_PropertyBits "Bitmask for property values described by StationaryTrackPropertyBits";
BA_ "UserSigValidity" SG_ 473 FLR_ST25_PropertyBits 3;
BA_ "Description" SG_ 473 FLR_ST25_Quality "Track quality";
BA_ "UserSigValidity" SG_ 473 FLR_ST25_Quality 3;
BA_ "Description" SG_ 473 FLR_ST25_X_Velocity "Filtered absolute longitudinal velocity";
BA_ "UserSigValidity" SG_ 473 FLR_ST25_X_Velocity 3;
BA_ "Description" SG_ 473 FLR_ST25_Y_Velocity "Filtered absolute lateral velocity";
BA_ "UserSigValidity" SG_ 473 FLR_ST25_Y_Velocity 3;
BA_ "Description" SG_ 474 FLR_ST26_CrcVal "The CRC checking process calculates the CRC over the entire data block, including the CRC result.

- CRC Polynomial (0x1021) , Initial Value : 0xFFFF, XOR value : 0x0000

- The mathematical expression to 16 bit CRC polynomial is given here. G(x) = x16 + ";
BA_ "GenSigStartValue" SG_ 474 FLR_ST26_CrcVal 65535;
BA_ "UserSigValidity" SG_ 474 FLR_ST26_CrcVal 3;
BA_ "Description" SG_ 474 FLR_ST26_AlvCntVal "[Alive counter] For the first transmission request for a data element the counter shall be initialized with 0 and shall be incremented by 1

for every subsequent send request. When the counter reaches the maximum value(0xFF), then it shall restart with â";
BA_ "UserSigValidity" SG_ 474 FLR_ST26_AlvCntVal 3;
BA_ "Description" SG_ 474 FLR_ST26_Elevation "Elevation Classification from Core Elevation Library";
BA_ "UserSigValidity" SG_ 474 FLR_ST26_Elevation 3;
BA_ "Description" SG_ 474 FLR_ST26_ElevationConfidence "	Elevation Classification Confidence Level from Core Elevation Library";
BA_ "UserSigValidity" SG_ 474 FLR_ST26_ElevationConfidence 3;
BA_ "Description" SG_ 474 FLR_ST26_Lifetime "Number of cycles the target has been alive. Unknown 0";
BA_ "UserSigValidity" SG_ 474 FLR_ST26_Lifetime 3;
BA_ "Description" SG_ 474 FLR_ST26_ObjectId "A global ID, which is constant as long as the object is tracked. Note! A value of 0 indicates 'no object'";
BA_ "UserSigValidity" SG_ 474 FLR_ST26_ObjectId 3;
BA_ "Description" SG_ 474 FLR_ST26_PositionX "Filtered X position";
BA_ "UserSigValidity" SG_ 474 FLR_ST26_PositionX 3;
BA_ "Description" SG_ 474 FLR_ST26_PositionY "Filtered Y position";
BA_ "UserSigValidity" SG_ 474 FLR_ST26_PositionY 3;
BA_ "Description" SG_ 474 FLR_ST26_PredictionCounter "Number of cycles the target has been predicted";
BA_ "UserSigValidity" SG_ 474 FLR_ST26_PredictionCounter 3;
BA_ "Description" SG_ 474 FLR_ST26_PropertyBits "Bitmask for property values described by StationaryTrackPropertyBits";
BA_ "UserSigValidity" SG_ 474 FLR_ST26_PropertyBits 3;
BA_ "Description" SG_ 474 FLR_ST26_Quality "Track quality";
BA_ "UserSigValidity" SG_ 474 FLR_ST26_Quality 3;
BA_ "Description" SG_ 474 FLR_ST26_X_Velocity "Filtered absolute longitudinal velocity";
BA_ "UserSigValidity" SG_ 474 FLR_ST26_X_Velocity 3;
BA_ "Description" SG_ 474 FLR_ST26_Y_Velocity "Filtered absolute lateral velocity";
BA_ "UserSigValidity" SG_ 474 FLR_ST26_Y_Velocity 3;
BA_ "Description" SG_ 475 FLR_ST27_CrcVal "The CRC checking process calculates the CRC over the entire data block, including the CRC result.

- CRC Polynomial (0x1021) , Initial Value : 0xFFFF, XOR value : 0x0000

- The mathematical expression to 16 bit CRC polynomial is given here. G(x) = x16 + ";
BA_ "GenSigStartValue" SG_ 475 FLR_ST27_CrcVal 65535;
BA_ "UserSigValidity" SG_ 475 FLR_ST27_CrcVal 3;
BA_ "Description" SG_ 475 FLR_ST27_AlvCntVal "[Alive counter] For the first transmission request for a data element the counter shall be initialized with 0 and shall be incremented by 1

for every subsequent send request. When the counter reaches the maximum value(0xFF), then it shall restart with â";
BA_ "UserSigValidity" SG_ 475 FLR_ST27_AlvCntVal 3;
BA_ "Description" SG_ 475 FLR_ST27_Elevation "Elevation Classification from Core Elevation Library";
BA_ "UserSigValidity" SG_ 475 FLR_ST27_Elevation 3;
BA_ "Description" SG_ 475 FLR_ST27_ElevationConfidence "	Elevation Classification Confidence Level from Core Elevation Library";
BA_ "UserSigValidity" SG_ 475 FLR_ST27_ElevationConfidence 3;
BA_ "Description" SG_ 475 FLR_ST27_Lifetime "Number of cycles the target has been alive. Unknown 0";
BA_ "UserSigValidity" SG_ 475 FLR_ST27_Lifetime 3;
BA_ "Description" SG_ 475 FLR_ST27_ObjectId "A global ID, which is constant as long as the object is tracked. Note! A value of 0 indicates 'no object'";
BA_ "UserSigValidity" SG_ 475 FLR_ST27_ObjectId 3;
BA_ "Description" SG_ 475 FLR_ST27_PositionX "Filtered X position";
BA_ "UserSigValidity" SG_ 475 FLR_ST27_PositionX 3;
BA_ "Description" SG_ 475 FLR_ST27_PositionY "Filtered Y position";
BA_ "UserSigValidity" SG_ 475 FLR_ST27_PositionY 3;
BA_ "Description" SG_ 475 FLR_ST27_PredictionCounter "Number of cycles the target has been predicted";
BA_ "UserSigValidity" SG_ 475 FLR_ST27_PredictionCounter 3;
BA_ "Description" SG_ 475 FLR_ST27_PropertyBits "Bitmask for property values described by StationaryTrackPropertyBits";
BA_ "UserSigValidity" SG_ 475 FLR_ST27_PropertyBits 3;
BA_ "Description" SG_ 475 FLR_ST27_Quality "Track quality";
BA_ "UserSigValidity" SG_ 475 FLR_ST27_Quality 3;
BA_ "Description" SG_ 475 FLR_ST27_X_Velocity "Filtered absolute longitudinal velocity";
BA_ "UserSigValidity" SG_ 475 FLR_ST27_X_Velocity 3;
BA_ "Description" SG_ 475 FLR_ST27_Y_Velocity "Filtered absolute lateral velocity";
BA_ "UserSigValidity" SG_ 475 FLR_ST27_Y_Velocity 3;
BA_ "Description" SG_ 476 FLR_ST28_CrcVal "The CRC checking process calculates the CRC over the entire data block, including the CRC result.

- CRC Polynomial (0x1021) , Initial Value : 0xFFFF, XOR value : 0x0000

- The mathematical expression to 16 bit CRC polynomial is given here. G(x) = x16 + ";
BA_ "GenSigStartValue" SG_ 476 FLR_ST28_CrcVal 65535;
BA_ "UserSigValidity" SG_ 476 FLR_ST28_CrcVal 3;
BA_ "Description" SG_ 476 FLR_ST28_AlvCntVal "[Alive counter] For the first transmission request for a data element the counter shall be initialized with 0 and shall be incremented by 1

for every subsequent send request. When the counter reaches the maximum value(0xFF), then it shall restart with â";
BA_ "UserSigValidity" SG_ 476 FLR_ST28_AlvCntVal 3;
BA_ "Description" SG_ 476 FLR_ST28_Elevation "Elevation Classification from Core Elevation Library";
BA_ "UserSigValidity" SG_ 476 FLR_ST28_Elevation 3;
BA_ "Description" SG_ 476 FLR_ST28_ElevationConfidence "	Elevation Classification Confidence Level from Core Elevation Library";
BA_ "UserSigValidity" SG_ 476 FLR_ST28_ElevationConfidence 3;
BA_ "Description" SG_ 476 FLR_ST28_Lifetime "Number of cycles the target has been alive. Unknown 0";
BA_ "UserSigValidity" SG_ 476 FLR_ST28_Lifetime 3;
BA_ "Description" SG_ 476 FLR_ST28_ObjectId "A global ID, which is constant as long as the object is tracked. Note! A value of 0 indicates 'no object'";
BA_ "UserSigValidity" SG_ 476 FLR_ST28_ObjectId 3;
BA_ "Description" SG_ 476 FLR_ST28_PositionX "Filtered X position";
BA_ "UserSigValidity" SG_ 476 FLR_ST28_PositionX 3;
BA_ "Description" SG_ 476 FLR_ST28_PositionY "Filtered Y position";
BA_ "UserSigValidity" SG_ 476 FLR_ST28_PositionY 3;
BA_ "Description" SG_ 476 FLR_ST28_PredictionCounter "Number of cycles the target has been predicted";
BA_ "UserSigValidity" SG_ 476 FLR_ST28_PredictionCounter 3;
BA_ "Description" SG_ 476 FLR_ST28_PropertyBits "Bitmask for property values described by StationaryTrackPropertyBits";
BA_ "UserSigValidity" SG_ 476 FLR_ST28_PropertyBits 3;
BA_ "Description" SG_ 476 FLR_ST28_Quality "Track quality";
BA_ "UserSigValidity" SG_ 476 FLR_ST28_Quality 3;
BA_ "Description" SG_ 476 FLR_ST28_X_Velocity "Filtered absolute longitudinal velocity";
BA_ "UserSigValidity" SG_ 476 FLR_ST28_X_Velocity 3;
BA_ "Description" SG_ 476 FLR_ST28_Y_Velocity "Filtered absolute lateral velocity";
BA_ "UserSigValidity" SG_ 476 FLR_ST28_Y_Velocity 3;
BA_ "Description" SG_ 477 FLR_ST29_CrcVal "The CRC checking process calculates the CRC over the entire data block, including the CRC result.

- CRC Polynomial (0x1021) , Initial Value : 0xFFFF, XOR value : 0x0000

- The mathematical expression to 16 bit CRC polynomial is given here. G(x) = x16 + ";
BA_ "GenSigStartValue" SG_ 477 FLR_ST29_CrcVal 65535;
BA_ "UserSigValidity" SG_ 477 FLR_ST29_CrcVal 3;
BA_ "Description" SG_ 477 FLR_ST29_AlvCntVal "[Alive counter] For the first transmission request for a data element the counter shall be initialized with 0 and shall be incremented by 1

for every subsequent send request. When the counter reaches the maximum value(0xFF), then it shall restart with â";
BA_ "UserSigValidity" SG_ 477 FLR_ST29_AlvCntVal 3;
BA_ "Description" SG_ 477 FLR_ST29_Elevation "Elevation Classification from Core Elevation Library";
BA_ "UserSigValidity" SG_ 477 FLR_ST29_Elevation 3;
BA_ "Description" SG_ 477 FLR_ST29_ElevationConfidence "	Elevation Classification Confidence Level from Core Elevation Library";
BA_ "UserSigValidity" SG_ 477 FLR_ST29_ElevationConfidence 3;
BA_ "Description" SG_ 477 FLR_ST29_Lifetime "Number of cycles the target has been alive. Unknown 0";
BA_ "UserSigValidity" SG_ 477 FLR_ST29_Lifetime 3;
BA_ "Description" SG_ 477 FLR_ST29_ObjectId "A global ID, which is constant as long as the object is tracked. Note! A value of 0 indicates 'no object'";
BA_ "UserSigValidity" SG_ 477 FLR_ST29_ObjectId 3;
BA_ "Description" SG_ 477 FLR_ST29_PositionX "Filtered X position";
BA_ "UserSigValidity" SG_ 477 FLR_ST29_PositionX 3;
BA_ "Description" SG_ 477 FLR_ST29_PositionY "Filtered Y position";
BA_ "UserSigValidity" SG_ 477 FLR_ST29_PositionY 3;
BA_ "Description" SG_ 477 FLR_ST29_PredictionCounter "Number of cycles the target has been predicted";
BA_ "UserSigValidity" SG_ 477 FLR_ST29_PredictionCounter 3;
BA_ "Description" SG_ 477 FLR_ST29_PropertyBits "Bitmask for property values described by StationaryTrackPropertyBits";
BA_ "UserSigValidity" SG_ 477 FLR_ST29_PropertyBits 3;
BA_ "Description" SG_ 477 FLR_ST29_Quality "Track quality";
BA_ "UserSigValidity" SG_ 477 FLR_ST29_Quality 3;
BA_ "Description" SG_ 477 FLR_ST29_X_Velocity "Filtered absolute longitudinal velocity";
BA_ "UserSigValidity" SG_ 477 FLR_ST29_X_Velocity 3;
BA_ "Description" SG_ 477 FLR_ST29_Y_Velocity "Filtered absolute lateral velocity";
BA_ "UserSigValidity" SG_ 477 FLR_ST29_Y_Velocity 3;
BA_ "Description" SG_ 478 FLR_ST30_CrcVal "The CRC checking process calculates the CRC over the entire data block, including the CRC result.

- CRC Polynomial (0x1021) , Initial Value : 0xFFFF, XOR value : 0x0000

- The mathematical expression to 16 bit CRC polynomial is given here. G(x) = x16 + ";
BA_ "GenSigStartValue" SG_ 478 FLR_ST30_CrcVal 65535;
BA_ "UserSigValidity" SG_ 478 FLR_ST30_CrcVal 3;
BA_ "Description" SG_ 478 FLR_ST30_AlvCntVal "[Alive counter] For the first transmission request for a data element the counter shall be initialized with 0 and shall be incremented by 1

for every subsequent send request. When the counter reaches the maximum value(0xFF), then it shall restart with â";
BA_ "UserSigValidity" SG_ 478 FLR_ST30_AlvCntVal 3;
BA_ "Description" SG_ 478 FLR_ST30_Elevation "Elevation Classification from Core Elevation Library";
BA_ "UserSigValidity" SG_ 478 FLR_ST30_Elevation 3;
BA_ "Description" SG_ 478 FLR_ST30_ElevationConfidence "	Elevation Classification Confidence Level from Core Elevation Library";
BA_ "UserSigValidity" SG_ 478 FLR_ST30_ElevationConfidence 3;
BA_ "Description" SG_ 478 FLR_ST30_Lifetime "Number of cycles the target has been alive. Unknown 0";
BA_ "UserSigValidity" SG_ 478 FLR_ST30_Lifetime 3;
BA_ "Description" SG_ 478 FLR_ST30_ObjectId "A global ID, which is constant as long as the object is tracked. Note! A value of 0 indicates 'no object'";
BA_ "UserSigValidity" SG_ 478 FLR_ST30_ObjectId 3;
BA_ "Description" SG_ 478 FLR_ST30_PositionX "Filtered X position";
BA_ "UserSigValidity" SG_ 478 FLR_ST30_PositionX 3;
BA_ "Description" SG_ 478 FLR_ST30_PositionY "Filtered Y position";
BA_ "UserSigValidity" SG_ 478 FLR_ST30_PositionY 3;
BA_ "Description" SG_ 478 FLR_ST30_PredictionCounter "Number of cycles the target has been predicted";
BA_ "UserSigValidity" SG_ 478 FLR_ST30_PredictionCounter 3;
BA_ "Description" SG_ 478 FLR_ST30_PropertyBits "Bitmask for property values described by StationaryTrackPropertyBits";
BA_ "UserSigValidity" SG_ 478 FLR_ST30_PropertyBits 3;
BA_ "Description" SG_ 478 FLR_ST30_Quality "Track quality";
BA_ "UserSigValidity" SG_ 478 FLR_ST30_Quality 3;
BA_ "Description" SG_ 478 FLR_ST30_X_Velocity "Filtered absolute longitudinal velocity";
BA_ "UserSigValidity" SG_ 478 FLR_ST30_X_Velocity 3;
BA_ "Description" SG_ 478 FLR_ST30_Y_Velocity "Filtered absolute lateral velocity";
BA_ "UserSigValidity" SG_ 478 FLR_ST30_Y_Velocity 3;
BA_ "Description" SG_ 479 FLR_ST31_CrcVal "The CRC checking process calculates the CRC over the entire data block, including the CRC result.

- CRC Polynomial (0x1021) , Initial Value : 0xFFFF, XOR value : 0x0000

- The mathematical expression to 16 bit CRC polynomial is given here. G(x) = x16 + ";
BA_ "GenSigStartValue" SG_ 479 FLR_ST31_CrcVal 65535;
BA_ "UserSigValidity" SG_ 479 FLR_ST31_CrcVal 3;
BA_ "Description" SG_ 479 FLR_ST31_AlvCntVal "[Alive counter] For the first transmission request for a data element the counter shall be initialized with 0 and shall be incremented by 1

for every subsequent send request. When the counter reaches the maximum value(0xFF), then it shall restart with â";
BA_ "UserSigValidity" SG_ 479 FLR_ST31_AlvCntVal 3;
BA_ "Description" SG_ 479 FLR_ST31_Elevation "Elevation Classification from Core Elevation Library";
BA_ "UserSigValidity" SG_ 479 FLR_ST31_Elevation 3;
BA_ "Description" SG_ 479 FLR_ST31_ElevationConfidence "	Elevation Classification Confidence Level from Core Elevation Library";
BA_ "UserSigValidity" SG_ 479 FLR_ST31_ElevationConfidence 3;
BA_ "Description" SG_ 479 FLR_ST31_Lifetime "Number of cycles the target has been alive. Unknown 0";
BA_ "UserSigValidity" SG_ 479 FLR_ST31_Lifetime 3;
BA_ "Description" SG_ 479 FLR_ST31_ObjectId "A global ID, which is constant as long as the object is tracked. Note! A value of 0 indicates 'no object'";
BA_ "UserSigValidity" SG_ 479 FLR_ST31_ObjectId 3;
BA_ "Description" SG_ 479 FLR_ST31_PositionX "Filtered X position";
BA_ "UserSigValidity" SG_ 479 FLR_ST31_PositionX 3;
BA_ "Description" SG_ 479 FLR_ST31_PositionY "Filtered Y position";
BA_ "UserSigValidity" SG_ 479 FLR_ST31_PositionY 3;
BA_ "Description" SG_ 479 FLR_ST31_PredictionCounter "Number of cycles the target has been predicted";
BA_ "UserSigValidity" SG_ 479 FLR_ST31_PredictionCounter 3;
BA_ "Description" SG_ 479 FLR_ST31_PropertyBits "Bitmask for property values described by StationaryTrackPropertyBits";
BA_ "UserSigValidity" SG_ 479 FLR_ST31_PropertyBits 3;
BA_ "Description" SG_ 479 FLR_ST31_Quality "Track quality";
BA_ "UserSigValidity" SG_ 479 FLR_ST31_Quality 3;
BA_ "Description" SG_ 479 FLR_ST31_X_Velocity "Filtered absolute longitudinal velocity";
BA_ "UserSigValidity" SG_ 479 FLR_ST31_X_Velocity 3;
BA_ "Description" SG_ 479 FLR_ST31_Y_Velocity "Filtered absolute lateral velocity";
BA_ "UserSigValidity" SG_ 479 FLR_ST31_Y_Velocity 3;
BA_ "Description" SG_ 480 FLR_ST32_CrcVal "The CRC checking process calculates the CRC over the entire data block, including the CRC result.

- CRC Polynomial (0x1021) , Initial Value : 0xFFFF, XOR value : 0x0000

- The mathematical expression to 16 bit CRC polynomial is given here. G(x) = x16 + ";
BA_ "GenSigStartValue" SG_ 480 FLR_ST32_CrcVal 65535;
BA_ "UserSigValidity" SG_ 480 FLR_ST32_CrcVal 3;
BA_ "Description" SG_ 480 FLR_ST32_AlvCntVal "[Alive counter] For the first transmission request for a data element the counter shall be initialized with 0 and shall be incremented by 1

for every subsequent send request. When the counter reaches the maximum value(0xFF), then it shall restart with â";
BA_ "UserSigValidity" SG_ 480 FLR_ST32_AlvCntVal 3;
BA_ "Description" SG_ 480 FLR_ST32_Elevation "Elevation Classification from Core Elevation Library";
BA_ "UserSigValidity" SG_ 480 FLR_ST32_Elevation 3;
BA_ "Description" SG_ 480 FLR_ST32_ElevationConfidence "	Elevation Classification Confidence Level from Core Elevation Library";
BA_ "UserSigValidity" SG_ 480 FLR_ST32_ElevationConfidence 3;
BA_ "Description" SG_ 480 FLR_ST32_Lifetime "Number of cycles the target has been alive. Unknown 0";
BA_ "UserSigValidity" SG_ 480 FLR_ST32_Lifetime 3;
BA_ "Description" SG_ 480 FLR_ST32_ObjectId "A global ID, which is constant as long as the object is tracked. Note! A value of 0 indicates 'no object'";
BA_ "UserSigValidity" SG_ 480 FLR_ST32_ObjectId 3;
BA_ "Description" SG_ 480 FLR_ST32_PositionX "Filtered X position";
BA_ "UserSigValidity" SG_ 480 FLR_ST32_PositionX 3;
BA_ "Description" SG_ 480 FLR_ST32_PositionY "Filtered Y position";
BA_ "UserSigValidity" SG_ 480 FLR_ST32_PositionY 3;
BA_ "Description" SG_ 480 FLR_ST32_PredictionCounter "Number of cycles the target has been predicted";
BA_ "UserSigValidity" SG_ 480 FLR_ST32_PredictionCounter 3;
BA_ "Description" SG_ 480 FLR_ST32_PropertyBits "Bitmask for property values described by StationaryTrackPropertyBits";
BA_ "UserSigValidity" SG_ 480 FLR_ST32_PropertyBits 3;
BA_ "Description" SG_ 480 FLR_ST32_Quality "Track quality";
BA_ "UserSigValidity" SG_ 480 FLR_ST32_Quality 3;
BA_ "Description" SG_ 480 FLR_ST32_X_Velocity "Filtered absolute longitudinal velocity";
BA_ "UserSigValidity" SG_ 480 FLR_ST32_X_Velocity 3;
BA_ "Description" SG_ 480 FLR_ST32_Y_Velocity "Filtered absolute lateral velocity";
BA_ "UserSigValidity" SG_ 480 FLR_ST32_Y_Velocity 3;
BA_ "Description" SG_ 481 FLR_ST33_CrcVal "The CRC checking process calculates the CRC over the entire data block, including the CRC result.

- CRC Polynomial (0x1021) , Initial Value : 0xFFFF, XOR value : 0x0000

- The mathematical expression to 16 bit CRC polynomial is given here. G(x) = x16 + ";
BA_ "GenSigStartValue" SG_ 481 FLR_ST33_CrcVal 65535;
BA_ "UserSigValidity" SG_ 481 FLR_ST33_CrcVal 3;
BA_ "Description" SG_ 481 FLR_ST33_AlvCntVal "[Alive counter] For the first transmission request for a data element the counter shall be initialized with 0 and shall be incremented by 1

for every subsequent send request. When the counter reaches the maximum value(0xFF), then it shall restart with â";
BA_ "UserSigValidity" SG_ 481 FLR_ST33_AlvCntVal 3;
BA_ "Description" SG_ 481 FLR_ST33_Elevation "Elevation Classification from Core Elevation Library";
BA_ "UserSigValidity" SG_ 481 FLR_ST33_Elevation 3;
BA_ "Description" SG_ 481 FLR_ST33_ElevationConfidence "	Elevation Classification Confidence Level from Core Elevation Library";
BA_ "UserSigValidity" SG_ 481 FLR_ST33_ElevationConfidence 3;
BA_ "Description" SG_ 481 FLR_ST33_Lifetime "Number of cycles the target has been alive. Unknown 0";
BA_ "UserSigValidity" SG_ 481 FLR_ST33_Lifetime 3;
BA_ "Description" SG_ 481 FLR_ST33_ObjectId "A global ID, which is constant as long as the object is tracked. Note! A value of 0 indicates 'no object'";
BA_ "UserSigValidity" SG_ 481 FLR_ST33_ObjectId 3;
BA_ "Description" SG_ 481 FLR_ST33_PositionX "Filtered X position";
BA_ "UserSigValidity" SG_ 481 FLR_ST33_PositionX 3;
BA_ "Description" SG_ 481 FLR_ST33_PositionY "Filtered Y position";
BA_ "UserSigValidity" SG_ 481 FLR_ST33_PositionY 3;
BA_ "Description" SG_ 481 FLR_ST33_PredictionCounter "Number of cycles the target has been predicted";
BA_ "UserSigValidity" SG_ 481 FLR_ST33_PredictionCounter 3;
BA_ "Description" SG_ 481 FLR_ST33_PropertyBits "Bitmask for property values described by StationaryTrackPropertyBits";
BA_ "UserSigValidity" SG_ 481 FLR_ST33_PropertyBits 3;
BA_ "Description" SG_ 481 FLR_ST33_Quality "Track quality";
BA_ "UserSigValidity" SG_ 481 FLR_ST33_Quality 3;
BA_ "Description" SG_ 481 FLR_ST33_X_Velocity "Filtered absolute longitudinal velocity";
BA_ "UserSigValidity" SG_ 481 FLR_ST33_X_Velocity 3;
BA_ "Description" SG_ 481 FLR_ST33_Y_Velocity "Filtered absolute lateral velocity";
BA_ "UserSigValidity" SG_ 481 FLR_ST33_Y_Velocity 3;
BA_ "Description" SG_ 482 FLR_ST34_CrcVal "The CRC checking process calculates the CRC over the entire data block, including the CRC result.

- CRC Polynomial (0x1021) , Initial Value : 0xFFFF, XOR value : 0x0000

- The mathematical expression to 16 bit CRC polynomial is given here. G(x) = x16 + ";
BA_ "GenSigStartValue" SG_ 482 FLR_ST34_CrcVal 65535;
BA_ "UserSigValidity" SG_ 482 FLR_ST34_CrcVal 3;
BA_ "Description" SG_ 482 FLR_ST34_AlvCntVal "[Alive counter] For the first transmission request for a data element the counter shall be initialized with 0 and shall be incremented by 1

for every subsequent send request. When the counter reaches the maximum value(0xFF), then it shall restart with â";
BA_ "UserSigValidity" SG_ 482 FLR_ST34_AlvCntVal 3;
BA_ "Description" SG_ 482 FLR_ST34_Elevation "Elevation Classification from Core Elevation Library";
BA_ "UserSigValidity" SG_ 482 FLR_ST34_Elevation 3;
BA_ "Description" SG_ 482 FLR_ST34_ElevationConfidence "	Elevation Classification Confidence Level from Core Elevation Library";
BA_ "UserSigValidity" SG_ 482 FLR_ST34_ElevationConfidence 3;
BA_ "Description" SG_ 482 FLR_ST34_Lifetime "Number of cycles the target has been alive. Unknown 0";
BA_ "UserSigValidity" SG_ 482 FLR_ST34_Lifetime 3;
BA_ "Description" SG_ 482 FLR_ST34_ObjectId "A global ID, which is constant as long as the object is tracked. Note! A value of 0 indicates 'no object'";
BA_ "UserSigValidity" SG_ 482 FLR_ST34_ObjectId 3;
BA_ "Description" SG_ 482 FLR_ST34_PositionX "Filtered X position";
BA_ "UserSigValidity" SG_ 482 FLR_ST34_PositionX 3;
BA_ "Description" SG_ 482 FLR_ST34_PositionY "Filtered Y position";
BA_ "UserSigValidity" SG_ 482 FLR_ST34_PositionY 3;
BA_ "Description" SG_ 482 FLR_ST34_PredictionCounter "Number of cycles the target has been predicted";
BA_ "UserSigValidity" SG_ 482 FLR_ST34_PredictionCounter 3;
BA_ "Description" SG_ 482 FLR_ST34_PropertyBits "Bitmask for property values described by StationaryTrackPropertyBits";
BA_ "UserSigValidity" SG_ 482 FLR_ST34_PropertyBits 3;
BA_ "Description" SG_ 482 FLR_ST34_Quality "Track quality";
BA_ "UserSigValidity" SG_ 482 FLR_ST34_Quality 3;
BA_ "Description" SG_ 482 FLR_ST34_X_Velocity "Filtered absolute longitudinal velocity";
BA_ "UserSigValidity" SG_ 482 FLR_ST34_X_Velocity 3;
BA_ "Description" SG_ 482 FLR_ST34_Y_Velocity "Filtered absolute lateral velocity";
BA_ "UserSigValidity" SG_ 482 FLR_ST34_Y_Velocity 3;
BA_ "Description" SG_ 483 FLR_ST35_CrcVal "The CRC checking process calculates the CRC over the entire data block, including the CRC result.

- CRC Polynomial (0x1021) , Initial Value : 0xFFFF, XOR value : 0x0000

- The mathematical expression to 16 bit CRC polynomial is given here. G(x) = x16 + ";
BA_ "GenSigStartValue" SG_ 483 FLR_ST35_CrcVal 65535;
BA_ "UserSigValidity" SG_ 483 FLR_ST35_CrcVal 3;
BA_ "Description" SG_ 483 FLR_ST35_AlvCntVal "[Alive counter] For the first transmission request for a data element the counter shall be initialized with 0 and shall be incremented by 1

for every subsequent send request. When the counter reaches the maximum value(0xFF), then it shall restart with â";
BA_ "UserSigValidity" SG_ 483 FLR_ST35_AlvCntVal 3;
BA_ "Description" SG_ 483 FLR_ST35_Elevation "Elevation Classification from Core Elevation Library";
BA_ "UserSigValidity" SG_ 483 FLR_ST35_Elevation 3;
BA_ "Description" SG_ 483 FLR_ST35_ElevationConfidence "	Elevation Classification Confidence Level from Core Elevation Library";
BA_ "UserSigValidity" SG_ 483 FLR_ST35_ElevationConfidence 3;
BA_ "Description" SG_ 483 FLR_ST35_Lifetime "Number of cycles the target has been alive. Unknown 0";
BA_ "UserSigValidity" SG_ 483 FLR_ST35_Lifetime 3;
BA_ "Description" SG_ 483 FLR_ST35_ObjectId "A global ID, which is constant as long as the object is tracked. Note! A value of 0 indicates 'no object'";
BA_ "UserSigValidity" SG_ 483 FLR_ST35_ObjectId 3;
BA_ "Description" SG_ 483 FLR_ST35_PositionX "Filtered X position";
BA_ "UserSigValidity" SG_ 483 FLR_ST35_PositionX 3;
BA_ "Description" SG_ 483 FLR_ST35_PositionY "Filtered Y position";
BA_ "UserSigValidity" SG_ 483 FLR_ST35_PositionY 3;
BA_ "Description" SG_ 483 FLR_ST35_PredictionCounter "Number of cycles the target has been predicted";
BA_ "UserSigValidity" SG_ 483 FLR_ST35_PredictionCounter 3;
BA_ "Description" SG_ 483 FLR_ST35_PropertyBits "Bitmask for property values described by StationaryTrackPropertyBits";
BA_ "UserSigValidity" SG_ 483 FLR_ST35_PropertyBits 3;
BA_ "Description" SG_ 483 FLR_ST35_Quality "Track quality";
BA_ "UserSigValidity" SG_ 483 FLR_ST35_Quality 3;
BA_ "Description" SG_ 483 FLR_ST35_X_Velocity "Filtered absolute longitudinal velocity";
BA_ "UserSigValidity" SG_ 483 FLR_ST35_X_Velocity 3;
BA_ "Description" SG_ 483 FLR_ST35_Y_Velocity "Filtered absolute lateral velocity";
BA_ "UserSigValidity" SG_ 483 FLR_ST35_Y_Velocity 3;
BA_ "Description" SG_ 484 FLR_ST36_CrcVal "The CRC checking process calculates the CRC over the entire data block, including the CRC result.

- CRC Polynomial (0x1021) , Initial Value : 0xFFFF, XOR value : 0x0000

- The mathematical expression to 16 bit CRC polynomial is given here. G(x) = x16 + ";
BA_ "GenSigStartValue" SG_ 484 FLR_ST36_CrcVal 65535;
BA_ "UserSigValidity" SG_ 484 FLR_ST36_CrcVal 3;
BA_ "Description" SG_ 484 FLR_ST36_AlvCntVal "[Alive counter] For the first transmission request for a data element the counter shall be initialized with 0 and shall be incremented by 1

for every subsequent send request. When the counter reaches the maximum value(0xFF), then it shall restart with â";
BA_ "UserSigValidity" SG_ 484 FLR_ST36_AlvCntVal 3;
BA_ "Description" SG_ 484 FLR_ST36_Elevation "Elevation Classification from Core Elevation Library";
BA_ "UserSigValidity" SG_ 484 FLR_ST36_Elevation 3;
BA_ "Description" SG_ 484 FLR_ST36_ElevationConfidence "	Elevation Classification Confidence Level from Core Elevation Library";
BA_ "UserSigValidity" SG_ 484 FLR_ST36_ElevationConfidence 3;
BA_ "Description" SG_ 484 FLR_ST36_Lifetime "Number of cycles the target has been alive. Unknown 0";
BA_ "UserSigValidity" SG_ 484 FLR_ST36_Lifetime 3;
BA_ "Description" SG_ 484 FLR_ST36_ObjectId "A global ID, which is constant as long as the object is tracked. Note! A value of 0 indicates 'no object'";
BA_ "UserSigValidity" SG_ 484 FLR_ST36_ObjectId 3;
BA_ "Description" SG_ 484 FLR_ST36_PositionX "Filtered X position";
BA_ "UserSigValidity" SG_ 484 FLR_ST36_PositionX 3;
BA_ "Description" SG_ 484 FLR_ST36_PositionY "Filtered Y position";
BA_ "UserSigValidity" SG_ 484 FLR_ST36_PositionY 3;
BA_ "Description" SG_ 484 FLR_ST36_PredictionCounter "Number of cycles the target has been predicted";
BA_ "UserSigValidity" SG_ 484 FLR_ST36_PredictionCounter 3;
BA_ "Description" SG_ 484 FLR_ST36_PropertyBits "Bitmask for property values described by StationaryTrackPropertyBits";
BA_ "UserSigValidity" SG_ 484 FLR_ST36_PropertyBits 3;
BA_ "Description" SG_ 484 FLR_ST36_Quality "Track quality";
BA_ "UserSigValidity" SG_ 484 FLR_ST36_Quality 3;
BA_ "Description" SG_ 484 FLR_ST36_X_Velocity "Filtered absolute longitudinal velocity";
BA_ "UserSigValidity" SG_ 484 FLR_ST36_X_Velocity 3;
BA_ "Description" SG_ 484 FLR_ST36_Y_Velocity "Filtered absolute lateral velocity";
BA_ "UserSigValidity" SG_ 484 FLR_ST36_Y_Velocity 3;
BA_ "Description" SG_ 485 FLR_ST37_CrcVal "The CRC checking process calculates the CRC over the entire data block, including the CRC result.

- CRC Polynomial (0x1021) , Initial Value : 0xFFFF, XOR value : 0x0000

- The mathematical expression to 16 bit CRC polynomial is given here. G(x) = x16 + ";
BA_ "GenSigStartValue" SG_ 485 FLR_ST37_CrcVal 65535;
BA_ "UserSigValidity" SG_ 485 FLR_ST37_CrcVal 3;
BA_ "Description" SG_ 485 FLR_ST37_AlvCntVal "[Alive counter] For the first transmission request for a data element the counter shall be initialized with 0 and shall be incremented by 1

for every subsequent send request. When the counter reaches the maximum value(0xFF), then it shall restart with â";
BA_ "UserSigValidity" SG_ 485 FLR_ST37_AlvCntVal 3;
BA_ "Description" SG_ 485 FLR_ST37_Elevation "Elevation Classification from Core Elevation Library";
BA_ "UserSigValidity" SG_ 485 FLR_ST37_Elevation 3;
BA_ "Description" SG_ 485 FLR_ST37_ElevationConfidence "	Elevation Classification Confidence Level from Core Elevation Library";
BA_ "UserSigValidity" SG_ 485 FLR_ST37_ElevationConfidence 3;
BA_ "Description" SG_ 485 FLR_ST37_Lifetime "Number of cycles the target has been alive. Unknown 0";
BA_ "UserSigValidity" SG_ 485 FLR_ST37_Lifetime 3;
BA_ "Description" SG_ 485 FLR_ST37_ObjectId "A global ID, which is constant as long as the object is tracked. Note! A value of 0 indicates 'no object'";
BA_ "UserSigValidity" SG_ 485 FLR_ST37_ObjectId 3;
BA_ "Description" SG_ 485 FLR_ST37_PositionX "Filtered X position";
BA_ "UserSigValidity" SG_ 485 FLR_ST37_PositionX 3;
BA_ "Description" SG_ 485 FLR_ST37_PositionY "Filtered Y position";
BA_ "UserSigValidity" SG_ 485 FLR_ST37_PositionY 3;
BA_ "Description" SG_ 485 FLR_ST37_PredictionCounter "Number of cycles the target has been predicted";
BA_ "UserSigValidity" SG_ 485 FLR_ST37_PredictionCounter 3;
BA_ "Description" SG_ 485 FLR_ST37_PropertyBits "Bitmask for property values described by StationaryTrackPropertyBits";
BA_ "UserSigValidity" SG_ 485 FLR_ST37_PropertyBits 3;
BA_ "Description" SG_ 485 FLR_ST37_Quality "Track quality";
BA_ "UserSigValidity" SG_ 485 FLR_ST37_Quality 3;
BA_ "Description" SG_ 485 FLR_ST37_X_Velocity "Filtered absolute longitudinal velocity";
BA_ "UserSigValidity" SG_ 485 FLR_ST37_X_Velocity 3;
BA_ "Description" SG_ 485 FLR_ST37_Y_Velocity "Filtered absolute lateral velocity";
BA_ "UserSigValidity" SG_ 485 FLR_ST37_Y_Velocity 3;
BA_ "Description" SG_ 486 FLR_ST38_CrcVal "The CRC checking process calculates the CRC over the entire data block, including the CRC result.

- CRC Polynomial (0x1021) , Initial Value : 0xFFFF, XOR value : 0x0000

- The mathematical expression to 16 bit CRC polynomial is given here. G(x) = x16 + ";
BA_ "GenSigStartValue" SG_ 486 FLR_ST38_CrcVal 65535;
BA_ "UserSigValidity" SG_ 486 FLR_ST38_CrcVal 3;
BA_ "Description" SG_ 486 FLR_ST38_AlvCntVal "[Alive counter] For the first transmission request for a data element the counter shall be initialized with 0 and shall be incremented by 1

for every subsequent send request. When the counter reaches the maximum value(0xFF), then it shall restart with â";
BA_ "UserSigValidity" SG_ 486 FLR_ST38_AlvCntVal 3;
BA_ "Description" SG_ 486 FLR_ST38_Elevation "Elevation Classification from Core Elevation Library";
BA_ "UserSigValidity" SG_ 486 FLR_ST38_Elevation 3;
BA_ "Description" SG_ 486 FLR_ST38_ElevationConfidence "	Elevation Classification Confidence Level from Core Elevation Library";
BA_ "UserSigValidity" SG_ 486 FLR_ST38_ElevationConfidence 3;
BA_ "Description" SG_ 486 FLR_ST38_Lifetime "Number of cycles the target has been alive. Unknown 0";
BA_ "UserSigValidity" SG_ 486 FLR_ST38_Lifetime 3;
BA_ "Description" SG_ 486 FLR_ST38_ObjectId "A global ID, which is constant as long as the object is tracked. Note! A value of 0 indicates 'no object'";
BA_ "UserSigValidity" SG_ 486 FLR_ST38_ObjectId 3;
BA_ "Description" SG_ 486 FLR_ST38_PositionX "Filtered X position";
BA_ "UserSigValidity" SG_ 486 FLR_ST38_PositionX 3;
BA_ "Description" SG_ 486 FLR_ST38_PositionY "Filtered Y position";
BA_ "UserSigValidity" SG_ 486 FLR_ST38_PositionY 3;
BA_ "Description" SG_ 486 FLR_ST38_PredictionCounter "Number of cycles the target has been predicted";
BA_ "UserSigValidity" SG_ 486 FLR_ST38_PredictionCounter 3;
BA_ "Description" SG_ 486 FLR_ST38_PropertyBits "Bitmask for property values described by StationaryTrackPropertyBits";
BA_ "UserSigValidity" SG_ 486 FLR_ST38_PropertyBits 3;
BA_ "Description" SG_ 486 FLR_ST38_Quality "Track quality";
BA_ "UserSigValidity" SG_ 486 FLR_ST38_Quality 3;
BA_ "Description" SG_ 486 FLR_ST38_X_Velocity "Filtered absolute longitudinal velocity";
BA_ "UserSigValidity" SG_ 486 FLR_ST38_X_Velocity 3;
BA_ "Description" SG_ 486 FLR_ST38_Y_Velocity "Filtered absolute lateral velocity";
BA_ "UserSigValidity" SG_ 486 FLR_ST38_Y_Velocity 3;
BA_ "Description" SG_ 487 FLR_ST39_CrcVal "The CRC checking process calculates the CRC over the entire data block, including the CRC result.

- CRC Polynomial (0x1021) , Initial Value : 0xFFFF, XOR value : 0x0000

- The mathematical expression to 16 bit CRC polynomial is given here. G(x) = x16 + ";
BA_ "GenSigStartValue" SG_ 487 FLR_ST39_CrcVal 65535;
BA_ "UserSigValidity" SG_ 487 FLR_ST39_CrcVal 3;
BA_ "Description" SG_ 487 FLR_ST39_AlvCntVal "[Alive counter] For the first transmission request for a data element the counter shall be initialized with 0 and shall be incremented by 1

for every subsequent send request. When the counter reaches the maximum value(0xFF), then it shall restart with â";
BA_ "UserSigValidity" SG_ 487 FLR_ST39_AlvCntVal 3;
BA_ "Description" SG_ 487 FLR_ST39_Elevation "Elevation Classification from Core Elevation Library";
BA_ "UserSigValidity" SG_ 487 FLR_ST39_Elevation 3;
BA_ "Description" SG_ 487 FLR_ST39_ElevationConfidence "	Elevation Classification Confidence Level from Core Elevation Library";
BA_ "UserSigValidity" SG_ 487 FLR_ST39_ElevationConfidence 3;
BA_ "Description" SG_ 487 FLR_ST39_Lifetime "Number of cycles the target has been alive. Unknown 0";
BA_ "UserSigValidity" SG_ 487 FLR_ST39_Lifetime 3;
BA_ "Description" SG_ 487 FLR_ST39_ObjectId "A global ID, which is constant as long as the object is tracked. Note! A value of 0 indicates 'no object'";
BA_ "UserSigValidity" SG_ 487 FLR_ST39_ObjectId 3;
BA_ "Description" SG_ 487 FLR_ST39_PositionX "Filtered X position";
BA_ "UserSigValidity" SG_ 487 FLR_ST39_PositionX 3;
BA_ "Description" SG_ 487 FLR_ST39_PositionY "Filtered Y position";
BA_ "UserSigValidity" SG_ 487 FLR_ST39_PositionY 3;
BA_ "Description" SG_ 487 FLR_ST39_PredictionCounter "Number of cycles the target has been predicted";
BA_ "UserSigValidity" SG_ 487 FLR_ST39_PredictionCounter 3;
BA_ "Description" SG_ 487 FLR_ST39_PropertyBits "Bitmask for property values described by StationaryTrackPropertyBits";
BA_ "UserSigValidity" SG_ 487 FLR_ST39_PropertyBits 3;
BA_ "Description" SG_ 487 FLR_ST39_Quality "Track quality";
BA_ "UserSigValidity" SG_ 487 FLR_ST39_Quality 3;
BA_ "Description" SG_ 487 FLR_ST39_X_Velocity "Filtered absolute longitudinal velocity";
BA_ "UserSigValidity" SG_ 487 FLR_ST39_X_Velocity 3;
BA_ "Description" SG_ 487 FLR_ST39_Y_Velocity "Filtered absolute lateral velocity";
BA_ "UserSigValidity" SG_ 487 FLR_ST39_Y_Velocity 3;
BA_ "UsrSigPurpose" SG_ 1752 XCP_Tester_to_FLR_Sig 2;
BA_ "Version" SG_ 1752 XCP_Tester_to_FLR_Sig "20.04.24";
BA_ "Description" SG_ 1752 XCP_Tester_to_FLR_Sig "CTO Message ID from Tester to Radar via Camera";
BA_ "UserSigValidity" SG_ 1752 XCP_Tester_to_FLR_Sig 3;
BA_ "UsrSigPurpose" SG_ 1753 XCP_FLR_to_Tester_Sig 2;
BA_ "Version" SG_ 1753 XCP_FLR_to_Tester_Sig "20.04.24";
BA_ "UserSigValidity" SG_ 1753 XCP_FLR_to_Tester_Sig 3;
BA_ "UsrSigPurpose" SG_ 2000 GST_FR_RDR_Byte0 2;
BA_ "Version" SG_ 2000 GST_FR_RDR_Byte0 "20.03.05";
BA_ "UserSigValidity" SG_ 2000 GST_FR_RDR_Byte0 3;
BA_ "UsrSigPurpose" SG_ 2000 GST_FR_RDR_Byte1 2;
BA_ "Version" SG_ 2000 GST_FR_RDR_Byte1 "20.03.05";
BA_ "UserSigValidity" SG_ 2000 GST_FR_RDR_Byte1 3;
BA_ "UsrSigPurpose" SG_ 2000 GST_FR_RDR_Byte2 2;
BA_ "Version" SG_ 2000 GST_FR_RDR_Byte2 "20.03.05";
BA_ "UserSigValidity" SG_ 2000 GST_FR_RDR_Byte2 3;
BA_ "UsrSigPurpose" SG_ 2000 GST_FR_RDR_Byte3 2;
BA_ "Version" SG_ 2000 GST_FR_RDR_Byte3 "20.03.05";
BA_ "UserSigValidity" SG_ 2000 GST_FR_RDR_Byte3 3;
BA_ "UsrSigPurpose" SG_ 2000 GST_FR_RDR_Byte4 2;
BA_ "Version" SG_ 2000 GST_FR_RDR_Byte4 "20.03.05";
BA_ "UserSigValidity" SG_ 2000 GST_FR_RDR_Byte4 3;
BA_ "UsrSigPurpose" SG_ 2000 GST_FR_RDR_Byte5 2;
BA_ "Version" SG_ 2000 GST_FR_RDR_Byte5 "20.03.05";
BA_ "UserSigValidity" SG_ 2000 GST_FR_RDR_Byte5 3;
BA_ "UsrSigPurpose" SG_ 2000 GST_FR_RDR_Byte6 2;
BA_ "Version" SG_ 2000 GST_FR_RDR_Byte6 "20.03.05";
BA_ "UserSigValidity" SG_ 2000 GST_FR_RDR_Byte6 3;
BA_ "UsrSigPurpose" SG_ 2000 GST_FR_RDR_Byte7 2;
BA_ "Version" SG_ 2000 GST_FR_RDR_Byte7 "20.03.05";
BA_ "UserSigValidity" SG_ 2000 GST_FR_RDR_Byte7 3;
BA_ "UsrSigPurpose" SG_ 2008 FR_RDR_GST_Byte0 2;
BA_ "Version" SG_ 2008 FR_RDR_GST_Byte0 "20.03.05";
BA_ "UserSigValidity" SG_ 2008 FR_RDR_GST_Byte0 3;
BA_ "UsrSigPurpose" SG_ 2008 FR_RDR_GST_Byte1 2;
BA_ "Version" SG_ 2008 FR_RDR_GST_Byte1 "20.03.05";
BA_ "UserSigValidity" SG_ 2008 FR_RDR_GST_Byte1 3;
BA_ "UsrSigPurpose" SG_ 2008 FR_RDR_GST_Byte2 2;
BA_ "Version" SG_ 2008 FR_RDR_GST_Byte2 "20.03.05";
BA_ "UserSigValidity" SG_ 2008 FR_RDR_GST_Byte2 3;
BA_ "UsrSigPurpose" SG_ 2008 FR_RDR_GST_Byte3 2;
BA_ "Version" SG_ 2008 FR_RDR_GST_Byte3 "20.03.05";
BA_ "UserSigValidity" SG_ 2008 FR_RDR_GST_Byte3 3;
BA_ "UsrSigPurpose" SG_ 2008 FR_RDR_GST_Byte4 2;
BA_ "Version" SG_ 2008 FR_RDR_GST_Byte4 "20.03.05";
BA_ "UserSigValidity" SG_ 2008 FR_RDR_GST_Byte4 3;
BA_ "UsrSigPurpose" SG_ 2008 FR_RDR_GST_Byte5 2;
BA_ "Version" SG_ 2008 FR_RDR_GST_Byte5 "20.03.05";
BA_ "UserSigValidity" SG_ 2008 FR_RDR_GST_Byte5 3;
BA_ "UsrSigPurpose" SG_ 2008 FR_RDR_GST_Byte6 2;
BA_ "Version" SG_ 2008 FR_RDR_GST_Byte6 "20.03.05";
BA_ "UserSigValidity" SG_ 2008 FR_RDR_GST_Byte6 3;
BA_ "UsrSigPurpose" SG_ 2008 FR_RDR_GST_Byte7 2;
BA_ "Version" SG_ 2008 FR_RDR_GST_Byte7 "20.03.05";
BA_ "UserSigValidity" SG_ 2008 FR_RDR_GST_Byte7 3;
BA_ "UsrSigPurpose" SG_ 2015 GST_ALL_Byte0 2;
BA_ "Version" SG_ 2015 GST_ALL_Byte0 "20.03.05";
BA_ "UserSigValidity" SG_ 2015 GST_ALL_Byte0 3;
BA_ "UsrSigPurpose" SG_ 2015 GST_ALL_Byte1 2;
BA_ "Version" SG_ 2015 GST_ALL_Byte1 "20.03.05";
BA_ "UserSigValidity" SG_ 2015 GST_ALL_Byte1 3;
BA_ "UsrSigPurpose" SG_ 2015 GST_ALL_Byte2 2;
BA_ "Version" SG_ 2015 GST_ALL_Byte2 "20.03.05";
BA_ "UserSigValidity" SG_ 2015 GST_ALL_Byte2 3;
BA_ "UsrSigPurpose" SG_ 2015 GST_ALL_Byte3 2;
BA_ "Version" SG_ 2015 GST_ALL_Byte3 "20.03.05";
BA_ "UserSigValidity" SG_ 2015 GST_ALL_Byte3 3;
BA_ "UsrSigPurpose" SG_ 2015 GST_ALL_Byte4 2;
BA_ "Version" SG_ 2015 GST_ALL_Byte4 "20.03.05";
BA_ "UserSigValidity" SG_ 2015 GST_ALL_Byte4 3;
BA_ "UsrSigPurpose" SG_ 2015 GST_ALL_Byte5 2;
BA_ "Version" SG_ 2015 GST_ALL_Byte5 "20.03.05";
BA_ "UserSigValidity" SG_ 2015 GST_ALL_Byte5 3;
BA_ "UsrSigPurpose" SG_ 2015 GST_ALL_Byte6 2;
BA_ "Version" SG_ 2015 GST_ALL_Byte6 "20.03.05";
BA_ "UserSigValidity" SG_ 2015 GST_ALL_Byte6 3;
BA_ "UsrSigPurpose" SG_ 2015 GST_ALL_Byte7 2;
BA_ "Version" SG_ 2015 GST_ALL_Byte7 "20.03.05";
BA_ "UserSigValidity" SG_ 2015 GST_ALL_Byte7 3;
VAL_ 452 FLR_ST4_Elevation 0 " Unknown" 1 " NotReady" 2 " Overridable" 3 " Relevant" 4 " Underridable" 5 " NoDecision" ;
VAL_ 452 FLR_ST4_PropertyBits 0 " None" 1 " Active" 2 " Zombie" 3 " ActiveAndZombie" 4 " SlowMoving" 5 " ActiveAndSlowMoving" 6 " ZombieAndSlowMoving" 7 " ActiveZombieAndSlowMoving" ;
VAL_ 452 FLR_ST4_Quality 0 " Unknown" 1 " Low" 2 " Medium" 3 " High" ;
VAL_ 453 FLR_ST5_Elevation 0 " Unknown" 1 " NotReady" 2 " Overridable" 3 " Relevant" 4 " Underridable" 5 " NoDecision" ;
VAL_ 453 FLR_ST5_PropertyBits 0 " None" 1 " Active" 2 " Zombie" 3 " ActiveAndZombie" 4 " SlowMoving" 5 " ActiveAndSlowMoving" 6 " ZombieAndSlowMoving" 7 " ActiveZombieAndSlowMoving" ;
VAL_ 453 FLR_ST5_Quality 0 " Unknown" 1 " Low" 2 " Medium" 3 " High" ;
VAL_ 454 FLR_ST6_Elevation 0 " Unknown" 1 " NotReady" 2 " Overridable" 3 " Relevant" 4 " Underridable" 5 " NoDecision" ;
VAL_ 454 FLR_ST6_PropertyBits 0 " None" 1 " Active" 2 " Zombie" 3 " ActiveAndZombie" 4 " SlowMoving" 5 " ActiveAndSlowMoving" 6 " ZombieAndSlowMoving" 7 " ActiveZombieAndSlowMoving" ;
VAL_ 454 FLR_ST6_Quality 0 " Unknown" 1 " Low" 2 " Medium" 3 " High" ;
VAL_ 455 FLR_ST7_Elevation 0 " Unknown" 1 " NotReady" 2 " Overridable" 3 " Relevant" 4 " Underridable" 5 " NoDecision" ;
VAL_ 455 FLR_ST7_PropertyBits 0 " None" 1 " Active" 2 " Zombie" 3 " ActiveAndZombie" 4 " SlowMoving" 5 " ActiveAndSlowMoving" 6 " ZombieAndSlowMoving" 7 " ActiveZombieAndSlowMoving" ;
VAL_ 455 FLR_ST7_Quality 0 " Unknown" 1 " Low" 2 " Medium" 3 " High" ;
VAL_ 456 FLR_ST8_Elevation 0 " Unknown" 1 " NotReady" 2 " Overridable" 3 " Relevant" 4 " Underridable" 5 " NoDecision" ;
VAL_ 456 FLR_ST8_PropertyBits 0 " None" 1 " Active" 2 " Zombie" 3 " ActiveAndZombie" 4 " SlowMoving" 5 " ActiveAndSlowMoving" 6 " ZombieAndSlowMoving" 7 " ActiveZombieAndSlowMoving" ;
VAL_ 456 FLR_ST8_Quality 0 " Unknown" 1 " Low" 2 " Medium" 3 " High" ;
VAL_ 457 FLR_ST9_Elevation 0 " Unknown" 1 " NotReady" 2 " Overridable" 3 " Relevant" 4 " Underridable" 5 " NoDecision" ;
VAL_ 457 FLR_ST9_PropertyBits 0 " None" 1 " Active" 2 " Zombie" 3 " ActiveAndZombie" 4 " SlowMoving" 5 " ActiveAndSlowMoving" 6 " ZombieAndSlowMoving" 7 " ActiveZombieAndSlowMoving" ;
VAL_ 457 FLR_ST9_Quality 0 " Unknown" 1 " Low" 2 " Medium" 3 " High" ;
VAL_ 458 FLR_ST10_Elevation 0 " Unknown" 1 " NotReady" 2 " Overridable" 3 " Relevant" 4 " Underridable" 5 " NoDecision" ;
VAL_ 458 FLR_ST10_PropertyBits 0 " None" 1 " Active" 2 " Zombie" 3 " ActiveAndZombie" 4 " SlowMoving" 5 " ActiveAndSlowMoving" 6 " ZombieAndSlowMoving" 7 " ActiveZombieAndSlowMoving" ;
VAL_ 458 FLR_ST10_Quality 0 " Unknown" 1 " Low" 2 " Medium" 3 " High" ;
VAL_ 459 FLR_ST11_Elevation 0 " Unknown" 1 " NotReady" 2 " Overridable" 3 " Relevant" 4 " Underridable" 5 " NoDecision" ;
VAL_ 459 FLR_ST11_PropertyBits 0 " None" 1 " Active" 2 " Zombie" 3 " ActiveAndZombie" 4 " SlowMoving" 5 " ActiveAndSlowMoving" 6 " ZombieAndSlowMoving" 7 " ActiveZombieAndSlowMoving" ;
VAL_ 459 FLR_ST11_Quality 0 " Unknown" 1 " Low" 2 " Medium" 3 " High" ;
VAL_ 460 FLR_ST12_Elevation 0 " Unknown" 1 " NotReady" 2 " Overridable" 3 " Relevant" 4 " Underridable" 5 " NoDecision" ;
VAL_ 460 FLR_ST12_PropertyBits 0 " None" 1 " Active" 2 " Zombie" 3 " ActiveAndZombie" 4 " SlowMoving" 5 " ActiveAndSlowMoving" 6 " ZombieAndSlowMoving" 7 " ActiveZombieAndSlowMoving" ;
VAL_ 460 FLR_ST12_Quality 0 " Unknown" 1 " Low" 2 " Medium" 3 " High" ;
VAL_ 461 FLR_ST13_Elevation 0 " Unknown" 1 " NotReady" 2 " Overridable" 3 " Relevant" 4 " Underridable" 5 " NoDecision" ;
VAL_ 461 FLR_ST13_PropertyBits 0 " None" 1 " Active" 2 " Zombie" 3 " ActiveAndZombie" 4 " SlowMoving" 5 " ActiveAndSlowMoving" 6 " ZombieAndSlowMoving" 7 " ActiveZombieAndSlowMoving" ;
VAL_ 461 FLR_ST13_Quality 0 " Unknown" 1 " Low" 2 " Medium" 3 " High" ;
VAL_ 462 FLR_ST14_Elevation 0 " Unknown" 1 " NotReady" 2 " Overridable" 3 " Relevant" 4 " Underridable" 5 " NoDecision" ;
VAL_ 462 FLR_ST14_PropertyBits 0 " None" 1 " Active" 2 " Zombie" 3 " ActiveAndZombie" 4 " SlowMoving" 5 " ActiveAndSlowMoving" 6 " ZombieAndSlowMoving" 7 " ActiveZombieAndSlowMoving" ;
VAL_ 462 FLR_ST14_Quality 0 " Unknown" 1 " Low" 2 " Medium" 3 " High" ;
VAL_ 463 FLR_ST15_Elevation 0 " Unknown" 1 " NotReady" 2 " Overridable" 3 " Relevant" 4 " Underridable" 5 " NoDecision" ;
VAL_ 463 FLR_ST15_PropertyBits 0 " None" 1 " Active" 2 " Zombie" 3 " ActiveAndZombie" 4 " SlowMoving" 5 " ActiveAndSlowMoving" 6 " ZombieAndSlowMoving" 7 " ActiveZombieAndSlowMoving" ;
VAL_ 463 FLR_ST15_Quality 0 " Unknown" 1 " Low" 2 " Medium" 3 " High" ;
VAL_ 464 FLR_ST16_Elevation 0 " Unknown" 1 " NotReady" 2 " Overridable" 3 " Relevant" 4 " Underridable" 5 " NoDecision" ;
VAL_ 464 FLR_ST16_PropertyBits 0 " None" 1 " Active" 2 " Zombie" 3 " ActiveAndZombie" 4 " SlowMoving" 5 " ActiveAndSlowMoving" 6 " ZombieAndSlowMoving" 7 " ActiveZombieAndSlowMoving" ;
VAL_ 464 FLR_ST16_Quality 0 " Unknown" 1 " Low" 2 " Medium" 3 " High" ;
VAL_ 465 FLR_ST17_Elevation 0 " Unknown" 1 " NotReady" 2 " Overridable" 3 " Relevant" 4 " Underridable" 5 " NoDecision" ;
VAL_ 465 FLR_ST17_PropertyBits 0 " None" 1 " Active" 2 " Zombie" 3 " ActiveAndZombie" 4 " SlowMoving" 5 " ActiveAndSlowMoving" 6 " ZombieAndSlowMoving" 7 " ActiveZombieAndSlowMoving" ;
VAL_ 465 FLR_ST17_Quality 0 " Unknown" 1 " Low" 2 " Medium" 3 " High" ;
VAL_ 466 FLR_ST18_Elevation 0 " Unknown" 1 " NotReady" 2 " Overridable" 3 " Relevant" 4 " Underridable" 5 " NoDecision" ;
VAL_ 466 FLR_ST18_PropertyBits 0 " None" 1 " Active" 2 " Zombie" 3 " ActiveAndZombie" 4 " SlowMoving" 5 " ActiveAndSlowMoving" 6 " ZombieAndSlowMoving" 7 " ActiveZombieAndSlowMoving" ;
VAL_ 466 FLR_ST18_Quality 0 " Unknown" 1 " Low" 2 " Medium" 3 " High" ;
VAL_ 467 FLR_ST19_Elevation 0 " Unknown" 1 " NotReady" 2 " Overridable" 3 " Relevant" 4 " Underridable" 5 " NoDecision" ;
VAL_ 467 FLR_ST19_PropertyBits 0 " None" 1 " Active" 2 " Zombie" 3 " ActiveAndZombie" 4 " SlowMoving" 5 " ActiveAndSlowMoving" 6 " ZombieAndSlowMoving" 7 " ActiveZombieAndSlowMoving" ;
VAL_ 467 FLR_ST19_Quality 0 " Unknown" 1 " Low" 2 " Medium" 3 " High" ;
VAL_ 468 FLR_ST20_Elevation 0 " Unknown" 1 " NotReady" 2 " Overridable" 3 " Relevant" 4 " Underridable" 5 " NoDecision" ;
VAL_ 468 FLR_ST20_PropertyBits 0 " None" 1 " Active" 2 " Zombie" 3 " ActiveAndZombie" 4 " SlowMoving" 5 " ActiveAndSlowMoving" 6 " ZombieAndSlowMoving" 7 " ActiveZombieAndSlowMoving" ;
VAL_ 468 FLR_ST20_Quality 0 " Unknown" 1 " Low" 2 " Medium" 3 " High" ;
VAL_ 469 FLR_ST21_Elevation 0 " Unknown" 1 " NotReady" 2 " Overridable" 3 " Relevant" 4 " Underridable" 5 " NoDecision" ;
VAL_ 469 FLR_ST21_PropertyBits 0 " None" 1 " Active" 2 " Zombie" 3 " ActiveAndZombie" 4 " SlowMoving" 5 " ActiveAndSlowMoving" 6 " ZombieAndSlowMoving" 7 " ActiveZombieAndSlowMoving" ;
VAL_ 469 FLR_ST21_Quality 0 " Unknown" 1 " Low" 2 " Medium" 3 " High" ;
VAL_ 470 FLR_ST22_Elevation 0 " Unknown" 1 " NotReady" 2 " Overridable" 3 " Relevant" 4 " Underridable" 5 " NoDecision" ;
VAL_ 470 FLR_ST22_PropertyBits 0 " None" 1 " Active" 2 " Zombie" 3 " ActiveAndZombie" 4 " SlowMoving" 5 " ActiveAndSlowMoving" 6 " ZombieAndSlowMoving" 7 " ActiveZombieAndSlowMoving" ;
VAL_ 470 FLR_ST22_Quality 0 " Unknown" 1 " Low" 2 " Medium" 3 " High" ;
VAL_ 471 FLR_ST23_Elevation 0 " Unknown" 1 " NotReady" 2 " Overridable" 3 " Relevant" 4 " Underridable" 5 " NoDecision" ;
VAL_ 471 FLR_ST23_PropertyBits 0 " None" 1 " Active" 2 " Zombie" 3 " ActiveAndZombie" 4 " SlowMoving" 5 " ActiveAndSlowMoving" 6 " ZombieAndSlowMoving" 7 " ActiveZombieAndSlowMoving" ;
VAL_ 471 FLR_ST23_Quality 0 " Unknown" 1 " Low" 2 " Medium" 3 " High" ;
VAL_ 472 FLR_ST24_Elevation 0 " Unknown" 1 " NotReady" 2 " Overridable" 3 " Relevant" 4 " Underridable" 5 " NoDecision" ;
VAL_ 472 FLR_ST24_PropertyBits 0 " None" 1 " Active" 2 " Zombie" 3 " ActiveAndZombie" 4 " SlowMoving" 5 " ActiveAndSlowMoving" 6 " ZombieAndSlowMoving" 7 " ActiveZombieAndSlowMoving" ;
VAL_ 472 FLR_ST24_Quality 0 " Unknown" 1 " Low" 2 " Medium" 3 " High" ;
VAL_ 473 FLR_ST25_Elevation 0 " Unknown" 1 " NotReady" 2 " Overridable" 3 " Relevant" 4 " Underridable" 5 " NoDecision" ;
VAL_ 473 FLR_ST25_PropertyBits 0 " None" 1 " Active" 2 " Zombie" 3 " ActiveAndZombie" 4 " SlowMoving" 5 " ActiveAndSlowMoving" 6 " ZombieAndSlowMoving" 7 " ActiveZombieAndSlowMoving" ;
VAL_ 473 FLR_ST25_Quality 0 " Unknown" 1 " Low" 2 " Medium" 3 " High" ;
VAL_ 474 FLR_ST26_Elevation 0 " Unknown" 1 " NotReady" 2 " Overridable" 3 " Relevant" 4 " Underridable" 5 " NoDecision" ;
VAL_ 474 FLR_ST26_PropertyBits 0 " None" 1 " Active" 2 " Zombie" 3 " ActiveAndZombie" 4 " SlowMoving" 5 " ActiveAndSlowMoving" 6 " ZombieAndSlowMoving" 7 " ActiveZombieAndSlowMoving" ;
VAL_ 474 FLR_ST26_Quality 0 " Unknown" 1 " Low" 2 " Medium" 3 " High" ;
VAL_ 475 FLR_ST27_Elevation 0 " Unknown" 1 " NotReady" 2 " Overridable" 3 " Relevant" 4 " Underridable" 5 " NoDecision" ;
VAL_ 475 FLR_ST27_PropertyBits 0 " None" 1 " Active" 2 " Zombie" 3 " ActiveAndZombie" 4 " SlowMoving" 5 " ActiveAndSlowMoving" 6 " ZombieAndSlowMoving" 7 " ActiveZombieAndSlowMoving" ;
VAL_ 475 FLR_ST27_Quality 0 " Unknown" 1 " Low" 2 " Medium" 3 " High" ;
VAL_ 476 FLR_ST28_Elevation 0 " Unknown" 1 " NotReady" 2 " Overridable" 3 " Relevant" 4 " Underridable" 5 " NoDecision" ;
VAL_ 476 FLR_ST28_PropertyBits 0 " None" 1 " Active" 2 " Zombie" 3 " ActiveAndZombie" 4 " SlowMoving" 5 " ActiveAndSlowMoving" 6 " ZombieAndSlowMoving" 7 " ActiveZombieAndSlowMoving" ;
VAL_ 476 FLR_ST28_Quality 0 " Unknown" 1 " Low" 2 " Medium" 3 " High" ;
VAL_ 477 FLR_ST29_Elevation 0 " Unknown" 1 " NotReady" 2 " Overridable" 3 " Relevant" 4 " Underridable" 5 " NoDecision" ;
VAL_ 477 FLR_ST29_PropertyBits 0 " None" 1 " Active" 2 " Zombie" 3 " ActiveAndZombie" 4 " SlowMoving" 5 " ActiveAndSlowMoving" 6 " ZombieAndSlowMoving" 7 " ActiveZombieAndSlowMoving" ;
VAL_ 477 FLR_ST29_Quality 0 " Unknown" 1 " Low" 2 " Medium" 3 " High" ;
VAL_ 478 FLR_ST30_Elevation 0 " Unknown" 1 " NotReady" 2 " Overridable" 3 " Relevant" 4 " Underridable" 5 " NoDecision" ;
VAL_ 478 FLR_ST30_PropertyBits 0 " None" 1 " Active" 2 " Zombie" 3 " ActiveAndZombie" 4 " SlowMoving" 5 " ActiveAndSlowMoving" 6 " ZombieAndSlowMoving" 7 " ActiveZombieAndSlowMoving" ;
VAL_ 478 FLR_ST30_Quality 0 " Unknown" 1 " Low" 2 " Medium" 3 " High" ;
VAL_ 479 FLR_ST31_Elevation 0 " Unknown" 1 " NotReady" 2 " Overridable" 3 " Relevant" 4 " Underridable" 5 " NoDecision" ;
VAL_ 479 FLR_ST31_PropertyBits 0 " None" 1 " Active" 2 " Zombie" 3 " ActiveAndZombie" 4 " SlowMoving" 5 " ActiveAndSlowMoving" 6 " ZombieAndSlowMoving" 7 " ActiveZombieAndSlowMoving" ;
VAL_ 479 FLR_ST31_Quality 0 " Unknown" 1 " Low" 2 " Medium" 3 " High" ;
VAL_ 480 FLR_ST32_Elevation 0 " Unknown" 1 " NotReady" 2 " Overridable" 3 " Relevant" 4 " Underridable" 5 " NoDecision" ;
VAL_ 480 FLR_ST32_PropertyBits 0 " None" 1 " Active" 2 " Zombie" 3 " ActiveAndZombie" 4 " SlowMoving" 5 " ActiveAndSlowMoving" 6 " ZombieAndSlowMoving" 7 " ActiveZombieAndSlowMoving" ;
VAL_ 480 FLR_ST32_Quality 0 " Unknown" 1 " Low" 2 " Medium" 3 " High" ;
VAL_ 481 FLR_ST33_Elevation 0 " Unknown" 1 " NotReady" 2 " Overridable" 3 " Relevant" 4 " Underridable" 5 " NoDecision" ;
VAL_ 481 FLR_ST33_PropertyBits 0 " None" 1 " Active" 2 " Zombie" 3 " ActiveAndZombie" 4 " SlowMoving" 5 " ActiveAndSlowMoving" 6 " ZombieAndSlowMoving" 7 " ActiveZombieAndSlowMoving" ;
VAL_ 481 FLR_ST33_Quality 0 " Unknown" 1 " Low" 2 " Medium" 3 " High" ;
VAL_ 482 FLR_ST34_Elevation 0 " Unknown" 1 " NotReady" 2 " Overridable" 3 " Relevant" 4 " Underridable" 5 " NoDecision" ;
VAL_ 482 FLR_ST34_PropertyBits 0 " None" 1 " Active" 2 " Zombie" 3 " ActiveAndZombie" 4 " SlowMoving" 5 " ActiveAndSlowMoving" 6 " ZombieAndSlowMoving" 7 " ActiveZombieAndSlowMoving" ;
VAL_ 482 FLR_ST34_Quality 0 " Unknown" 1 " Low" 2 " Medium" 3 " High" ;
VAL_ 483 FLR_ST35_Elevation 0 " Unknown" 1 " NotReady" 2 " Overridable" 3 " Relevant" 4 " Underridable" 5 " NoDecision" ;
VAL_ 483 FLR_ST35_PropertyBits 0 " None" 1 " Active" 2 " Zombie" 3 " ActiveAndZombie" 4 " SlowMoving" 5 " ActiveAndSlowMoving" 6 " ZombieAndSlowMoving" 7 " ActiveZombieAndSlowMoving" ;
VAL_ 483 FLR_ST35_Quality 0 " Unknown" 1 " Low" 2 " Medium" 3 " High" ;
VAL_ 484 FLR_ST36_Elevation 0 " Unknown" 1 " NotReady" 2 " Overridable" 3 " Relevant" 4 " Underridable" 5 " NoDecision" ;
VAL_ 484 FLR_ST36_PropertyBits 0 " None" 1 " Active" 2 " Zombie" 3 " ActiveAndZombie" 4 " SlowMoving" 5 " ActiveAndSlowMoving" 6 " ZombieAndSlowMoving" 7 " ActiveZombieAndSlowMoving" ;
VAL_ 484 FLR_ST36_Quality 0 " Unknown" 1 " Low" 2 " Medium" 3 " High" ;
VAL_ 485 FLR_ST37_Elevation 0 " Unknown" 1 " NotReady" 2 " Overridable" 3 " Relevant" 4 " Underridable" 5 " NoDecision" ;
VAL_ 485 FLR_ST37_PropertyBits 0 " None" 1 " Active" 2 " Zombie" 3 " ActiveAndZombie" 4 " SlowMoving" 5 " ActiveAndSlowMoving" 6 " ZombieAndSlowMoving" 7 " ActiveZombieAndSlowMoving" ;
VAL_ 485 FLR_ST37_Quality 0 " Unknown" 1 " Low" 2 " Medium" 3 " High" ;
VAL_ 486 FLR_ST38_Elevation 0 " Unknown" 1 " NotReady" 2 " Overridable" 3 " Relevant" 4 " Underridable" 5 " NoDecision" ;
VAL_ 486 FLR_ST38_PropertyBits 0 " None" 1 " Active" 2 " Zombie" 3 " ActiveAndZombie" 4 " SlowMoving" 5 " ActiveAndSlowMoving" 6 " ZombieAndSlowMoving" 7 " ActiveZombieAndSlowMoving" ;
VAL_ 486 FLR_ST38_Quality 0 " Unknown" 1 " Low" 2 " Medium" 3 " High" ;
VAL_ 487 FLR_ST39_Elevation 0 " Unknown" 1 " NotReady" 2 " Overridable" 3 " Relevant" 4 " Underridable" 5 " NoDecision" ;
VAL_ 487 FLR_ST39_PropertyBits 0 " None" 1 " Active" 2 " Zombie" 3 " ActiveAndZombie" 4 " SlowMoving" 5 " ActiveAndSlowMoving" 6 " ZombieAndSlowMoving" 7 " ActiveZombieAndSlowMoving" ;
VAL_ 487 FLR_ST39_Quality 0 " Unknown" 1 " Low" 2 " Medium" 3 " High" ;
SIG_GROUP_ 452 L_FR_RDR_StationaryTrack4_50ms 1 : FLR_ST4_CrcVal FLR_ST4_AlvCntVal FLR_ST4_Elevation FLR_ST4_ElevationConfidence FLR_ST4_Lifetime FLR_ST4_ObjectId FLR_ST4_PositionX FLR_ST4_PositionY FLR_ST4_PredictionCounter FLR_ST4_PropertyBits FLR_ST4_Quality FLR_ST4_X_Velocity FLR_ST4_Y_Velocity;
SIG_GROUP_ 453 L_FR_RDR_StationaryTrack5_50ms 1 : FLR_ST5_CrcVal FLR_ST5_AlvCntVal FLR_ST5_Elevation FLR_ST5_ElevationConfidence FLR_ST5_Lifetime FLR_ST5_ObjectId FLR_ST5_PositionX FLR_ST5_PositionY FLR_ST5_PredictionCounter FLR_ST5_PropertyBits FLR_ST5_Quality FLR_ST5_X_Velocity FLR_ST5_Y_Velocity;
SIG_GROUP_ 454 L_FR_RDR_StationaryTrack6_50ms 1 : FLR_ST6_CrcVal FLR_ST6_AlvCntVal FLR_ST6_Elevation FLR_ST6_ElevationConfidence FLR_ST6_Lifetime FLR_ST6_ObjectId FLR_ST6_PositionX FLR_ST6_PositionY FLR_ST6_PredictionCounter FLR_ST6_PropertyBits FLR_ST6_Quality FLR_ST6_X_Velocity FLR_ST6_Y_Velocity;
SIG_GROUP_ 455 L_FR_RDR_StationaryTrack7_50ms 1 : FLR_ST7_CrcVal FLR_ST7_AlvCntVal FLR_ST7_Elevation FLR_ST7_ElevationConfidence FLR_ST7_Lifetime FLR_ST7_ObjectId FLR_ST7_PositionX FLR_ST7_PositionY FLR_ST7_PredictionCounter FLR_ST7_PropertyBits FLR_ST7_Quality FLR_ST7_X_Velocity FLR_ST7_Y_Velocity;
SIG_GROUP_ 456 L_FR_RDR_StationaryTrack8_50ms 1 : FLR_ST8_CrcVal FLR_ST8_AlvCntVal FLR_ST8_Elevation FLR_ST8_ElevationConfidence FLR_ST8_Lifetime FLR_ST8_ObjectId FLR_ST8_PositionX FLR_ST8_PositionY FLR_ST8_PredictionCounter FLR_ST8_PropertyBits FLR_ST8_Quality FLR_ST8_X_Velocity FLR_ST8_Y_Velocity;
SIG_GROUP_ 457 L_FR_RDR_StationaryTrack9_50ms 1 : FLR_ST9_CrcVal FLR_ST9_AlvCntVal FLR_ST9_Elevation FLR_ST9_ElevationConfidence FLR_ST9_Lifetime FLR_ST9_ObjectId FLR_ST9_PositionX FLR_ST9_PositionY FLR_ST9_PredictionCounter FLR_ST9_PropertyBits FLR_ST9_Quality FLR_ST9_X_Velocity FLR_ST9_Y_Velocity;
SIG_GROUP_ 458 L_FR_RDR_StationaryTrack10_50ms 1 : FLR_ST10_CrcVal FLR_ST10_AlvCntVal FLR_ST10_Elevation FLR_ST10_ElevationConfidence FLR_ST10_Lifetime FLR_ST10_ObjectId FLR_ST10_PositionX FLR_ST10_PositionY FLR_ST10_PredictionCounter FLR_ST10_PropertyBits FLR_ST10_Quality FLR_ST10_X_Velocity FLR_ST10_Y_Velocity;
SIG_GROUP_ 459 L_FR_RDR_StationaryTrack11_50ms 1 : FLR_ST11_CrcVal FLR_ST11_AlvCntVal FLR_ST11_Elevation FLR_ST11_ElevationConfidence FLR_ST11_Lifetime FLR_ST11_ObjectId FLR_ST11_PositionX FLR_ST11_PositionY FLR_ST11_PredictionCounter FLR_ST11_PropertyBits FLR_ST11_Quality FLR_ST11_X_Velocity FLR_ST11_Y_Velocity;
SIG_GROUP_ 460 L_FR_RDR_StationaryTrack12_50ms 1 : FLR_ST12_CrcVal FLR_ST12_AlvCntVal FLR_ST12_Elevation FLR_ST12_ElevationConfidence FLR_ST12_Lifetime FLR_ST12_ObjectId FLR_ST12_PositionX FLR_ST12_PositionY FLR_ST12_PredictionCounter FLR_ST12_PropertyBits FLR_ST12_Quality FLR_ST12_X_Velocity FLR_ST12_Y_Velocity;
SIG_GROUP_ 461 L_FR_RDR_StationaryTrack13_50ms 1 : FLR_ST13_CrcVal FLR_ST13_AlvCntVal FLR_ST13_Elevation FLR_ST13_ElevationConfidence FLR_ST13_Lifetime FLR_ST13_ObjectId FLR_ST13_PositionX FLR_ST13_PositionY FLR_ST13_PredictionCounter FLR_ST13_PropertyBits FLR_ST13_Quality FLR_ST13_X_Velocity FLR_ST13_Y_Velocity;
SIG_GROUP_ 462 L_FR_RDR_StationaryTrack14_50ms 1 : FLR_ST14_CrcVal FLR_ST14_AlvCntVal FLR_ST14_Elevation FLR_ST14_ElevationConfidence FLR_ST14_Lifetime FLR_ST14_ObjectId FLR_ST14_PositionX FLR_ST14_PositionY FLR_ST14_PredictionCounter FLR_ST14_PropertyBits FLR_ST14_Quality FLR_ST14_X_Velocity FLR_ST14_Y_Velocity;
SIG_GROUP_ 463 L_FR_RDR_StationaryTrack15_50ms 1 : FLR_ST15_CrcVal FLR_ST15_AlvCntVal FLR_ST15_Elevation FLR_ST15_ElevationConfidence FLR_ST15_Lifetime FLR_ST15_ObjectId FLR_ST15_PositionX FLR_ST15_PositionY FLR_ST15_PredictionCounter FLR_ST15_PropertyBits FLR_ST15_Quality FLR_ST15_X_Velocity FLR_ST15_Y_Velocity;
SIG_GROUP_ 464 L_FR_RDR_StationaryTrack16_50ms 1 : FLR_ST16_CrcVal FLR_ST16_AlvCntVal FLR_ST16_Elevation FLR_ST16_ElevationConfidence FLR_ST16_Lifetime FLR_ST16_ObjectId FLR_ST16_PositionX FLR_ST16_PositionY FLR_ST16_PredictionCounter FLR_ST16_PropertyBits FLR_ST16_Quality FLR_ST16_X_Velocity FLR_ST16_Y_Velocity;
SIG_GROUP_ 465 L_FR_RDR_StationaryTrack17_50ms 1 : FLR_ST17_CrcVal FLR_ST17_AlvCntVal FLR_ST17_Elevation FLR_ST17_ElevationConfidence FLR_ST17_Lifetime FLR_ST17_ObjectId FLR_ST17_PositionX FLR_ST17_PositionY FLR_ST17_PredictionCounter FLR_ST17_PropertyBits FLR_ST17_Quality FLR_ST17_X_Velocity FLR_ST17_Y_Velocity;
SIG_GROUP_ 466 L_FR_RDR_StationaryTrack18_50ms 1 : FLR_ST18_CrcVal FLR_ST18_AlvCntVal FLR_ST18_Elevation FLR_ST18_ElevationConfidence FLR_ST18_Lifetime FLR_ST18_ObjectId FLR_ST18_PositionX FLR_ST18_PositionY FLR_ST18_PredictionCounter FLR_ST18_PropertyBits FLR_ST18_Quality FLR_ST18_X_Velocity FLR_ST18_Y_Velocity;
SIG_GROUP_ 467 L_FR_RDR_StationaryTrack19_50ms 1 : FLR_ST19_CrcVal FLR_ST19_AlvCntVal FLR_ST19_Elevation FLR_ST19_ElevationConfidence FLR_ST19_Lifetime FLR_ST19_ObjectId FLR_ST19_PositionX FLR_ST19_PositionY FLR_ST19_PredictionCounter FLR_ST19_PropertyBits FLR_ST19_Quality FLR_ST19_X_Velocity FLR_ST19_Y_Velocity;
SIG_GROUP_ 468 L_FR_RDR_StationaryTrack20_50ms 1 : FLR_ST20_CrcVal FLR_ST20_AlvCntVal FLR_ST20_Elevation FLR_ST20_ElevationConfidence FLR_ST20_Lifetime FLR_ST20_ObjectId FLR_ST20_PositionX FLR_ST20_PositionY FLR_ST20_PredictionCounter FLR_ST20_PropertyBits FLR_ST20_Quality FLR_ST20_X_Velocity FLR_ST20_Y_Velocity;
SIG_GROUP_ 469 L_FR_RDR_StationaryTrack21_50ms 1 : FLR_ST21_CrcVal FLR_ST21_AlvCntVal FLR_ST21_Elevation FLR_ST21_ElevationConfidence FLR_ST21_Lifetime FLR_ST21_ObjectId FLR_ST21_PositionX FLR_ST21_PositionY FLR_ST21_PredictionCounter FLR_ST21_PropertyBits FLR_ST21_Quality FLR_ST21_X_Velocity FLR_ST21_Y_Velocity;
SIG_GROUP_ 470 L_FR_RDR_StationaryTrack22_50ms 1 : FLR_ST22_CrcVal FLR_ST22_AlvCntVal FLR_ST22_Elevation FLR_ST22_ElevationConfidence FLR_ST22_Lifetime FLR_ST22_ObjectId FLR_ST22_PositionX FLR_ST22_PositionY FLR_ST22_PredictionCounter FLR_ST22_PropertyBits FLR_ST22_Quality FLR_ST22_X_Velocity FLR_ST22_Y_Velocity;
SIG_GROUP_ 471 L_FR_RDR_StationaryTrack23_50ms 1 : FLR_ST23_CrcVal FLR_ST23_AlvCntVal FLR_ST23_Elevation FLR_ST23_ElevationConfidence FLR_ST23_Lifetime FLR_ST23_ObjectId FLR_ST23_PositionX FLR_ST23_PositionY FLR_ST23_PredictionCounter FLR_ST23_PropertyBits FLR_ST23_Quality FLR_ST23_X_Velocity FLR_ST23_Y_Velocity;
SIG_GROUP_ 472 L_FR_RDR_StationaryTrack24_50ms 1 : FLR_ST24_CrcVal FLR_ST24_AlvCntVal FLR_ST24_Elevation FLR_ST24_ElevationConfidence FLR_ST24_Lifetime FLR_ST24_ObjectId FLR_ST24_PositionX FLR_ST24_PositionY FLR_ST24_PredictionCounter FLR_ST24_PropertyBits FLR_ST24_Quality FLR_ST24_X_Velocity FLR_ST24_Y_Velocity;
SIG_GROUP_ 473 L_FR_RDR_StationaryTrack25_50ms 1 : FLR_ST25_CrcVal FLR_ST25_AlvCntVal FLR_ST25_Elevation FLR_ST25_ElevationConfidence FLR_ST25_Lifetime FLR_ST25_ObjectId FLR_ST25_PositionX FLR_ST25_PositionY FLR_ST25_PredictionCounter FLR_ST25_PropertyBits FLR_ST25_Quality FLR_ST25_X_Velocity FLR_ST25_Y_Velocity;
SIG_GROUP_ 474 L_FR_RDR_StationaryTrack26_50ms 1 : FLR_ST26_CrcVal FLR_ST26_AlvCntVal FLR_ST26_Elevation FLR_ST26_ElevationConfidence FLR_ST26_Lifetime FLR_ST26_ObjectId FLR_ST26_PositionX FLR_ST26_PositionY FLR_ST26_PredictionCounter FLR_ST26_PropertyBits FLR_ST26_Quality FLR_ST26_X_Velocity FLR_ST26_Y_Velocity;
SIG_GROUP_ 475 L_FR_RDR_StationaryTrack27_50ms 1 : FLR_ST27_CrcVal FLR_ST27_AlvCntVal FLR_ST27_Elevation FLR_ST27_ElevationConfidence FLR_ST27_Lifetime FLR_ST27_ObjectId FLR_ST27_PositionX FLR_ST27_PositionY FLR_ST27_PredictionCounter FLR_ST27_PropertyBits FLR_ST27_Quality FLR_ST27_X_Velocity FLR_ST27_Y_Velocity;
SIG_GROUP_ 476 L_FR_RDR_StationaryTrack28_50ms 1 : FLR_ST28_CrcVal FLR_ST28_AlvCntVal FLR_ST28_Elevation FLR_ST28_ElevationConfidence FLR_ST28_Lifetime FLR_ST28_ObjectId FLR_ST28_PositionX FLR_ST28_PositionY FLR_ST28_PredictionCounter FLR_ST28_PropertyBits FLR_ST28_Quality FLR_ST28_X_Velocity FLR_ST28_Y_Velocity;
SIG_GROUP_ 477 L_FR_RDR_StationaryTrack29_50ms 1 : FLR_ST29_CrcVal FLR_ST29_AlvCntVal FLR_ST29_Elevation FLR_ST29_ElevationConfidence FLR_ST29_Lifetime FLR_ST29_ObjectId FLR_ST29_PositionX FLR_ST29_PositionY FLR_ST29_PredictionCounter FLR_ST29_PropertyBits FLR_ST29_Quality FLR_ST29_X_Velocity FLR_ST29_Y_Velocity;
SIG_GROUP_ 478 L_FR_RDR_StationaryTrack30_50ms 1 : FLR_ST30_CrcVal FLR_ST30_AlvCntVal FLR_ST30_Elevation FLR_ST30_ElevationConfidence FLR_ST30_Lifetime FLR_ST30_ObjectId FLR_ST30_PositionX FLR_ST30_PositionY FLR_ST30_PredictionCounter FLR_ST30_PropertyBits FLR_ST30_Quality FLR_ST30_X_Velocity FLR_ST30_Y_Velocity;
SIG_GROUP_ 479 L_FR_RDR_StationaryTrack31_50ms 1 : FLR_ST31_CrcVal FLR_ST31_AlvCntVal FLR_ST31_Elevation FLR_ST31_ElevationConfidence FLR_ST31_Lifetime FLR_ST31_ObjectId FLR_ST31_PositionX FLR_ST31_PositionY FLR_ST31_PredictionCounter FLR_ST31_PropertyBits FLR_ST31_Quality FLR_ST31_X_Velocity FLR_ST31_Y_Velocity;
SIG_GROUP_ 480 L_FR_RDR_StationaryTrack32_50ms 1 : FLR_ST32_CrcVal FLR_ST32_AlvCntVal FLR_ST32_Elevation FLR_ST32_ElevationConfidence FLR_ST32_Lifetime FLR_ST32_ObjectId FLR_ST32_PositionX FLR_ST32_PositionY FLR_ST32_PredictionCounter FLR_ST32_PropertyBits FLR_ST32_Quality FLR_ST32_X_Velocity FLR_ST32_Y_Velocity;
SIG_GROUP_ 481 L_FR_RDR_StationaryTrack33_50ms 1 : FLR_ST33_CrcVal FLR_ST33_AlvCntVal FLR_ST33_Elevation FLR_ST33_ElevationConfidence FLR_ST33_Lifetime FLR_ST33_ObjectId FLR_ST33_PositionX FLR_ST33_PositionY FLR_ST33_PredictionCounter FLR_ST33_PropertyBits FLR_ST33_Quality FLR_ST33_X_Velocity FLR_ST33_Y_Velocity;
SIG_GROUP_ 482 L_FR_RDR_StationaryTrack34_50ms 1 : FLR_ST34_CrcVal FLR_ST34_AlvCntVal FLR_ST34_Elevation FLR_ST34_ElevationConfidence FLR_ST34_Lifetime FLR_ST34_ObjectId FLR_ST34_PositionX FLR_ST34_PositionY FLR_ST34_PredictionCounter FLR_ST34_PropertyBits FLR_ST34_Quality FLR_ST34_X_Velocity FLR_ST34_Y_Velocity;
SIG_GROUP_ 483 L_FR_RDR_StationaryTrack35_50ms 1 : FLR_ST35_CrcVal FLR_ST35_AlvCntVal FLR_ST35_Elevation FLR_ST35_ElevationConfidence FLR_ST35_Lifetime FLR_ST35_ObjectId FLR_ST35_PositionX FLR_ST35_PositionY FLR_ST35_PredictionCounter FLR_ST35_PropertyBits FLR_ST35_Quality FLR_ST35_X_Velocity FLR_ST35_Y_Velocity;
SIG_GROUP_ 484 L_FR_RDR_StationaryTrack36_50ms 1 : FLR_ST36_CrcVal FLR_ST36_AlvCntVal FLR_ST36_Elevation FLR_ST36_ElevationConfidence FLR_ST36_Lifetime FLR_ST36_ObjectId FLR_ST36_PositionX FLR_ST36_PositionY FLR_ST36_PredictionCounter FLR_ST36_PropertyBits FLR_ST36_Quality FLR_ST36_X_Velocity FLR_ST36_Y_Velocity;
SIG_GROUP_ 485 L_FR_RDR_StationaryTrack37_50ms 1 : FLR_ST37_CrcVal FLR_ST37_AlvCntVal FLR_ST37_Elevation FLR_ST37_ElevationConfidence FLR_ST37_Lifetime FLR_ST37_ObjectId FLR_ST37_PositionX FLR_ST37_PositionY FLR_ST37_PredictionCounter FLR_ST37_PropertyBits FLR_ST37_Quality FLR_ST37_X_Velocity FLR_ST37_Y_Velocity;
SIG_GROUP_ 486 L_FR_RDR_StationaryTrack38_50ms 1 : FLR_ST38_CrcVal FLR_ST38_AlvCntVal FLR_ST38_Elevation FLR_ST38_ElevationConfidence FLR_ST38_Lifetime FLR_ST38_ObjectId FLR_ST38_PositionX FLR_ST38_PositionY FLR_ST38_PredictionCounter FLR_ST38_PropertyBits FLR_ST38_Quality FLR_ST38_X_Velocity FLR_ST38_Y_Velocity;
SIG_GROUP_ 487 L_FR_RDR_StationaryTrack39_50ms 1 : FLR_ST39_CrcVal FLR_ST39_AlvCntVal FLR_ST39_Elevation FLR_ST39_ElevationConfidence FLR_ST39_Lifetime FLR_ST39_ObjectId FLR_ST39_PositionX FLR_ST39_PositionY FLR_ST39_PredictionCounter FLR_ST39_PropertyBits FLR_ST39_Quality FLR_ST39_X_Velocity FLR_ST39_Y_Velocity;
SIG_GROUP_ 1752 XCP_Tester_to_FLR 1 : XCP_Tester_to_FLR_Sig;
SIG_GROUP_ 1753 XCP_FLR_to_Tester 1 : XCP_FLR_to_Tester_Sig;
SIG_GROUP_ 2000 GST_FR_RDR 1 : GST_FR_RDR_Byte0 GST_FR_RDR_Byte1 GST_FR_RDR_Byte2 GST_FR_RDR_Byte3 GST_FR_RDR_Byte4 GST_FR_RDR_Byte5 GST_FR_RDR_Byte6 GST_FR_RDR_Byte7;
SIG_GROUP_ 2008 FR_RDR_GST 1 : FR_RDR_GST_Byte0 FR_RDR_GST_Byte1 FR_RDR_GST_Byte2 FR_RDR_GST_Byte3 FR_RDR_GST_Byte4 FR_RDR_GST_Byte5 FR_RDR_GST_Byte6 FR_RDR_GST_Byte7;
SIG_GROUP_ 2015 GST_ALL 1 : GST_ALL_Byte0 GST_ALL_Byte1 GST_ALL_Byte2 GST_ALL_Byte3 GST_ALL_Byte4 GST_ALL_Byte5 GST_ALL_Byte6 GST_ALL_Byte7;
